VERSION "HNNBNNNYNNNNNNNNNNNNNNNNNNNNNNNNNNNNNNNNNN/4/%%%/4/'%**4NNN///"

NS_ :

BS_:

BU_: BAP_Tester BCM Gateway_Max TSGGen3_BFS TSGGen3_FS TSGGen3_HBFS TSGGen3_HFS WLC_01_CFD

BO_ 1031 PLA_04: 8 Gateway_Max
 SG_ PLA_04_CRC : 0|8@1+ (1,0) [0|255] ""  BCM
 SG_ PLA_04_BZ : 8|4@1+ (1,0) [0|15] ""  BCM
 SG_ PLAIPA_PaCo_ParkingSlots_02 : 12|4@1+ (1.0,0.0) [0.0|15] ""  Vector__XXX
 SG_ RA_PaCo_MainState : 19|3@1+ (1.0,0.0) [0.0|7] ""  Vector__XXX
 SG_ RA_PaCo_FunctionState : 22|4@1+ (1.0,0.0) [0.0|15] ""  Vector__XXX
 SG_ RA_PaCo_InterventionPossible : 26|3@1+ (1.0,0.0) [0.0|7] ""  Vector__XXX
 SG_ RA_PaCo_UnavailableReason : 29|4@1+ (1.0,0.0) [0.0|15] ""  Vector__XXX
 SG_ PLAIPA_PaCo_RemoteActivatable : 33|3@1+ (1.0,0.0) [0.0|7] ""  Vector__XXX
 SG_ PLAIPA_PaCo_GarageActivatable : 36|1@1+ (1.0,0.0) [0.0|1] ""  Vector__XXX
 SG_ RPA_Anf_Sonder_Funktion_Status : 37|3@1+ (1.0,0.0) [0.0|7] ""  BCM
 SG_ RPA_Anf_Sonder_Klemme_15 : 40|2@1+ (1.0,0.0) [0.0|3] ""  BCM
 SG_ RPA_Anf_WFS_Freigabe : 42|2@1+ (1.0,0.0) [0.0|3] ""  BCM
 SG_ PLAIPA_PaCo_SwitchPossible : 44|1@1+ (1.0,0.0) [0.0|1] ""  Vector__XXX
 SG_ PLAIPA_PaCo_ParkingSlots : 45|3@1+ (1.0,0.0) [0.0|7] ""  Vector__XXX
 SG_ PLAIPA_PaCo_UnavailableReason : 48|4@1+ (1.0,0.0) [0.0|15] ""  Vector__XXX
 SG_ PLAIPA_PaCo_InterventionPossible : 52|1@1+ (1.0,0.0) [0.0|1] ""  Vector__XXX
 SG_ PLAIPA_PaCo_MainState : 53|3@1+ (1.0,0.0) [0.0|7] ""  Vector__XXX
 SG_ PLAIPA_PaCo_FunctionState : 56|5@1+ (1.0,0.0) [0.0|31] ""  Vector__XXX
 SG_ PLAIPA_PaCo_PLEPossible : 61|1@1+ (1.0,0.0) [0.0|1] ""  Vector__XXX
 SG_ PLAIPA_PaCo_Button : 62|2@1+ (1.0,0.0) [0.0|3] ""  Vector__XXX

BO_ 319 PreCrash_02: 8 Gateway_Max
 SG_ PreCrash_Charisma_FahrPr : 12|4@1+ (1.0,0.0) [0.0|15] ""  Vector__XXX
 SG_ PreCrash_Charisma_Status : 16|2@1+ (1.0,0.0) [0.0|3] ""  Vector__XXX
 SG_ PreCrash_Schiebedach_schliessen : 18|1@1+ (1.0,0.0) [0.0|1] ""  Vector__XXX
 SG_ PreCrash_Fenster_schliessen : 19|1@1+ (1.0,0.0) [0.0|1] ""  TSGGen3_BFS,TSGGen3_FS,TSGGen3_HBFS,TSGGen3_HFS
 SG_ PreCrash_Blinken : 20|3@1+ (1.0,0.0) [0.0|7] ""  BCM
 SG_ SC_PreSense_FCWP : 23|1@1+ (1.0,0.0) [0.0|1] ""  Vector__XXX
 SG_ PreCrash_Tueren_Verriegeln : 24|1@1+ (1.0,0.0) [0.0|1] ""  BCM,TSGGen3_BFS,TSGGen3_FS,TSGGen3_HBFS,TSGGen3_HFS
 SG_ PreCrash_FS_Laengsverstellung : 25|1@1+ (1.0,0.0) [0.0|1] ""  Vector__XXX
 SG_ PreCrash_Anforderung_AFR : 26|3@1+ (1.0,0.0) [0.0|7] ""  Vector__XXX
 SG_ SC_PreCrash_LED : 29|2@1+ (1.0,0.0) [0.0|3] ""  Vector__XXX
 SG_ PreCrash_FS_Pneumatik_ansteuern : 31|1@1+ (1.0,0.0) [0.0|1] ""  BCM
 SG_ PreCrash_BFS_Pneumatik_ansteuern : 32|1@1+ (1.0,0.0) [0.0|1] ""  BCM
 SG_ PreCrash_Fo_Pneumatik_ansteuern : 33|1@1+ (1.0,0.0) [0.0|1] ""  Vector__XXX
 SG_ PreCrash_FS_Sitzlehne_verfahren : 34|3@1+ (1.0,0.0) [0.0|7] ""  Vector__XXX
 SG_ PreCrash_BFS_Sitzlehne_verfahren : 37|3@1+ (1.0,0.0) [0.0|7] ""  Vector__XXX
 SG_ PreCrash_Fo_Sitzlehne_verfahren : 40|3@1+ (1.0,0.0) [0.0|7] ""  Vector__XXX
 SG_ PreCrash_FS_KSV_verfahren : 43|4@1+ (1.0,0.0) [0.0|15] ""  Vector__XXX
 SG_ PreCrash_BFS_KSV_verfahren : 47|4@1+ (1.0,0.0) [0.0|15] ""  Vector__XXX
 SG_ PreCrash_Fo_KSV_verfahren : 51|4@1+ (1.0,0.0) [0.0|15] ""  Vector__XXX
 SG_ PreCrash_BFS_Laengsverstellung : 55|1@1+ (1.0,0.0) [0.0|1] ""  Vector__XXX
 SG_ SC_PreCrash_Warnung : 56|4@1+ (1.0,0.0) [0.0|15] ""  Vector__XXX
 SG_ SC_PreCrash_Texte : 60|4@1+ (1.0,0.0) [0.0|15] ""  Vector__XXX

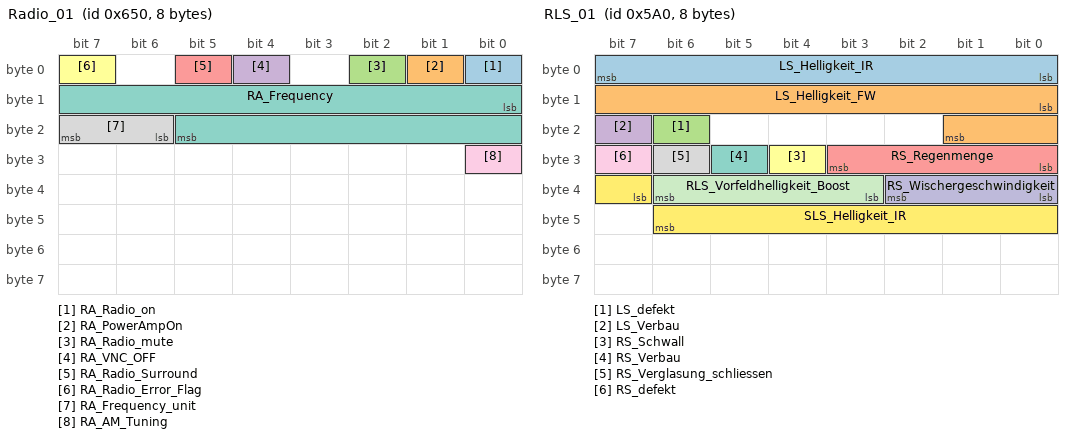
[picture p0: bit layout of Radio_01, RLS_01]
BO_ 1616 Radio_01: 8 Gateway_Max
 SG_ RA_Radio_on : 0|1@1+ (1,0) [0|1] ""  BCM
 SG_ RA_PowerAmpOn : 1|1@1+ (1,0) [0|1] ""  BCM
 SG_ RA_Radio_mute : 2|1@1+ (1,0) [0|1] ""  BCM
 SG_ RA_VNC_OFF : 4|1@1+ (1,0) [0|1] ""  BCM
 SG_ RA_Radio_Surround : 5|1@1+ (1,0) [0|1] ""  BCM
 SG_ RA_Radio_Error_Flag : 7|1@1+ (1.0,0.0) [0.0|1] ""  BCM
 SG_ RA_Frequency : 8|14@1+ (1,0) [0|16383] "Unit_None"  BCM,TSGGen3_BFS,TSGGen3_FS,TSGGen3_HBFS,TSGGen3_HFS,WLC_01_CFD
 SG_ RA_Frequency_unit : 22|2@1+ (1.0,0.0) [0.0|3] ""  BCM,TSGGen3_BFS,TSGGen3_FS,TSGGen3_HBFS,TSGGen3_HFS,WLC_01_CFD
 SG_ RA_AM_Tuning : 24|1@1+ (1.0,0.0) [0.0|1] ""  BCM,TSGGen3_BFS,TSGGen3_FS,TSGGen3_HBFS,TSGGen3_HFS,WLC_01_CFD

BO_ 695 RCTA_01: 8 Gateway_Max
 SG_ RCTA_01_CRC : 0|8@1+ (1,0) [0|255] ""  Vector__XXX
 SG_ RCTA_01_BZ : 8|4@1+ (1,0) [0|15] ""  Vector__XXX
 SG_ RCTA_PaCo_MainState : 12|3@1+ (1.0,0.0) [0.0|7] ""  Vector__XXX
 SG_ RCTA_Status_FoD : 22|2@1+ (1.0,0.0) [0.0|3] ""  Vector__XXX
 SG_ RCTA_PaCo_BrakeIntervention : 24|2@1+ (1.0,0.0) [0.0|3] ""  Vector__XXX
 SG_ RCTA_PaCo_UnavailableReason : 26|3@1+ (1.0,0.0) [0.0|7] ""  Vector__XXX
 SG_ RCTA_Anf_Warnruck : 29|2@1+ (1.0,0.0) [0.0|3] ""  Vector__XXX
 SG_ RCTA_Modus : 31|3@1+ (1.0,0.0) [0.0|7] ""  Vector__XXX
 SG_ RCTA_Kritikalitaetslevel_rechts : 34|3@1+ (1.0,0.0) [0.0|7] ""  BCM
 SG_ RCTA_Kritikalitaetslevel_links : 37|3@1+ (1.0,0.0) [0.0|7] ""  BCM
 SG_ RCTA_Info_rechts : 40|3@1+ (1.0,0.0) [0.0|7] ""  Vector__XXX
 SG_ RCTA_Anforderung_HMS : 43|3@1+ (1.0,0.0) [0.0|7] ""  Vector__XXX
 SG_ RCTA_Bremsruck_Anforderung : 46|1@1+ (1.0,0.0) [0.0|1] ""  Vector__XXX
 SG_ RCTA_Bremsruck_Freigabe : 47|1@1+ (1.0,0.0) [0.0|1] ""  Vector__XXX
 SG_ RCTA_Info_links : 48|3@1+ (1.0,0.0) [0.0|7] ""  Vector__XXX
 SG_ RCTA_PaCo_BrakingPossible : 51|1@1+ (1.0,0.0) [0.0|1] ""  Vector__XXX
 SG_ RCTA_Status : 52|2@1+ (1.0,0.0) [0.0|3] ""  Vector__XXX
 SG_ RCTA_Warnton : 54|1@1+ (1.0,0.0) [0.0|1] ""  Vector__XXX
 SG_ RCTA_Notbremsung_Freigabe : 55|1@1+ (1.0,0.0) [0.0|1] ""  Vector__XXX
 SG_ RCTA_Notbremsung_Anforderung : 56|8@1+ (0.078,-19.812) [-19.734|0.000] "Unit_MeterPerSeconSquar"  Vector__XXX

BO_ 1711 Rear_View_01: 8 Gateway_Max
 SG_ RV_Video_on : 0|1@1+ (1.0,0.0) [0.0|1] ""  Vector__XXX
 SG_ RV_Dark_Screen : 1|1@1+ (1.0,0.0) [0.0|1] ""  Vector__XXX
 SG_ RV_HMI_Mode : 2|2@1+ (1.0,0.0) [0.0|3] ""  Vector__XXX
 SG_ RV_GL_side : 4|2@1+ (1.0,0.0) [0.0|3] ""  Vector__XXX
 SG_ RV_System_aktiv : 6|1@1+ (1.0,0.0) [0.0|1] ""  Vector__XXX
 SG_ RV_Reinigung_Anf : 7|1@1+ (1.0,0.0) [0.0|1] ""  BCM
 SG_ RV_Settings_enabled : 8|1@1+ (1.0,0.0) [0.0|1] ""  Vector__XXX
 SG_ RV_Menu_Item : 9|2@1+ (1.0,0.0) [0.0|3] ""  Vector__XXX
 SG_ SV_Video_on : 11|1@1+ (1.0,0.0) [0.0|1] ""  Vector__XXX
 SG_ RV_Calib_Fehler : 12|1@1+ (1.0,0.0) [0.0|1] ""  Vector__XXX
 SG_ RV_GL_Trailer_connect : 13|1@1+ (1.0,0.0) [0.0|1] ""  Vector__XXX
 SG_ RV_GL_Trunk_open : 14|1@1+ (1.0,0.0) [0.0|1] ""  Vector__XXX
 SG_ RV_GL_LWS_Fehler : 15|1@1+ (1.0,0.0) [0.0|1] ""  Vector__XXX
 SG_ RV_Helligkeit : 16|7@1+ (1,0) [0|100] "Unit_PerCent"  Vector__XXX
 SG_ ZFAS_Umfeldbeleuchtung_Anf : 23|1@1+ (1.0,0.0) [0.0|1] ""  Vector__XXX
 SG_ RV_Kontrast : 24|7@1+ (1,0) [0|100] "Unit_PerCent"  Vector__XXX
 SG_ RV_Farbe : 32|7@1+ (1,0) [0|100] "Unit_PerCent"  Vector__XXX

BO_ 2264486920 RHP_01: 32 Gateway_Max
 SG_ RHP_01_CRC : 0|8@1+ (1,0) [0|255] ""  BCM
 SG_ RHP_01_BZ : 8|4@1+ (1,0) [0|15] ""  BCM
 SG_ RHP_QFK_AnfStat : 12|4@1+ (1.0,0.0) [0.0|15] ""  Vector__XXX
 SG_ RHP_QFK_Spuerb : 16|8@1+ (0.4,0) [0.0|100.0] "Unit_PerCent"  Vector__XXX
 SG_ RHP_QFK_KruemmSoll : 24|15@1+ (0.0000067,0) [0E-7|0.2195389] "Unit_MeterInver"  Vector__XXX
 SG_ RHP_TV_Trigger : 39|1@1+ (1.0,0.0) [0.0|1] ""  Vector__XXX
 SG_ RHP_QFK_Signal1 : 40|10@1+ (1,0) [0|1023] ""  Vector__XXX
 SG_ RHP_QFK_Art1 : 50|3@1+ (1,0) [0|7] ""  Vector__XXX
 SG_ RHP_QFK_Art2 : 53|3@1+ (1,0) [0|7] ""  Vector__XXX
 SG_ RHP_QFK_Signal2 : 56|10@1+ (1,0) [0|1023] ""  Vector__XXX
 SG_ RHP_QFK_KruemmSoll_VZ : 66|1@1+ (1.0,0.0) [0.0|1] ""  Vector__XXX
 SG_ RHP_Status_Long : 67|3@1+ (1.0,0.0) [0.0|7] ""  Vector__XXX
 SG_ RHP_Ruckfreigabe : 70|1@1+ (1.0,0.0) [0.0|1] ""  Vector__XXX
 SG_ RHP_Warnruckeln_Anf : 71|3@1+ (1.0,0.0) [0.0|7] ""  Vector__XXX
 SG_ RHP_Anf_ASIL : 74|3@1+ (1.0,0.0) [0.0|7] ""  Vector__XXX
 SG_ RHP_Anforderung_HMS : 77|3@1+ (1.0,0.0) [0.0|7] ""  Vector__XXX
 SG_ RHP_pos_Sollbeschl_Grad : 80|8@1+ (0.05,0) [0.00|12.75] "Unit_MeterPerCubicSecon"  Vector__XXX
 SG_ RHP_neg_Sollbeschl_Grad : 88|8@1+ (0.05,0) [0.00|12.75] "Unit_MeterPerCubicSecon"  Vector__XXX
 SG_ RHP_Sollbeschleunigung : 96|11@1+ (0.005,-7.22) [-7.220|3.005] "Unit_MeterPerSeconSquar"  Vector__XXX
 SG_ RHP_zul_Regelabw_oben : 107|5@1+ (0.0625,0) [0.0000|1.9375] "Unit_MeterPerSeconSquar"  Vector__XXX
 SG_ RHP_zul_Regelabw_unten : 112|6@1+ (0.024,0) [0.000|1.512] "Unit_MeterPerSeconSquar"  Vector__XXX
 SG_ RHP_TSK_Status : 118|3@1+ (1.0,0.0) [0.0|7] ""  Vector__XXX
 SG_ RHP_Minimale_Bremsung : 121|1@1+ (1.0,0.0) [0.0|1] ""  Vector__XXX
 SG_ RHP_Uss_Anforderung : 122|2@1+ (1.0,0.0) [0.0|3] ""  Vector__XXX
 SG_ RHP_Verz_Anf : 124|10@1+ (0.024,-20.016) [-20.016|4.512] "Unit_MeterPerSeconSquar"  Vector__XXX
 SG_ RHP_Verz_Freigabe : 134|1@1+ (1.0,0.0) [0.0|1] ""  Vector__XXX
 SG_ RHP_Status_Lat : 135|3@1+ (1.0,0.0) [0.0|7] ""  Vector__XXX
 SG_ RHP_StartStopp_Info : 138|2@1+ (1.0,0.0) [0.0|3] ""  Vector__XXX
 SG_ RHP_nachtr_Stopp_Anf : 140|1@1+ (1.0,0.0) [0.0|1] ""  Vector__XXX
 SG_ RHP_Freilaufstrategie_TSK : 141|1@1+ (1.0,0.0) [0.0|1] ""  Vector__XXX
 SG_ RHP_SCAM_HeatingRequest : 142|2@1+ (1.0,0.0) [0.0|3] ""  Vector__XXX
 SG_ RHP_Fahrzeughupe_Anf : 144|1@1+ (1.0,0.0) [0.0|1] ""  BCM
 SG_ RHP_HOS : 145|2@1+ (1.0,0.0) [0.0|3] ""  Vector__XXX
 SG_ RHP_Status_Function : 147|3@1+ (1.0,0.0) [0.0|7] ""  Vector__XXX
 SG_ RHP_EA_AnfStat : 150|2@1+ (1.0,0.0) [0.0|3] ""  Vector__XXX
 SG_ RHP_QFK_KrSoll : 152|16@1+ (0.0000067,0) [0E-7|0.4390845] "Unit_MeterInver"  Vector__XXX
 SG_ RHP_QFK_KrSoll_VZ : 168|1@1+ (1.0,0.0) [0.0|1] ""  Vector__XXX
 SG_ RHP_Warnblinken : 169|1@1+ (1.0,0.0) [0.0|1] ""  BCM
 SG_ RHP_Innenraumlicht_Anf : 170|1@1+ (1.0,0.0) [0.0|1] ""  BCM
 SG_ RHP_Spurwechsel_Ready : 171|3@1+ (1.0,0.0) [0.0|7] ""  BCM
 SG_ RHP_RBF_Available : 174|2@1+ (1.0,0.0) [0.0|3] ""  Vector__XXX
 SG_ RHP_PreCrash_Anf : 176|3@1+ (1.0,0.0) [0.0|7] ""  Vector__XXX
 SG_ RHP_EA_PreCrash : 179|3@1+ (1.0,0.0) [0.0|7] ""  Vector__XXX
 SG_ RHP_Parking_St : 182|2@1+ (1.0,0.0) [0.0|3] ""  Vector__XXX
 SG_ RHP_EA_Innenraumlicht : 184|1@1+ (1.0,0.0) [0.0|1] ""  Vector__XXX
 SG_ RHP_EA_eCall : 185|1@1+ (1.0,0.0) [0.0|1] ""  Vector__XXX
 SG_ RHP_OPSEnable : 186|2@1+ (1.0,0.0) [0.0|3] ""  Vector__XXX
 SG_ RHP_eCall_Anf : 188|1@1+ (1.0,0.0) [0.0|1] ""  Vector__XXX
 SG_ RHP_EA_Tueren : 189|1@1+ (1.0,0.0) [0.0|1] ""  Vector__XXX

BO_ 1440 RLS_01: 8 BCM
 SG_ LS_Helligkeit_IR : 0|8@1+ (400,0) [0|101200] "Unit_Lux"  Gateway_Max
 SG_ LS_Helligkeit_FW : 8|10@1+ (6,0) [0|6126] "Unit_Lux"  Gateway_Max
 SG_ LS_defekt : 22|1@1+ (1.0,0.0) [0.0|1] ""  Gateway_Max
 SG_ LS_Verbau : 23|1@1+ (1.0,0.0) [0.0|1] ""  Gateway_Max
 SG_ RS_Regenmenge : 24|4@1+ (1.0,0.0) [0.0|15] ""  Gateway_Max
 SG_ RS_Schwall : 28|1@1+ (1.0,0.0) [0.0|1] ""  Gateway_Max
 SG_ RS_Verbau : 29|1@1+ (1.0,0.0) [0.0|1] ""  Gateway_Max
 SG_ RS_Verglasung_schliessen : 30|1@1+ (1.0,0.0) [0.0|1] ""  Gateway_Max,TSGGen3_BFS,TSGGen3_FS,TSGGen3_HBFS,TSGGen3_HFS
 SG_ RS_defekt : 31|1@1+ (1.0,0.0) [0.0|1] ""  Gateway_Max,TSGGen3_BFS,TSGGen3_FS,TSGGen3_HBFS,TSGGen3_HFS
 SG_ RS_Wischergeschwindigkeit : 32|3@1+ (1.0,0.0) [0.0|7] ""  Gateway_Max
 SG_ RLS_Vorfeldhelligkeit_Boost : 35|4@1+ (1.0,0.0) [0.0|15] ""  Gateway_Max
 SG_ SLS_Helligkeit_IR : 39|8@1+ (250,0) [0|7000] "Unit_Lux"  Gateway_Max

BO_ 1504 SAD_01: 8 Gateway_Max
 SG_ MD1_Position : 8|7@1+ (1,0) [0|100] "Unit_PerCent"  BCM
 SG_ MD1_Lage : 15|1@1+ (1.0,0.0) [0.0|1] ""  BCM
 SG_ MD3_Position : 16|7@1+ (1,0) [0|100] "Unit_PerCent"  BCM
 SG_ MD3_Lage : 23|1@1+ (1.0,0.0) [0.0|1] ""  BCM
 SG_ MRollo_Position : 24|7@1+ (1,0) [0|100] "Unit_PerCent"  BCM
 SG_ MRollo_Lage : 31|1@1+ (1.0,0.0) [0.0|1] ""  BCM
 SG_ SAD_normiert : 32|1@1+ (1.0,0.0) [0.0|1] ""  BCM
 SG_ SAD_Thermoschutz : 33|1@1+ (1.0,0.0) [0.0|1] ""  BCM
 SG_ SAD_UEKB_aktiv : 34|1@1+ (1.0,0.0) [0.0|1] ""  BCM
 SG_ Rollo_normiert : 35|1@1+ (1.0,0.0) [0.0|1] ""  BCM
 SG_ Rollo_Thermoschutz : 36|1@1+ (1.0,0.0) [0.0|1] ""  BCM
 SG_ Rollo_UEKB_aktiv : 37|1@1+ (1.0,0.0) [0.0|1] ""  BCM
 SG_ SAD_Taster_Deckel_hi : 38|4@1+ (1.0,0.0) [0.0|15] ""  BCM
 SG_ SAD_Taster_Deckel_vo : 42|4@1+ (1.0,0.0) [0.0|15] ""  BCM
 SG_ SAD_Taster_Rollo_hi : 46|3@1+ (1.0,0.0) [0.0|7] ""  BCM
 SG_ SAD_Taster_Rollo_vo : 49|3@1+ (1.0,0.0) [0.0|7] ""  BCM
 SG_ SAD_Anf_ESC_Zuschaltung : 52|1@1+ (1.0,0.0) [0.0|1] ""  BCM

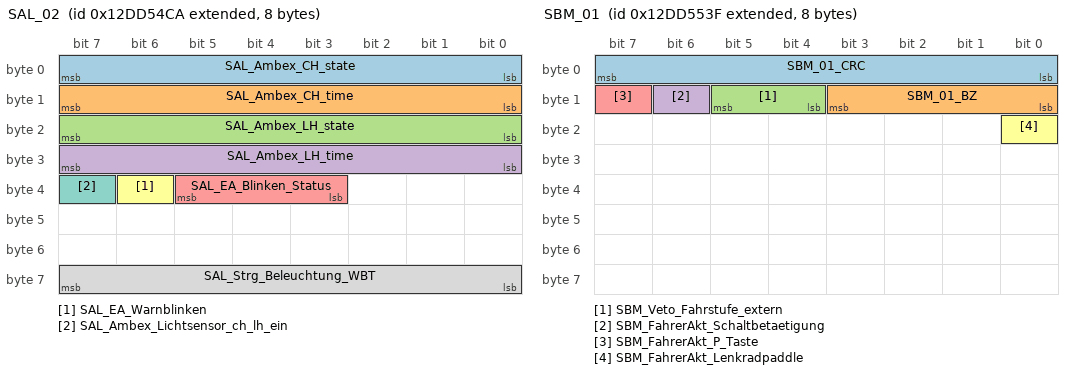
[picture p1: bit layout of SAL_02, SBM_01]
BO_ 2463978698 SAL_02: 8 BCM
 SG_ SAL_Ambex_CH_state : 0|8@1+ (1.0,0.0) [0.0|255] ""  Gateway_Max
 SG_ SAL_Ambex_CH_time : 8|8@1+ (1,0) [0|90] "Unit_Secon"  Gateway_Max
 SG_ SAL_Ambex_LH_state : 16|8@1+ (1.0,0.0) [0.0|255] ""  Gateway_Max
 SG_ SAL_Ambex_LH_time : 24|8@1+ (1,0) [0|90] "Unit_Secon"  Gateway_Max
 SG_ SAL_EA_Blinken_Status : 35|3@1+ (1.0,0.0) [0.0|7] ""  Gateway_Max
 SG_ SAL_EA_Warnblinken : 38|1@1+ (1.0,0.0) [0.0|1] ""  Gateway_Max
 SG_ SAL_Ambex_Lichtsensor_ch_lh_ein : 39|1@1+ (1.0,0.0) [0.0|1] ""  Gateway_Max
 SG_ SAL_Strg_Beleuchtung_WBT : 56|8@1+ (0.5,0) [0.0|100.0] "Unit_PerCent"  Gateway_Max

BO_ 2463978815 SBM_01: 8 Gateway_Max
 SG_ SBM_01_CRC : 0|8@1+ (1,0) [0|255] ""  BCM
 SG_ SBM_01_BZ : 8|4@1+ (1,0) [0|15] ""  BCM
 SG_ SBM_Veto_Fahrstufe_extern : 12|2@1+ (1.0,0.0) [0.0|3] ""  Vector__XXX
 SG_ SBM_FahrerAkt_Schaltbetaetigung : 14|1@1+ (1.0,0.0) [0.0|1] ""  BCM
 SG_ SBM_FahrerAkt_P_Taste : 15|1@1+ (1.0,0.0) [0.0|1] ""  BCM
 SG_ SBM_FahrerAkt_Lenkradpaddle : 16|1@1+ (1.0,0.0) [0.0|1] ""  Vector__XXX

BO_ 1522 Sensorik_Dimmung_01: 2 Gateway_Max
 SG_ KBI_Phototransistor : 0|8@1+ (1,0) [0|253] ""  BCM
 SG_ KBI_Dimmpoti : 8|7@1+ (1,0) [0|100] "Unit_PerCent"  Vector__XXX

BO_ 1167 Service_Key_01: 8 Gateway_Max
 SG_ SK1_MUX M  : 0|8@1+ (1.0,0.0) [0.0|255] ""  BCM
 SG_ SK1_Key_Data_1 m0  : 8|56@1+ (1.0,0.0) [0.0|72057594037927935] ""  BCM
 SG_ SK1_Key_Data_2 m1  : 8|56@1+ (1.0,0.0) [0.0|72057594037927935] ""  BCM
 SG_ SK1_Key_Data_3 m2  : 8|56@1+ (1.0,0.0) [0.0|72057594037927935] ""  BCM
 SG_ SK1_Key_Data_4 m3  : 8|56@1+ (1.0,0.0) [0.0|72057594037927935] ""  BCM
 SG_ SK1_Key_Data_5 m4  : 8|56@1+ (1.0,0.0) [0.0|72057594037927935] ""  BCM
 SG_ SK1_Key_Data_6 m5  : 8|56@1+ (1.0,0.0) [0.0|72057594037927935] ""  BCM
 SG_ SK1_Key_Data_7 m6  : 8|56@1+ (1.0,0.0) [0.0|72057594037927935] ""  BCM
 SG_ SK1_Key_Data_8 m7  : 8|56@1+ (1.0,0.0) [0.0|72057594037927935] ""  BCM
 SG_ SK1_Key_Data_9 m8  : 8|56@1+ (1.0,0.0) [0.0|72057594037927935] ""  BCM
 SG_ SK1_Key_Data_10 m9  : 8|56@1+ (1.0,0.0) [0.0|72057594037927935] ""  Vector__XXX

BO_ 201 SM_Parken_01: 8 BCM
 SG_ SM_Parken_Touch_PosX : 0|3@1+ (1.0,0.0) [0.0|7] ""  Gateway_Max
 SG_ SM_Parken_Touch_PosY : 3|5@1+ (1.0,0.0) [0.0|31] ""  Gateway_Max
 SG_ SM_ARA_Gangwahl : 8|3@1+ (1.0,0.0) [0.0|7] ""  Gateway_Max
 SG_ SM_Fehlerstatus : 11|1@1+ (1.0,0.0) [0.0|1] ""  Gateway_Max
 SG_ SM_ARA_Start : 12|1@1+ (1.0,0.0) [0.0|1] ""  Gateway_Max
 SG_ SM_ARA_Trajektorienmodus : 13|1@1+ (1.0,0.0) [0.0|1] ""  Gateway_Max
 SG_ SM_AFR_Verbindungsstatus : 14|1@1+ (1.0,0.0) [0.0|1] ""  Gateway_Max
 SG_ SM_Anlernstatus : 15|1@1+ (1.0,0.0) [0.0|1] ""  Gateway_Max
 SG_ SM_Parken_01_Sendestatus : 20|1@1+ (1.0,0.0) [0.0|1] ""  Gateway_Max
 SG_ SM_Parken_AngefordertesRemoteSys : 21|2@1+ (1.0,0.0) [0.0|3] ""  Gateway_Max
 SG_ SM_Parken_Motorstart_Anf : 23|1@1+ (1.0,0.0) [0.0|1] ""  Gateway_Max
 SG_ SM_AFR_Standfkt_Anf : 24|3@1+ (1.0,0.0) [0.0|7] ""  Gateway_Max
 SG_ SM_ARA_Nothalt : 27|1@1+ (1.0,0.0) [0.0|1] ""  Gateway_Max
 SG_ SM_App_Sperrzustand : 28|2@1+ (1.0,0.0) [0.0|3] ""  Gateway_Max
 SG_ SM_Parken_Manoever : 30|2@1+ (1.0,0.0) [0.0|3] ""  Gateway_Max
 SG_ SM_Parken_Szenario : 32|3@1+ (1.0,0.0) [0.0|7] ""  Gateway_Max
 SG_ SM_Parken_Seite : 35|2@1+ (1.0,0.0) [0.0|3] ""  Gateway_Max
 SG_ SM_Parken_Richtung : 37|2@1+ (1.0,0.0) [0.0|3] ""  Gateway_Max
 SG_ SM_ARA_Status_Steuersignal : 39|1@1+ (1.0,0.0) [0.0|1] ""  Gateway_Max
 SG_ SM_ARA_Knickwinkel_Soll : 40|8@1+ (1,-127) [-127|124] "Unit_DegreOfArc"  Gateway_Max
 SG_ SM_ARA_Gaspedal : 48|4@1+ (1,0) [0|15] "Unit_None"  Gateway_Max
 SG_ SM_Parken_Verbindungsstatus : 52|4@1+ (1.0,0.0) [0.0|15] ""  Gateway_Max
 SG_ SM_Parken_Kommando : 56|2@1+ (1.0,0.0) [0.0|3] ""  Gateway_Max
 SG_ SM_Parken_Alive : 58|4@1+ (1,0) [0|15] "Unit_None"  Gateway_Max
 SG_ SM_Parken_Kommando_invers : 62|2@1+ (1.0,0.0) [0.0|3] ""  Gateway_Max

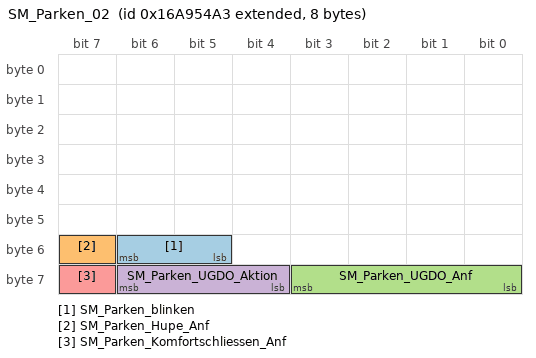
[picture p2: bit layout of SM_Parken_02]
BO_ 2527679651 SM_Parken_02: 8 BCM
 SG_ SM_Parken_blinken : 53|2@1+ (1.0,0.0) [0.0|3] ""  Gateway_Max
 SG_ SM_Parken_Hupe_Anf : 55|1@1+ (1.0,0.0) [0.0|1] ""  Gateway_Max
 SG_ SM_Parken_UGDO_Anf : 56|4@1+ (1.0,0.0) [0.0|15] ""  Gateway_Max
 SG_ SM_Parken_UGDO_Aktion : 60|3@1+ (1.0,0.0) [0.0|7] ""  Gateway_Max
 SG_ SM_Parken_Komfortschliessen_Anf : 63|1@1+ (1.0,0.0) [0.0|1] ""  Gateway_Max

BO_ 980 SMLS_01: 8 BCM
 SG_ SMLS_01_CRC : 0|8@1+ (1,0) [0|255] ""  BCM,Gateway_Max
 SG_ SMLS_01_BZ : 8|4@1+ (1,0) [0|15] ""  BCM,Gateway_Max
 SG_ BH_Blinker_li : 12|1@1+ (1.0,0.0) [0.0|1] ""  BCM,Gateway_Max
 SG_ BH_Blinker_re : 13|1@1+ (1.0,0.0) [0.0|1] ""  BCM,Gateway_Max
 SG_ BH_Lichthupe : 14|1@1+ (1.0,0.0) [0.0|1] ""  BCM,Gateway_Max
 SG_ BH_Fernlicht : 15|1@1+ (1.0,0.0) [0.0|1] ""  BCM,Gateway_Max
 SG_ WH_Tipwischen : 16|1@1+ (1.0,0.0) [0.0|1] ""  BCM,Gateway_Max
 SG_ WH_Intervall : 17|1@1+ (1.0,0.0) [0.0|1] ""  BCM,Gateway_Max
 SG_ WH_WischerStufe1 : 18|1@1+ (1.0,0.0) [0.0|1] ""  BCM,Gateway_Max
 SG_ WH_WischerStufe2 : 19|1@1+ (1.0,0.0) [0.0|1] ""  BCM,Gateway_Max
 SG_ WH_Frontwaschen : 20|1@1+ (1.0,0.0) [0.0|1] ""  BCM,Gateway_Max
 SG_ WH_Heckintervall : 21|1@1+ (1.0,0.0) [0.0|1] ""  BCM,Gateway_Max
 SG_ WH_Heckwaschen : 22|1@1+ (1.0,0.0) [0.0|1] ""  BCM,Gateway_Max
 SG_ WH_Intervallstufen : 23|4@1+ (1.0,0.0) [0.0|15] ""  BCM,Gateway_Max
 SG_ FAS_Taster : 27|1@1+ (1.0,0.0) [0.0|1] ""  BCM,Gateway_Max
 SG_ FAS_Taster_Fehler : 28|1@1+ (1.0,0.0) [0.0|1] ""  BCM,Gateway_Max
 SG_ SMLS_Hupe : 29|1@1+ (1.0,0.0) [0.0|1] ""  BCM,Gateway_Max
 SG_ LRH_On_Off : 30|2@1+ (1.0,0.0) [0.0|3] ""  BCM,Gateway_Max
 SG_ LSS_Tastencode : 32|8@1+ (1.0,0.0) [0.0|255] ""  BCM,Gateway_Max
 SG_ LRH_aktiv : 40|1@1+ (1.0,0.0) [0.0|1] ""  BCM,Gateway_Max
 SG_ SMLS_P_verriegelt : 41|2@1+ (1.0,0.0) [0.0|3] ""  BCM,Gateway_Max
 SG_ SMLS_P_verriegelt_plausibel : 43|1@1+ (1.0,0.0) [0.0|1] ""  BCM,Gateway_Max
 SG_ WH_SRA : 44|1@1+ (1.0,0.0) [0.0|1] ""  BCM,Gateway_Max
 SG_ WH_Wischer_Fehler : 45|1@1+ (1.0,0.0) [0.0|1] ""  BCM,Gateway_Max
 SG_ BH_Blinker_Fehler : 46|1@1+ (1.0,0.0) [0.0|1] ""  BCM,Gateway_Max
 SG_ SMLS_PTT : 47|1@1+ (1.0,0.0) [0.0|1] ""  BCM,Gateway_Max
 SG_ WH_Tipwischen_lang : 48|1@1+ (1.0,0.0) [0.0|1] ""  BCM,Gateway_Max

BO_ 2464161806 SOK_FoD_BCM_Req_Chal_06: 8 BCM
 SG_ SOK_FoD_BCM1_Req_Challenge : 0|64@1+ (1,0) [0|18446744073709551615] "Unit_None"  Gateway_Max

BO_ 2464296974 SOK_FoD_BCM_Resp_Chal_06: 8 Gateway_Max
 SG_ SOK_FoD_BCM1_Resp_Challenge : 0|64@1+ (1,0) [0|18446744073709551615] "Unit_None"  BCM

BO_ 2589283756 SOK_NoAuthenticTime_01: 8 Gateway_Max
 SG_ SOK_ungeschuetzte_Zeit : 8|56@1+ (1,0) [1|72057594037927935] "Unit_None"  BCM,TSGGen3_BFS,TSGGen3_FS,TSGGen3_HBFS,TSGGen3_HFS

BO_ 2464153614 SOK_Zeit_BCM_Chal_01: 8 BCM
 SG_ SOK_Zeit_BCM_Challenge : 0|64@1+ (1,0) [0|18446744073709551615] "Unit_None"  Gateway_Max

BO_ 2464284686 SOK_Zeit_BCM_Signatur_Resp_01: 8 Gateway_Max
 SG_ SOK_Zeit_BCM_Signatur : 0|64@1+ (1,0) [0|18446744073709551615] ""  BCM

BO_ 2464288782 SOK_Zeit_BCM_Zeit_Resp_01: 8 Gateway_Max
 SG_ SOK_Zeit_BCM_Zeit : 0|56@1+ (1,0) [0|72057594037927935] "Unit_None"  BCM

BO_ 2464153786 SOK_Zeit_DDA_Chal_01: 8 BCM
 SG_ SOK_Zeit_DDA_Challenge : 0|64@1+ (1,0) [0|18446744073709551615] "Unit_None"  Gateway_Max

BO_ 2464284858 SOK_Zeit_DDA_Signatur_Resp_01: 8 Gateway_Max
 SG_ SOK_Zeit_DDA_Signatur : 0|64@1+ (1,0) [0|18446744073709551615] ""  BCM

BO_ 2464288954 SOK_Zeit_DDA_Zeit_Resp_01: 8 Gateway_Max
 SG_ SOK_Zeit_DDA_Zeit : 0|56@1+ (1,0) [0|72057594037927935] "Unit_None"  BCM

BO_ 2464153675 SOK_Zeit_TSG_BT_Chal_01: 8 TSGGen3_BFS
 SG_ SOK_Zeit_TSG_BT_Challenge : 0|64@1+ (1,0) [0|18446744073709551615] "Unit_None"  Gateway_Max

BO_ 2464284747 SOK_Zeit_TSG_BT_Resp_01: 16 Gateway_Max
 SG_ SOK_Zeit_TSG_BT_Zeit : 0|56@1+ (1,0) [0|72057594037927935] "Unit_None"  TSGGen3_BFS
 SG_ SOK_Zeit_TSG_BT_Signatur : 64|64@1+ (1,0) [0|18446744073709551615] "Unit_None"  TSGGen3_BFS

BO_ 2464153674 SOK_Zeit_TSG_FT_Chal_01: 8 TSGGen3_FS
 SG_ SOK_Zeit_TSG_FT_Challenge : 0|64@1+ (1,0) [0|18446744073709551615] "Unit_None"  Gateway_Max

BO_ 2464284746 SOK_Zeit_TSG_FT_Resp_01: 16 Gateway_Max
 SG_ SOK_Zeit_TSG_FT_Zeit : 0|56@1+ (1,0) [0|72057594037927935] "Unit_None"  TSGGen3_FS
 SG_ SOK_Zeit_TSG_FT_Signatur : 64|64@1+ (1,0) [0|18446744073709551615] "Unit_None"  TSGGen3_FS

BO_ 2464153663 SOK_Zeit_TSG_HBFS_Chal_01: 8 TSGGen3_HBFS
 SG_ SOK_Zeit_TSG_HBFS_Challenge : 0|64@1+ (1,0) [0|18446744073709551615] "Unit_None"  Gateway_Max

BO_ 2464284735 SOK_Zeit_TSG_HBFS_Resp_01: 16 Gateway_Max
 SG_ SOK_Zeit_TSG_HBFS_Zeit : 0|56@1+ (1,0) [0|72057594037927935] "Unit_None"  TSGGen3_HBFS
 SG_ SOK_Zeit_TSG_HBFS_Signatur : 64|64@1+ (1,0) [0|18446744073709551615] "Unit_None"  TSGGen3_HBFS

BO_ 2464153662 SOK_Zeit_TSG_HFS_Chal_01: 8 TSGGen3_HFS
 SG_ SOK_Zeit_TSG_HFS_Challenge : 0|64@1+ (1,0) [0|18446744073709551615] "Unit_None"  Gateway_Max

BO_ 2464284734 SOK_Zeit_TSG_HFS_Resp_01: 16 Gateway_Max
 SG_ SOK_Zeit_TSG_HFS_Zeit : 0|56@1+ (1,0) [0|72057594037927935] "Unit_None"  TSGGen3_HFS
 SG_ SOK_Zeit_TSG_HFS_Signatur : 64|64@1+ (1,0) [0|18446744073709551615] "Unit_None"  TSGGen3_HFS

BO_ 1467 SoSe_01: 8 BCM
 SG_ SoSe_SunInt_2D_Li : 0|8@1+ (5,0) [0|1200] "Unit_WattPerMeterSquar"  Gateway_Max
 SG_ SoSe_SunInt_2D_Re : 8|8@1+ (5,0) [0|1200] "Unit_WattPerMeterSquar"  Gateway_Max

BO_ 1710 Spiegel_01: 8 TSGGen3_FS
 SG_ SP_FT_oben : 0|1@1+ (1.0,0.0) [0.0|1] ""  Gateway_Max
 SG_ SP_FT_unten : 1|1@1+ (1.0,0.0) [0.0|1] ""  Gateway_Max
 SG_ SP_FT_links : 2|1@1+ (1.0,0.0) [0.0|1] ""  Gateway_Max
 SG_ SP_FT_rechts : 3|1@1+ (1.0,0.0) [0.0|1] ""  Gateway_Max
 SG_ SP_BT_oben : 4|1@1+ (1.0,0.0) [0.0|1] ""  Gateway_Max
 SG_ SP_BT_unten : 5|1@1+ (1.0,0.0) [0.0|1] ""  Gateway_Max
 SG_ SP_BT_links : 6|1@1+ (1.0,0.0) [0.0|1] ""  Gateway_Max
 SG_ SP_BT_rechts : 7|1@1+ (1.0,0.0) [0.0|1] ""  Gateway_Max
 SG_ SP_abklappen : 8|1@1+ (1.0,0.0) [0.0|1] ""  Gateway_Max
 SG_ SP_anklappen : 9|1@1+ (1.0,0.0) [0.0|1] ""  Gateway_Max
 SG_ SP_normieren : 10|1@1+ (1.0,0.0) [0.0|1] ""  Gateway_Max
 SG_ SP_Spg_Verstellschalter_Fehler : 11|1@1+ (1.0,0.0) [0.0|1] ""  Gateway_Max
 SG_ SP_Hzg_Taster : 12|1@1+ (1.0,0.0) [0.0|1] ""  Gateway_Max
 SG_ SP_S_oben : 16|1@1+ (1.0,0.0) [0.0|1] ""  Gateway_Max
 SG_ SP_S_unten : 17|1@1+ (1.0,0.0) [0.0|1] ""  Gateway_Max
 SG_ SP_S_links : 18|1@1+ (1.0,0.0) [0.0|1] ""  Gateway_Max
 SG_ SP_S_rechts : 19|1@1+ (1.0,0.0) [0.0|1] ""  Gateway_Max
 SG_ SP_Auswahl_li : 20|1@1+ (1.0,0.0) [0.0|1] ""  Gateway_Max
 SG_ SP_Auswahl_re : 21|1@1+ (1.0,0.0) [0.0|1] ""  Gateway_Max
 SG_ SP_ARA_Status : 22|1@1+ (1.0,0.0) [0.0|1] ""  Gateway_Max
 SG_ SP_S_Klappen : 23|1@1+ (1.0,0.0) [0.0|1] ""  Gateway_Max
 SG_ SP_Verstellschalter_Fehler : 24|1@1+ (1.0,0.0) [0.0|1] ""  Gateway_Max

BO_ 2463978603 SSAM_01: 48 Gateway_Max
 SG_ SSAM_01_CRC : 0|8@1+ (1,0) [0|255] ""  Vector__XXX
 SG_ SSAM_01_BZ : 8|4@1+ (1,0) [0|15] ""  Vector__XXX
 SG_ SSA_HD_Beeper_ansteuern : 12|4@1+ (1.0,0.0) [0.0|15] ""  Vector__XXX
 SG_ SSA_HD_ansteuern : 16|2@1+ (1.0,0.0) [0.0|3] ""  Vector__XXX
 SG_ SSA_Heckrollo_ansteuern : 18|2@1+ (1.0,0.0) [0.0|3] ""  Vector__XXX
 SG_ SSA_LRA_ansteuern : 20|2@1+ (1.0,0.0) [0.0|3] ""  Vector__XXX
 SG_ SSA_SD_Versorgung_ansteuern : 22|2@1+ (1.0,0.0) [0.0|3] ""  Vector__XXX
 SG_ SSA_BFT_ASW_ansteuern : 24|3@1+ (1.0,0.0) [0.0|7] ""  Vector__XXX
 SG_ SSA_HBFT_SSR_ansteuern : 27|2@1+ (1.0,0.0) [0.0|3] ""  Vector__XXX
 SG_ SSA_FT_ZZH_ansteuern : 62|2@1+ (1.0,0.0) [0.0|3] ""  Vector__XXX
 SG_ KFT_FH_BT_hoch : 72|1@1+ (1.0,0.0) [0.0|1] ""  TSGGen3_BFS
 SG_ KFT_FH_BT_tief : 73|1@1+ (1.0,0.0) [0.0|1] ""  TSGGen3_BFS
 SG_ KFT_FH_FT_hoch : 74|1@1+ (1.0,0.0) [0.0|1] ""  TSGGen3_FS
 SG_ KFT_FH_FT_tief : 75|1@1+ (1.0,0.0) [0.0|1] ""  TSGGen3_FS
 SG_ KFT_FH_HBFS_hoch : 76|1@1+ (1.0,0.0) [0.0|1] ""  TSGGen3_HBFS
 SG_ KFT_FH_HBFS_tief : 77|1@1+ (1.0,0.0) [0.0|1] ""  TSGGen3_HBFS
 SG_ KFT_FH_HFS_hoch : 78|1@1+ (1.0,0.0) [0.0|1] ""  TSGGen3_HFS
 SG_ KFT_FH_HFS_tief : 79|1@1+ (1.0,0.0) [0.0|1] ""  TSGGen3_HFS
 SG_ KFT_Rollo_zu : 80|1@1+ (1.0,0.0) [0.0|1] ""  Vector__XXX
 SG_ KFT_Rollo_auf : 81|1@1+ (1.0,0.0) [0.0|1] ""  Vector__XXX
 SG_ KFT_SAD_zu : 82|1@1+ (1.0,0.0) [0.0|1] ""  Vector__XXX
 SG_ KFT_SAD_auf : 83|1@1+ (1.0,0.0) [0.0|1] ""  Vector__XXX
 SG_ KFT_FH_Freigabe : 84|1@1+ (1.0,0.0) [0.0|1] ""  TSGGen3_BFS,TSGGen3_FS,TSGGen3_HBFS,TSGGen3_HFS
 SG_ KFT_Komfortfkt_Freigabe : 85|1@1+ (1.0,0.0) [0.0|1] ""  TSGGen3_BFS,TSGGen3_FS,TSGGen3_HBFS,TSGGen3_HFS
 SG_ KFT_Verdeck_auf : 86|1@1+ (1.0,0.0) [0.0|1] ""  Vector__XXX
 SG_ KFT_Verdeck_zu : 87|1@1+ (1.0,0.0) [0.0|1] ""  Vector__XXX
 SG_ KFT_Verdeck_Freigabe : 88|1@1+ (1.0,0.0) [0.0|1] ""  Vector__XXX
 SG_ SSA_BFT_ASP_Klappung_ansteuern : 89|2@1+ (1.0,0.0) [0.0|3] ""  Vector__XXX
 SG_ SSA_FT_ASW_ansteuern : 91|3@1+ (1.0,0.0) [0.0|7] ""  Vector__XXX
 SG_ SSA_FT_FH_ansteuern : 96|8@1+ (1,0) [0|100] "Unit_PerCent"  TSGGen3_FS
 SG_ SSA_BFT_FH_ansteuern : 104|8@1+ (1,0) [0|100] "Unit_PerCent"  TSGGen3_BFS
 SG_ SSA_BFT_FH_Pos_anfahren : 112|8@1+ (1,0) [0|100] "Unit_PerCent"  Vector__XXX
 SG_ SSA_SAD_Deckel1_ansteuern : 129|7@1+ (1,0) [0|100] "Unit_PerCent"  Vector__XXX
 SG_ SSA_SAD_Rollo1_ansteuern : 136|7@1+ (1,0) [0|100] "Unit_PerCent"  Vector__XXX
 SG_ SSA_Heckrollo_PrivacySAD_Rollo1 : 143|7@1+ (1,0) [0|100] "Unit_PerCent"  Vector__XXX
 SG_ SSA_Heckrollo_PrivacySAD_Rollo2 : 150|7@1+ (1,0) [0|100] "Unit_PerCent"  Vector__XXX
 SG_ Privacy_SAD_Rollo1_ansteuern : 157|7@1+ (1,0) [0|100] "Unit_PerCent"  Vector__XXX
 SG_ Privacy_SAD_Rollo2_ansteuern : 164|7@1+ (1,0) [0|100] "Unit_PerCent"  Vector__XXX
 SG_ SSA_BFT_ASP_SpglGlas_ansteuern : 171|3@1+ (1.0,0.0) [0.0|7] ""  Vector__XXX
 SG_ SSA_FT_ASP_SpglGlas_ansteuern : 174|3@1+ (1.0,0.0) [0.0|7] ""  Vector__XXX
 SG_ SSA_FT_ZV_Ansteuern : 184|8@1+ (1.0,0.0) [0.0|255] ""  Vector__XXX
 SG_ SSA_HBFT_FH_ansteuern : 192|8@1+ (1,0) [0|100] "Unit_PerCent"  TSGGen3_HBFS
 SG_ SSA_HFT_FH_ansteuern : 203|8@1+ (1,0) [0|100] "Unit_PerCent"  TSGGen3_HFS
 SG_ SSA_FT_el_Tuerantrieb_ansteuern : 220|4@1+ (1.0,0.0) [0.0|15] ""  Vector__XXX
 SG_ SSA_BFT_el_Tuerantrieb_Zielwert : 232|8@1+ (0.5,0) [0.0|100.0] "Unit_PerCent"  Vector__XXX
 SG_ SSA_FT_el_Tuerantrieb_Zielwert : 240|8@1+ (0.5,0) [0.0|100.0] "Unit_PerCent"  Vector__XXX
 SG_ SSA_HBFT_el_Tuerantrieb_Zielwert : 248|8@1+ (0.5,0) [0.0|100.0] "Unit_PerCent"  Vector__XXX
 SG_ SSA_HFT_el_Tuerantrieb_Zielwert : 256|8@1+ (0.5,0) [0.0|100.0] "Unit_PerCent"  Vector__XXX
 SG_ SOK_SSAM_01_Signatur : 352|32@1+ (1,0) [0|4294967295] ""  Vector__XXX

BO_ 1313 STH_01: 8 Gateway_Max
 SG_ STH_Funk_ein : 0|1@1+ (1.0,0.0) [0.0|1] ""  Vector__XXX
 SG_ STH_Funk_aus : 1|1@1+ (1.0,0.0) [0.0|1] ""  Vector__XXX
 SG_ STH_Zusatzheizung : 2|1@1+ (1.0,0.0) [0.0|1] ""  Vector__XXX
 SG_ STH_LED : 3|1@1+ (1.0,0.0) [0.0|1] ""  BCM
 SG_ STH_Pumpe_ein : 4|1@1+ (1,0) [0|1] ""  Vector__XXX
 SG_ STH_Geblaese : 5|1@1+ (1.0,0.0) [0.0|1] ""  Vector__XXX
 SG_ STH_EKP_Anst : 6|1@1+ (1.0,0.0) [0.0|1] ""  Vector__XXX
 SG_ STH_Start_folgt : 7|1@1+ (1.0,0.0) [0.0|1] ""  Vector__XXX
 SG_ STH_Ventiloeffnungszeit : 8|6@1+ (1,0) [0|63] "Unit_Minut"  Vector__XXX
 SG_ STH_Ventil_Status : 14|1@1+ (1.0,0.0) [0.0|1] ""  Vector__XXX
 SG_ STH_Fehler_ElWaPu : 15|1@1+ (1.0,0.0) [0.0|1] ""  Vector__XXX
 SG_ STH_Waermeeintrag : 16|6@1+ (1,0) [0|63] "Unit_None"  Vector__XXX
 SG_ STH_Pumpen_Anf_extern : 22|1@1+ (1.0,0.0) [0.0|1] ""  Vector__XXX
 SG_ STH_KL_HUP : 23|1@1+ (1.0,0.0) [0.0|1] ""  Vector__XXX
 SG_ STH_KVS : 24|13@1+ (1,0) [0|8191] "Unit_MilliLiter"  Vector__XXX
 SG_ STH_Fehlerstatus : 37|3@1+ (1.0,0.0) [0.0|7] ""  Vector__XXX
 SG_ STH_Heizleistung : 40|8@1+ (1,0) [0|255] ""  Vector__XXX
 SG_ STH_Wassertemp : 48|8@1+ (0.75,-40) [-40.00|142.25] "Unit_DegreCelsi"  Vector__XXX
 SG_ STH_Texte : 56|3@1+ (1.0,0.0) [0.0|7] ""  Vector__XXX
 SG_ STH_Motorvorwaermung : 59|1@1+ (1.0,0.0) [0.0|1] ""  Vector__XXX
 SG_ STH_Servicemode : 60|1@1+ (1.0,0.0) [0.0|1] ""  Vector__XXX
 SG_ STH_war_aktiv : 61|1@1+ (1.0,0.0) [0.0|1] ""  Vector__XXX
 SG_ STH_KVS_Ueberlauf : 62|1@1+ (1.0,0.0) [0.0|1] ""  Vector__XXX
 SG_ STH_SH_ZH : 63|1@1+ (1.0,0.0) [0.0|1] ""  Vector__XXX

BO_ 832 STSG_HBFS_01: 8 Gateway_Max
 SG_ STSG_HBFS_Historie_Reject_adr : 11|2@1+ (1,0) [0|3] ""  Vector__XXX
 SG_ STSG_HBFS_Historie_Reject_data : 13|6@1+ (1,0) [0|63] ""  Vector__XXX
 SG_ STSG_HBFS_I_Motor : 19|8@1+ (0.5,0) [0.0|100.0] "Unit_Amper"  Vector__XXX
 SG_ STSG_HBFS_UB : 27|8@1+ (0.05,5) [5.00|17.65] "Unit_Volt"  Vector__XXX
 SG_ STSG_HBFS_Status_Feststeller : 35|1@1+ (1.0,0.0) [0.0|1] ""  Vector__XXX
 SG_ STSG_HBFS_Tuer_Position : 36|7@1+ (1,0) [0|127] "Unit_PerCent"  BCM
 SG_ STSG_HBFS_TIG_bet_schliessen : 43|1@1+ (1.0,0.0) [0.0|1] ""  BCM
 SG_ STSG_HBFS_TIG_bet_oeffnen : 44|1@1+ (1.0,0.0) [0.0|1] ""  BCM
 SG_ STSG_HBFS_FFB_Taste_Schiebtuer : 45|1@1+ (1.0,0.0) [0.0|1] ""  BCM
 SG_ STSG_HBFS_TAG_betaetigt : 46|1@1+ (1.0,0.0) [0.0|1] ""  BCM
 SG_ STSG_HBFS_Tuer_Sperrklinke : 47|1@1+ (1.0,0.0) [0.0|1] ""  Vector__XXX
 SG_ STSG_HBFS_entriegeln_anfordern : 48|1@1+ (1.0,0.0) [0.0|1] ""  BCM
 SG_ STSG_HBFS_Tuer_Vorraste : 49|1@1+ (1.0,0.0) [0.0|1] ""  BCM,TSGGen3_HBFS
 SG_ STSG_HBFS_Thermo_aktiv : 50|1@1+ (1.0,0.0) [0.0|1] ""  TSGGen3_HBFS
 SG_ STSG_HBFS_Bew_zu : 51|1@1+ (1.0,0.0) [0.0|1] ""  BCM,TSGGen3_HBFS
 SG_ STSG_HBFS_Bew_auf : 52|1@1+ (1.0,0.0) [0.0|1] ""  BCM,TSGGen3_HBFS
 SG_ STSG_HBFS_EOE_aktiv : 53|1@1+ (1.0,0.0) [0.0|1] ""  BCM,TSGGen3_HBFS
 SG_ STSG_HBFS_ZZH_Status_zu : 54|1@1+ (1.0,0.0) [0.0|1] ""  BCM,TSGGen3_HBFS
 SG_ STSG_HBFS_ZZH_Status_auf : 55|1@1+ (1.0,0.0) [0.0|1] ""  BCM,TSGGen3_HBFS
 SG_ STSG_HBFS_ZZH_Initialisierung : 56|1@1+ (1.0,0.0) [0.0|1] ""  TSGGen3_HBFS
 SG_ STSG_HBFS_ZZH_Freigabe : 57|1@1+ (1.0,0.0) [0.0|1] ""  TSGGen3_HBFS
 SG_ STSG_HBFS_UEKB_aktiv : 58|1@1+ (1.0,0.0) [0.0|1] ""  TSGGen3_HBFS
 SG_ STSG_HBFS_Einklemm_defekt : 59|1@1+ (1.0,0.0) [0.0|1] ""  TSGGen3_HBFS
 SG_ STSG_HBFS_Einklemm_aktiv : 60|1@1+ (1.0,0.0) [0.0|1] ""  TSGGen3_HBFS
 SG_ STSG_HBFS_TAT : 61|1@1+ (1.0,0.0) [0.0|1] ""  BCM
 SG_ STSG_HBFS_ST_deaktivieren : 62|1@1+ (1.0,0.0) [0.0|1] ""  BCM
 SG_ STSG_HBFS_BTF : 63|1@1+ (1.0,0.0) [0.0|1] ""  BCM

BO_TX_BU_ 980 :BCM,Gateway_Max;
CM_ BO_ 695 "Rear Cross Traffic Assist";
CM_ BO_ 1440 "8Byte ab MLBevo
LIN-CAN (1:1) Botschaften werden geroutet
-  wenn entsprechender Slave codiert ist
-  wenn fehlerfreie Kommunikation zum Slave besteht
-  bei fehlerhafter Kommunikation zum Slave wird die Botschaft für 4s mit den letzten gültigen Werte";
CM_ BO_ 1504 "MLBevo 8Byte
LIN-CAN (1:1) Botschaft wird geroutet:
- wenn entsprechender Slave codiert ist
- wenn fehlerfreie Kommunikation zum Slave besteht
- bei fehlerhafter Kommunikation zum Slave wird die Botschaft für 4s mit den letzten gültigen Werten versend";
CM_ BO_ 1522 "MQB";
CM_ BO_ 980 "Ab MQB 7.2";
CM_ BO_ 1710 "MLBevo 8Byte";
CM_ BO_ 2463978603 "Smart Sensor Actor Manager";

CM_ SG_ 1031 PLA_04_BZ "4bit Botschaftszähler, wird mit jeder Sendebotschaft inkrementiert";
CM_ SG_ 1031 PLA_04_CRC "Für MLB:
Berechnung siehe Lastenheft 'Kommunikationsabsicherung für FlexRay und CAN'
Ab MQB und MLBevo:
Berechnung siehe Lastenheft 'End-to-End Kommunikationsabsicherung'

Endwerte siehe Begleitdokument 'S-PDU Kennungsfolgen'";
CM_ SG_ 1031 PLAIPA_PaCo_Button "Signalisierung eines gedrückten PLA/IPA-Hardkeys.

0 Init_Or_Not_Equipped: Init oder kein PLA/IPA-Hardkey vorhanden
1 Button_Not_Pressed: PLA/IPA-Hardkey ist nicht gedrückt
2 Button_Pressed_Debounced: PLA/IPA-Hardkey ist gedrückt (entprellt)
3 Error:";
CM_ SG_ 1031 PLAIPA_PaCo_FunctionState "Signalisierung des Funktionszustandes von PLA/IPA

0 ResumePossible: Wiederaufnahme des aktiven Parkvorgangs ist seitens PLA/IPA möglich
1 Park_In_SearchMode: PLA/IPA befindet sich in der Lückensuchfahrt
2 Park_In_SlotFound: PLA/IPA hat mindestens ein";
CM_ SG_ 1031 PLAIPA_PaCo_GarageActivatable "Signalisierung, ob Garagenparken vom Fahrer aktiviert werden kann.";
CM_ SG_ 1031 PLAIPA_PaCo_InterventionPossible "Signalisierung, ob seitens PLA/IPA eine Übernahme der Fahrzeugführung für den (teil-)automatisierten Parkvorgang möglich ist

0 Not_Possible: Die Übernahme der Fahrzeugführung ist seitens PLA/IPA nicht möglich
1 Possible_Or_Active: Die Übernahme der Fa";
CM_ SG_ 1031 PLAIPA_PaCo_MainState "Hauptzustand der Kundenfunktion PLA/IPA.

0 Init: PLAIPA befindet sich in der Initialisierung
1 InOperation_NoError: PLAIPA befindet sich im Betrieb ohne Fehler
7 Fehler: PLAIPA befindet sich im Fehlerzustand";
CM_ SG_ 1031 PLAIPA_PaCo_ParkingSlots "Signalisierung der von PLA/IPA gefundenen Parklücken

0 Nothing: PLA/IPA hat keine Parklücken gefunden
1 One_ParkingSlot: PLA/IPA hat eine Parklücke gefunden
2 Two_ParkingSlots: PLA/IPA hat zwei Parklücken gefunden
3 Three_ParkingSlots: PLA/IPA hat d";
CM_ SG_ 1031 PLAIPA_PaCo_ParkingSlots_02 "Signalisierung der von PLA/IPA gefundenen Parklücken

0 Nothing: PLA/IPA hat keine Parklücken gefunden
1 One_ParkingSlot: PLA/IPA hat eine Parklücke gefunden
2 Two_ParkingSlots: PLA/IPA hat zwei Parklücken gefunden
3 Three_ParkingSlots: PLA/IPA hat d";
CM_ SG_ 1031 PLAIPA_PaCo_PLEPossible "Signalisierung, ob seitens PLA/IPA die Parklückeneinblendung (PLE) zur Verfügung steht

0 Not_Possible: die PLE-Funktionalität von PLA/IPA steht nicht zur Verfügung
1 Possible: die PLE-Funktionalität von PLA/IPA steht zur Verfügung";
CM_ SG_ 1031 PLAIPA_PaCo_RemoteActivatable "Signalisierung, ob RPAe vom Fahrer aktiviert werden kann.";
CM_ SG_ 1031 PLAIPA_PaCo_SwitchPossible "Signalisierung, ob seitens PLA/IPA ein Toggeln zur Auswahl der nächsten Parklücke möglich ist

0 Not_Possible: PLA/IPA kann keine weitere Parklücke als die aktuell ausgewählte dem Fahrer anbieten
1 Possible: PLA/IPA kann eine weitere Parklücke als die ";
CM_ SG_ 1031 PLAIPA_PaCo_UnavailableReason "Signalisierung der Ursache für die Nicht-Verfügbarkeit des PLA/IPA

0 No_Reason: PLA/IPA signalisiert keine Ursache für eine Nicht-Verfügbarkeit
1 EmergencyAssist_active: PLA/IPA steht aufgrund des aktiven Notfallassistenten nicht zur Verfügung.
2 Off";
CM_ SG_ 1031 RA_PaCo_FunctionState "Signalisierung des Funktionszustandes von RA

-----

Signalwerte:
0: Available (verfügbar): RA kann innerhalb der aktuellen Grenzen dem Fahrer die Funktion anbieten.
1: Trajectory_Recording (aufzeichnend): RA speichert eine Trajektorie zum späteren ";
CM_ SG_ 1031 RA_PaCo_InterventionPossible "Signalisierung, ob seitens RA eine Übernahme der Querführung für das Rückwärtsfahren möglich ist

-----

Signalwerte:
0 Not_Possible: Die Übernahme der Querführung ist seitens RA nicht möglich
1 Possible_Or_Active: Die Übernahme der Querführung ist ";
CM_ SG_ 1031 RA_PaCo_MainState "Hauptzustand der Kundenfunktion RA.

-----

Signalwerte:
0 Init: RA befindet sich in der Initialisierung
1 InOperation_NoError: RA befindet sich im Betrieb ohne Fehler
2 Fehler: RA befindet sich im Fehlerzustand";
CM_ SG_ 1031 RA_PaCo_UnavailableReason "Signalisierung für die Verfügbarkeit und die Ursache für die Nicht-Verfügbarkeit des Reversing Assist (RA)

-----

Signalwerte:
0 No_Reason: RA ist verfügbar. Es liegt kein Grund für eine Nicht-Verfügbarkeit vor
1 EmergencyAssist_active: RA steht au";
CM_ SG_ 1031 RPA_Anf_Sonder_Funktion_Status "Hiermit signalisiert die Funktion RemoteParkAssist ihren Zustand únd die Übernahme von bzw. Übergabe an KlemmenKoordinator";
CM_ SG_ 1031 RPA_Anf_Sonder_Klemme_15 "Hiermit fordert die Funktion RemoteParkAssist das Einschalten der Klemme 15 beim KlemmenKoordinator an";
CM_ SG_ 1031 RPA_Anf_WFS_Freigabe "Hiermit übermittelt die Funktion RPA welche Art der Fahrfreigabe beim Herstellen der Zündung notwendig ist";

CM_ SG_ 319 PreCrash_Anforderung_AFR "Anforderungen der Funktion PrecrashSeite an Fahrwerksregelung";
CM_ SG_ 319 PreCrash_BFS_KSV_verfahren "Ansteuerung der Kopfstuetze Beifahrerseite durch die Funktion PreCrash

Signalwert 0x09 für vereinfachte Ansteuerung mit Logik im Sitz-SG (MQB37W)";
CM_ SG_ 319 PreCrash_BFS_Laengsverstellung "Ansteuerung der Laengsverstellung des Beifahrersitzes durch die PreCrash-Funktionen";
CM_ SG_ 319 PreCrash_BFS_Pneumatik_ansteuern "Ansteuerung des Beifahrersitzes durch die PreCrash-Funktionen";
CM_ SG_ 319 PreCrash_BFS_Sitzlehne_verfahren "Ansteuerung des Beifahrersitzes durch die PreCrash-Funktionen

Wert 0x06 und 0x07 für vereinfachte Ansteuerung Sitzlehne";
CM_ SG_ 319 PreCrash_Blinken "Safety Computer übermittelt Blinkverhalten bei einer PreCrash-Auslösung an den BCM2";
CM_ SG_ 319 PreCrash_Charisma_FahrPr "Aktuell eingestelltes Fahrprogramm der Funktion PreCrash";
CM_ SG_ 319 PreCrash_Charisma_Status "Verfügbarkeit der Funktion PreCrash für die Ansteuerung durch den Charisma_Koordinator";
CM_ SG_ 319 PreCrash_Fenster_schliessen "Anforderung Seitenscheiben schließen durch die Funktion PreCrash";
CM_ SG_ 319 PreCrash_Fo_KSV_verfahren "Ansteuerung der Kopfstuetzen im Fond durch die PreCrash-Funktionen";
CM_ SG_ 319 PreCrash_Fo_Pneumatik_ansteuern "Ansteuerung der Fondsitze durch die PreCrash-Funktionen";
CM_ SG_ 319 PreCrash_Fo_Sitzlehne_verfahren "Ansteuerung des Fondsitzes durch die PreCrash-Funktionen";
CM_ SG_ 319 PreCrash_FS_KSV_verfahren "Ansteuerung der Kopfstuetze Fahrerseite durch die PreCrash-Funktionen

Signalwert 0x09 für vereinfachte Ansteuerung mit Logik im Sitz-SG (MQB37W)";
CM_ SG_ 319 PreCrash_FS_Laengsverstellung "Ansteuerung der Laengsverstellung des Fahrersitzes durch die PreCrash-Funktionen";
CM_ SG_ 319 PreCrash_FS_Pneumatik_ansteuern "Ansteuerung des Fahrersitzes durch die PreCrash-Funktionen";
CM_ SG_ 319 PreCrash_FS_Sitzlehne_verfahren "Ansteuerung des Fahrersitzes durch die PreCrash-Funktionen

Wert 0x06 und 0x07 für vereinfachte Ansteuerung Sitzlehne";
CM_ SG_ 319 PreCrash_Schiebedach_schliessen "Anforderung Schiebedach schließen durch die Funktion PreCrash";
CM_ SG_ 319 PreCrash_Tueren_Verriegeln "Anforderung Türen Verriegeln durch die Funktion PreCrash";
CM_ SG_ 319 SC_PreCrash_LED "Ansteuerung LED-Leiste im Kombi durch SC";
CM_ SG_ 319 SC_PreCrash_Texte "Safety Computer übermittelt Systemstatus der PreCrash Funktionen an Kombi";
CM_ SG_ 319 SC_PreCrash_Warnung "Safety Computer übermittelt Warnung der PreCrash Funktionen an Kombi";
CM_ SG_ 319 SC_PreSense_FCWP "Mitteilung an das NightVision, auf welche Art von Objekt eine Warnung angefordert wird";

CM_ SG_ 1616 RA_AM_Tuning "Das Signal kennzeichnet einen aktiven AM Suchlauf. Während des Suchlaufes wird die Frequenz = 0 übertragen.
0 = frequency locked => Störquelle vermeidet die aktuelle Frequenz
1 = AM tuning in progress => Störquelle abschalten bzw.PWM Signal auf DC umsch";
CM_ SG_ 1616 RA_Frequency "Übermittlung der eingestellten Sendefrequenz AM oder FM, diese wird mit RA_Frequency_unit multipliziert.
Im DAB oder Hybrid/Online Mode wird die aktuelle FM-Alternativfrequenz oder, falls nicht vorhanden, die zuletzt gehörte Senderfrequenz übertragen (AM";
CM_ SG_ 1616 RA_Frequency_unit "Faktor für RA_Frequency
bei AM: Faktor 0 = 1kHz
sonst   Faktor 1 = 100kHz";
CM_ SG_ 1616 RA_PowerAmpOn "1 = Request for Amplifier; 0 = Amplifier mute/off";
CM_ SG_ 1616 RA_Radio_Error_Flag "1 = mindestens ein Kundendienstfehlerspeicher Eintrag vorhanden";
CM_ SG_ 1616 RA_Radio_mute "1=Radio is muted for telephone";
CM_ SG_ 1616 RA_Radio_on "1 = user perceived On";
CM_ SG_ 1616 RA_Radio_Surround "1 = Surround ON; 0 = Surround OFF
requests the Amp to switch Surroundmode";
CM_ SG_ 1616 RA_VNC_OFF "VNC = Vehicle Noice Cancellation;
1 = VNC OFF; 0 = VNC ON
requests the Amp to switch VNC off";

CM_ SG_ 695 RCTA_01_BZ "4bit-Botschaftszaehler, wird in jeder Sendebotschaft inkrementiert";
CM_ SG_ 695 RCTA_01_CRC "Für MLB:
'Berechnung siehe Lastenheft 'Kommunikationsabsicherung für FlexRay und CAN''

Ab MQB und MLBevo:
'Berechnung siehe Lastenheft 'End-to-End Kommunikationsabsicherung''

Endwerte siehe Begleitdokument 'S-PDU Kennungsfolgen'";
CM_ SG_ 695 RCTA_Anf_Warnruck "Mit diesem Signal wird beim ESC ein Warnruck angefordert. Über die Belegung wird die Stärke des Rucks ausgewählt.";
CM_ SG_ 695 RCTA_Anforderung_HMS "Nach einer Notbremsung durch RCTA muss das Fahrzeug halten. Deshalb ist eine HMS-Anforderung mit der Notbremsung erforderlich.";
CM_ SG_ 695 RCTA_Bremsruck_Anforderung "Hinweis: In Zukunft das Signal RCTA_Anf_Warnruck anstatt RCTA_Bremsruck_Anforderung verwenden!

RCTA_Bremsruck_Anforderung  ist die Anforderung an das Bremssystem einen kurzen Bremsruck auszuführen. Mit dem Signal 'RCTA_Bremsruck_Freigabe' zusammen wird";
CM_ SG_ 695 RCTA_Bremsruck_Freigabe "Hinweis: In Zukunft das Signal RCTA_Anf_Warnruck anstatt RCTA_Bremsruck_Freigabe verwenden!

RCTA_Bremsruck_Freigabe ist die eigentliche Auforderung (mit dem Signal 'RCTA_Bremsruck_Anforderung') an das Bremssystem einen kurzen Bremsruck auszuführen. Dad";
CM_ SG_ 695 RCTA_Info_links "Hinweis: In Zukunft das Signal RCTA_Kritikalitätslevel_links anstatt RCTA_Info_links verwenden!

Das alte RCTA_Info wird aufgeteilt in RCTA_Info_links und RCTA_Info_rechts. Damit sollen Richtungsblinken oder ähnliches aufgrund der RCTA-Funtkion möglich ";
CM_ SG_ 695 RCTA_Info_rechts "Hinweis: In Zukunft das Signal RCTA_Kritikalitätslevel_rechts anstatt RCTA_Info_rechts verwenden!

Das alte RCTA_Info wird aufgeteilt in RCTA_Info_links und RCTA_Info_rechts. Damit sollen Richtungsblinken oder ähnliches aufgrund der RCTA-Funtkion möglic";
CM_ SG_ 695 RCTA_Kritikalitaetslevel_links "Mit dem Signal wird das Kritikalitätslevel der Funktion RCTA dargestellt.
Je höher das Kritikalitätslevel ist, je höher die Crashwahrscheinlichkeit.
Die Kritikalität ist nicht bewertbar, wenn
-	die Funktion im Anhängerbetrieb ist
-	die Sensorsicht blo";
CM_ SG_ 695 RCTA_Kritikalitaetslevel_rechts "Mit dem Signal wird das Kritikalitätslevel der Funktion RCTA dargestellt.
Je höher das Kritikalitätslevel ist, je höher die Crashwahrscheinlichkeit.
Die Kritikalität ist nicht bewertbar, wenn
-	die Funktion im Anhängerbetrieb ist
-	die Sensorsicht blo";
CM_ SG_ 695 RCTA_Modus "gibt die Verfügbarkeit der RCTA Modus an";
CM_ SG_ 695 RCTA_Notbremsung_Anforderung "RCTA_Notbremsung_Anforderung  ist die Anforderung der Funktion RCTA an das Bremssystem. Mit dem Signal 'Notbremsung_Freigabe' zusammen wird die Bremsung eingeleitet. Dadurch sollen größere Schäden am Fahrzeug verhindert werden.";
CM_ SG_ 695 RCTA_Notbremsung_Freigabe "RCTA_Notbremsung_Freigabe ist die eigentliche Auforderung (mit dem Signal 'Notbremsung_Anforderung_Wert') an das Bremssystem eine Notfallbremsung einzuleiten. Dadurch sollen größere Schäden am Fahrzeug vermieden werden.";
CM_ SG_ 695 RCTA_PaCo_BrakeIntervention "Signalisierung, ob die Kundenfunktion RCTA einen Bremseingriff ansteuert.

0 Inactive: RCTA steuert derzeit keinen Bremseingriff an
1 Active: RCTA steuert derzeit einen Bremseingriff an";
CM_ SG_ 695 RCTA_PaCo_BrakingPossible "Signalisierung, ob ein Bremseingriff seitens der Kundenfunktion RCTA möglich ist

0 Not_Possible: Aus Sicht von RCTA ist derzeit keine Unterstützung des Fahrers durch Bremseingriff möglich
1 Possible: Aus Sicht von RCTA ist derzeit eine Unterstützung d";
CM_ SG_ 695 RCTA_PaCo_MainState "Hauptzustand der Kundenfunktion RCTA

0 Init: RCTA befindet sich in der Initialisierung
1 InOperation_NoError: RCTA befindet sich im Betrieb ohne Fehler
7 Fehler: RCTA befindet sich im Fehlerzustand";
CM_ SG_ 695 RCTA_PaCo_UnavailableReason "Signalisierung der Ursachen für die Nicht-Verfügbarkeit von RCTA

0 No_Reason: Die RCTA-Funktion steht zur Verfügung oder es gibt keinen spezifischen Grund für die Nicht-Verfügbarkeit
1 Trailer_Hitched: Die RCTA-Funktion steht derzeit nicht zur Verfügu";
CM_ SG_ 695 RCTA_Status "RCTA_Status ist die Rückmeldung, ob das System überhaupt aktiv ist. Mögliche Zustände sind: Das System ist aus; Das System ist nur passiv (läuft, ist aber ohne Funktionalität); Das System ist aktiv; Das System ist fehlerhaft";
CM_ SG_ 695 RCTA_Status_FoD "RCTA Funktionsstatus für FoD";
CM_ SG_ 695 RCTA_Warnton "Ansteuerung APS Tongeber für  Warnton von RCTA. (Dauerton)";

CM_ SG_ 1711 RV_Dark_Screen "Verdunkelungsanforderung Kamerabild";
CM_ SG_ 1711 RV_Farbe "Istwert fuer Farbe (in Prozent)";
CM_ SG_ 1711 RV_Helligkeit "Istwert fuer Helligkeit (in Prozent)";
CM_ SG_ 1711 RV_HMI_Mode "Aktueller Wert für den HMI-Modus

";
CM_ SG_ 1711 RV_Kontrast "Istwert fuer Kontrast (in Prozent)";
CM_ SG_ 1711 RV_Menu_Item "Ausgewähltes Menü-Item
";
CM_ SG_ 1711 RV_Reinigung_Anf "Anforderung Reinigung der Rückfahrkamera";
CM_ SG_ 1711 RV_Settings_enabled "Menü 'Einstellungen'
";
CM_ SG_ 1711 RV_System_aktiv "Systemstatus (Initialisierungsphase)
";
CM_ SG_ 1711 RV_Video_on "Anzeige Kamerabild
";
CM_ SG_ 1711 SV_Video_on "Aufschaltaufforderung SideView";
CM_ SG_ 1711 ZFAS_Umfeldbeleuchtung_Anf "Anforderung für die Aktivierung einer Umfeldbeleuchtung zur Unterstützung des Umfeldkamerasystems bei Dunkelheit";

CM_ SG_ 2264486920 RHP_01_BZ "4bit Botschaftszähler, wird mit jeder Sendebotschaft inkrementiert
Botschaft asynchron geroutet. Zählerwert kann springen.";
CM_ SG_ 2264486920 RHP_01_CRC "Für MLB:
Berechnung siehe Lastenheft 'Kommunikationsabsicherung für FlexRay und CAN'
Ab MQB und MLBevo:
Berechnung siehe Lastenheft 'End-to-End Kommunikationsabsicherung'

Endwerte siehe Begleitdokument 'S-PDU Kennungsfolgen'";
CM_ SG_ 2264486920 RHP_Anf_ASIL "Definiert das Anforderungssignal von RHP an VZM mit dem dynamischen ASIL";
CM_ SG_ 2264486920 RHP_Anforderung_HMS "Bremsanforderung an den Haltemanager";
CM_ SG_ 2264486920 RHP_EA_AnfStat "This signal indicates the activation status information from RHP to EA";
CM_ SG_ 2264486920 RHP_EA_eCall "RHP triggers eCall via sending the requirements on EA";
CM_ SG_ 2264486920 RHP_EA_Innenraumlicht "RHP turning on interior lights via sending the requirements on EA";
CM_ SG_ 2264486920 RHP_EA_PreCrash "RHP triggers PreCrash via sending the requirements on EA";
CM_ SG_ 2264486920 RHP_EA_Tueren "RHP triggers door unlocking via sending the requirements on EA";
CM_ SG_ 2264486920 RHP_eCall_Anf "RHP triggers eCall";
CM_ SG_ 2264486920 RHP_Fahrzeughupe_Anf "Rush Hour Pilot Anforderung Fahrzeughupe";
CM_ SG_ 2264486920 RHP_Freilaufstrategie_TSK "Das Signal definiert im aktiven RHP - Betrieb, ob ein Freilauf direkt über das RHP angefordert wird oder ein Freilauf über den Triebstrangkoordinator (TSK) angefordert wird, falls das RHP den Freilauf freigibt.";
CM_ SG_ 2264486920 RHP_HOS "Rush Hour Pilot hands-off status";
CM_ SG_ 2264486920 RHP_Innenraumlicht_Anf "RHP turns on interior lights.";
CM_ SG_ 2264486920 RHP_Minimale_Bremsung "Im Falle eines gesetzten Bits wird vom RHP dem TSK angezeigt, dass es sich im Resume_Suspend_Mode befindet. In diesem Mode darf der TSK keine ECD-Bremsung anfordern, unabhängig von der 'RHP_Sollbeschleunigungsanforderung'. Eine Fahrzeugverzögerung darf nu";
CM_ SG_ 2264486920 RHP_nachtr_Stopp_Anf "Dieses Signal dient dem Motor als Trigger, dass ein nachträglicher Motorstopp eingeleitet werden kann, wenn es die Bedingungen des StSt Koordinators dies zulassen.";
CM_ SG_ 2264486920 RHP_neg_Sollbeschl_Grad "Empfehlung an den Triebstrangkoordinator , mit welchem betragsmäßig maximalen negativen Gradienten eine RHP-Anforderung 'RHP_Sollbeschleunigung' einzuregeln ist.";
CM_ SG_ 2264486920 RHP_OPSEnable "The OPS function receives the following signal to enable the function";
CM_ SG_ 2264486920 RHP_Parking_St "The signal shows the parking function status, if the parking function is Slot Detect or Guidance, the parking space should output.";
CM_ SG_ 2264486920 RHP_pos_Sollbeschl_Grad "Empfehlung an den Triebstrangkoordinator , mit welchem betragsmäßig maximalen positiven Gradienten eine RHP-Anforderung 'RHP_Sollbeschleunigung' einzuregeln ist.";
CM_ SG_ 2264486920 RHP_PreCrash_Anf "RHP triggers PreCrash";
CM_ SG_ 2264486920 RHP_QFK_AnfStat "Statusinformationen des Anforderers";
CM_ SG_ 2264486920 RHP_QFK_Art1 "Auswahlsignal für RHP_QFK_Signal1";
CM_ SG_ 2264486920 RHP_QFK_Art2 "Auswahlsignal für RHP_QFK_Signal2";
CM_ SG_ 2264486920 RHP_QFK_KrSoll "Krümmungsanforderung";
CM_ SG_ 2264486920 RHP_QFK_KrSoll_VZ "Vorzeichen für die Krümmungsanforderung";
CM_ SG_ 2264486920 RHP_QFK_KruemmSoll "Krümmungsanforderung";
CM_ SG_ 2264486920 RHP_QFK_KruemmSoll_VZ "Vorzeichen für die Krümmungsanforderung";
CM_ SG_ 2264486920 RHP_QFK_Signal1 "Inhalt RHP_QFK_Signal1 wird durch das Signal RHP_QFK_Art1 gesteuert.
Nähere Informationen im LAH Querführungskoordinator.";
CM_ SG_ 2264486920 RHP_QFK_Signal2 "Inhalt RHP_QFK_Signal2 wird durch das Signal RHP_QFK_Art2 gesteuert.
Nähere Informationen im LAH Querführungskoordinator.";
CM_ SG_ 2264486920 RHP_QFK_Spuerb "Spürbarkeitsanforderung. Legt fest, mit welchem Handmoment die angeforderte Krümmung überlenkt werden muss.";
CM_ SG_ 2264486920 RHP_RBF_Available "This signal is used for info RBF for RHP can support RBF forward or not";
CM_ SG_ 2264486920 RHP_Ruckfreigabe "Anforderung Bremsruck für Funktion Rush Hour Pilot";
CM_ SG_ 2264486920 RHP_SCAM_HeatingRequest "Gibt an, ob eine Beeinträchtigung der Kamerasicht durch Eis oder Beschlag vorliegt und diese durch Anschalten der Scheibenheizung behoben werden kann.";
CM_ SG_ 2264486920 RHP_Sollbeschleunigung "Anforderung an den Triebstrangkoordinator , eine 'RHP_Sollbeschleunigung' umzusetzen.";
CM_ SG_ 2264486920 RHP_Spurwechsel_Ready "Angabe der assistierten Spurwechselmöglichkeiten durch die Funktion 'Rush Hour Pilot'";
CM_ SG_ 2264486920 RHP_StartStopp_Info "Freigabe bzw. Startanforderung für Start/Stopp";
CM_ SG_ 2264486920 RHP_Status_Function "RHP status signal";
CM_ SG_ 2264486920 RHP_Status_Lat "RHP status signal for the lateral control";
CM_ SG_ 2264486920 RHP_Status_Long "RHP status signal for the longitudinal control";
CM_ SG_ 2264486920 RHP_TSK_Status "RHP status signal to TSK";
CM_ SG_ 2264486920 RHP_TV_Trigger "This signal is used for switching on/off TVeMid stream data output for RHP parking function.";
CM_ SG_ 2264486920 RHP_Uss_Anforderung "Control signal from RHP to front side PLA (VLS, VRS) and APS (VL, VR) sensors";
CM_ SG_ 2264486920 RHP_Verz_Anf "Verzögerungsanforderung der Funktionen Zielbremsung und Teilbremsung an das VZM";
CM_ SG_ 2264486920 RHP_Verz_Freigabe "Freigabe-Bit der RHP Verzögerung an das VZM";
CM_ SG_ 2264486920 RHP_Warnblinken "Ansteuerung des Warnblinkers für die Funktion Rush Hour Pilot";
CM_ SG_ 2264486920 RHP_Warnruckeln_Anf "Anforderung an VZM, welches Warnruckeln umgesetzt werden soll.";
CM_ SG_ 2264486920 RHP_zul_Regelabw_oben "Anforderung an den Triebstrangkoordinator. Zulässiger Betrag der Abweichung zwischen angeforderter 'RHP_Sollbeschleunigung' und umzusetzender Sollbeschleunigung  im TSK. Im TSK wird, abhängig vom Arbeitspunkt die Toleranz und die Sollbeschleunigung für da";
CM_ SG_ 2264486920 RHP_zul_Regelabw_unten "Anforderung an den Triebstrangkoordinator. Zulässiger Betrag der Abweichung zwischen angeforderter 'RHP_Sollbeschleunigung' und umzusetzender Sollbeschleunigung  im TSK. Im TSK wird, abhängig vom Arbeitspunkt die Toleranz und die Sollbeschleunigung für da";

CM_ SG_ 1440 LS_defekt "Fehlererkennung Lichtsensor
";
CM_ SG_ 1440 LS_Helligkeit_FW "Vorfeldhelligkeit";
CM_ SG_ 1440 LS_Helligkeit_IR "Globalfeldhelligkeit";
CM_ SG_ 1440 LS_Verbau "Verbauinfo Lichtsensor";
CM_ SG_ 1440 RLS_Vorfeldhelligkeit_Boost "erweiterte Helligkeitssensierung für HUD";
CM_ SG_ 1440 RS_defekt "Fehlererkennung Regensensor";
CM_ SG_ 1440 RS_Regenmenge "Regenmenge";
CM_ SG_ 1440 RS_Schwall "Schwallereignis";
CM_ SG_ 1440 RS_Verbau "Verbauinfo Regensensor";
CM_ SG_ 1440 RS_Verglasung_schliessen "Anforderung: Verglasung schliessen
";
CM_ SG_ 1440 RS_Wischergeschwindigkeit "Wischergeschwindigkeit (Hübe/min)";
CM_ SG_ 1440 SLS_Helligkeit_IR "Helligkeitswert des 'Smart-Light-Sensor' im Dashboard analog / alternativ zu LS_Helligkeit_IR.

Es ist entweder ein RLS_LIN oder ein Smart-LS im FZG verbaut.";

CM_ SG_ 1504 MD1_Lage "Lage Schiebedachstellung 1 (Signal wird 1:1 vom BCM2 geroutet; ursprünglicher Sender: SAD = LIN-Slave vom BCM2)";
CM_ SG_ 1504 MD1_Position "Aktuelle Öffnungsweite Schiebedach.";
CM_ SG_ 1504 MD3_Lage "Lage Schiebedachstellung 3 
(Signal wird 1:1 vom BCM2 geroutet; ursprünglicher Sender: SAD = LIN-Slave vom BCM2) 
";
CM_ SG_ 1504 MD3_Position "Schiebedachstellung 3 
(Signal wird 1:1 vom BCM2 geroutet; ursprünglicher Sender: SAD = LIN-Slave vom BCM2)
";
CM_ SG_ 1504 MRollo_Lage "Lage Rollo
(Signal wird 1:1 vom BCM2 geroutet; ursprünglicher Sender: Rollo = LIN-Slave vom BCM2)";
CM_ SG_ 1504 MRollo_Position "Aktuelle Öffnungsweite des Dachrollos.";
CM_ SG_ 1504 Rollo_normiert "Anzeigen Normierung des Dachrollos";
CM_ SG_ 1504 Rollo_Thermoschutz "Anzeigen aktivierter Thermoschutz des Dachrollo";
CM_ SG_ 1504 Rollo_UEKB_aktiv "Anzeigen aktivierter Überschusskraftbegrenzung des Dachrollos";
CM_ SG_ 1504 SAD_Anf_ESC_Zuschaltung "Zwangsaktivierung ESP durch SAD-SG (bei geöffnetem Schiebedach und V> xx km/h).";
CM_ SG_ 1504 SAD_normiert "Anzeige Normierung des Schiebeausstelldaches";
CM_ SG_ 1504 SAD_Taster_Deckel_hi "Taster für SAD Deckel hinten";
CM_ SG_ 1504 SAD_Taster_Deckel_vo "Taster für SAD Deckel vorne";
CM_ SG_ 1504 SAD_Taster_Rollo_hi "Taster für SAD Rollo hinten";
CM_ SG_ 1504 SAD_Taster_Rollo_vo "Taster für SAD Rollo vorne";
CM_ SG_ 1504 SAD_Thermoschutz "Anzeige aktivierter Thermoschutz des Schiebeausstelldaches";
CM_ SG_ 1504 SAD_UEKB_aktiv "Anzeige aktivierter Überschusskraftbegrenzung des Schiebeausstelldaches";

CM_ SG_ 2463978698 SAL_Ambex_CH_state "Weiterleitung vom Coming Home State aus dem BAP_Aussenlicht";
CM_ SG_ 2463978698 SAL_Ambex_CH_time "Weiterleitung vom Coming Home Time aus dem BAP_Aussenlicht";
CM_ SG_ 2463978698 SAL_Ambex_LH_state "Weiterleitung vom Leaving Home State aus dem BAP_Aussenlicht";
CM_ SG_ 2463978698 SAL_Ambex_LH_time "Weiterleitung vom Leaving Home Time aus dem BAP_Aussenlicht";
CM_ SG_ 2463978698 SAL_Ambex_Lichtsensor_ch_lh_ein "Signal gibt an, welchen Zustand das Standardaußenlicht erkennt, bezüglich Tag/Nacht (Umgebungshelligkeit)";
CM_ SG_ 2463978698 SAL_EA_Blinken_Status "Rückkanal des durch EA angeforderten Warnblinken";
CM_ SG_ 2463978698 SAL_EA_Warnblinken "SAL Rückmeldung EA Blinker-Status an Funktion EA";
CM_ SG_ 2463978698 SAL_Strg_Beleuchtung_WBT "Anforderungssignal zur Ansteuerung der Warnblinktaster-Beleuchtung. Das Signal gibt den Dimmwert an, mit dem die WBT-Beleuchtung angesteuert werden soll.";

CM_ SG_ 2463978815 SBM_01_BZ "4bit Botschaftszähler, wird mit jeder Sendebotschaft inkrementiert";
CM_ SG_ 2463978815 SBM_01_CRC "Für MLB:
Berechnung siehe Lastenheft 'Kommunikationsabsicherung für FlexRay und CAN'
Ab MQB und MLBevo:
Berechnung siehe Lastenheft 'End-to-End Kommunikationsabsicherung'

Endwerte siehe Begleitdokument 'S-PDU Kennungsfolgen'";
CM_ SG_ 2463978815 SBM_FahrerAkt_Lenkradpaddle "Eine Fahreraktion an den Lenkrad-Paddles wurde erkannt (unabhängig davon, ob die Fahrstufe dadurch gewechselt wurde).";
CM_ SG_ 2463978815 SBM_FahrerAkt_P_Taste "Eine Fahreraktion an der P-Taste wurde erkannt (unabhängig davon, ob die Fahrstufe dadurch gewechselt wurde).";
CM_ SG_ 2463978815 SBM_FahrerAkt_Schaltbetaetigung "Eine Fahreraktion an der Schaltbetätigung wurde erkannt (unabhängig davon, ob die Fahrstufe dadurch gewechselt wurde).";
CM_ SG_ 2463978815 SBM_Veto_Fahrstufe_extern "Veto des Schaltbetätigungsmasters hinsichtlich der Umsetzung externer Fahrstufenanforderungen.";

CM_ SG_ 1522 KBI_Dimmpoti "Signal wird benötigt für Dimmung im Audi B8. Der Signalfluss erfolgt vom Kombi an das BCM1.";
CM_ SG_ 1522 KBI_Phototransistor "Signal wird benötigt für die Dimmung von Such- Funktions- und Displaybeleuchtungen. Der Signalfluss erfolgt vom Steuergerät mit Fotosensor an die jeweiligen Dimmmaster-Steuergeräte.

Für Audi B8/Q5 und D4/C7/VW526 vor PA: 
0xFE Phototransistor nicht ve";

CM_ SG_ 1167 SK1_Key_Data_1 "1. Multiplexbotschaft der Service-Key Funktion";
CM_ SG_ 1167 SK1_Key_Data_10 "10. Multiplexbotschaft der Service-Key Funktion";
CM_ SG_ 1167 SK1_Key_Data_2 "2. Multiplexbotschaft der Service-Key Funktion";
CM_ SG_ 1167 SK1_Key_Data_3 "3. Multiplexbotschaft der Service-Key Funktion";
CM_ SG_ 1167 SK1_Key_Data_4 "4. Multiplexbotschaft der Service-Key Funktion";
CM_ SG_ 1167 SK1_Key_Data_5 "5. Multiplexbotschaft der Service-Key Funktion";
CM_ SG_ 1167 SK1_Key_Data_6 "6. Multiplexbotschaft der Service-Key Funktion";
CM_ SG_ 1167 SK1_Key_Data_7 "7. Multiplexbotschaft der Service-Key Funktion";
CM_ SG_ 1167 SK1_Key_Data_8 "8. Multiplexbotschaft der Service-Key Funktion";
CM_ SG_ 1167 SK1_Key_Data_9 "9. Multiplexbotschaft der Service-Key Funktion";
CM_ SG_ 1167 SK1_MUX "Multiplexer-Signal der Service-Key Botschaft";

CM_ SG_ 201 SM_AFR_Standfkt_Anf "Teilt der Funktion AFR mit, welche Funktion ausgeführt werden soll";
CM_ SG_ 201 SM_AFR_Verbindungsstatus "Teilt der Funktion AFR mit, ob eine Verbindung zum Smartphone besteht oder diese abgebrochen ist.";
CM_ SG_ 201 SM_Anlernstatus "Dient Funktionen bereits beim Aufschalten einer Funktion zu prüfen, ob mindestens ein Gerät in der Liste der gespeicherten Geräte hinterlegt ist.";
CM_ SG_ 201 SM_App_Sperrzustand "Signal zeigt an, ob sich der Kunde bereits innerhalb der App authentifiziert hat oder nicht.";
CM_ SG_ 201 SM_ARA_Gangwahl "Auswahl des Ganges";
CM_ SG_ 201 SM_ARA_Gaspedal "Gibt die Stellung des virtuellen Gaspedals wieder";
CM_ SG_ 201 SM_ARA_Knickwinkel_Soll "Angeforderter Knickwinkel";
CM_ SG_ 201 SM_ARA_Nothalt "Fordert einen Nothalt an";
CM_ SG_ 201 SM_ARA_Start "ARA-Funktion per Smartphone aufrufen";
CM_ SG_ 201 SM_ARA_Status_Steuersignal "Gibt den Status des Steuersignals wieder";
CM_ SG_ 201 SM_ARA_Trajektorienmodus "Trajektorienmodus für ARA auf Samrtphone (de-/aktivieren)";
CM_ SG_ 201 SM_Fehlerstatus "Kennzeichnet die Erkennung eines beliebigen Fehlers auf der Kommunikationsstrecke zwischen mobilen Endgerät und Fahrzeug.";
CM_ SG_ 201 SM_Parken_01_Sendestatus "Umschalten zwischen langsamen und schnellem Zyklus der SM_Parken_01-Botschaft";
CM_ SG_ 201 SM_Parken_Alive "Botchaftszähler zur Absicherung der Fahrtasterinteraktionen auf dem Smartphone.";
CM_ SG_ 201 SM_Parken_AngefordertesRemoteSys "Kommunikation vom Smartphone an die EPH. Gibt an welche Remote Funktion Aktiv ist.";
CM_ SG_ 201 SM_Parken_Kommando "Teilt der Parkfunktion mit, welche Eingaben der Nutzer auf dem Smartphone tätigt um die Funktion zu bedienen. Hauptsächlich Fahrtasterinteraktionen";
CM_ SG_ 201 SM_Parken_Kommando_invers "Invertiert das Signal SM_Parken_Kommando zur Absicherung der Übertragung aller Fahrtasterinteraktionen.";
CM_ SG_ 201 SM_Parken_Manoever "Beschreibt ob ein- oder ausgeparkt werden soll";
CM_ SG_ 201 SM_Parken_Motorstart_Anf "Dieses Signal teilt der Parkfunktion die Motorstartanforderung durch den Kunden mit.";
CM_ SG_ 201 SM_Parken_Richtung "Beschreibt ob die Parklücke vorwärts oder rückwärts beparkt werden soll";
CM_ SG_ 201 SM_Parken_Seite "Beschreibt ob eine Lücke links oder rechts vom Fahrzeug beparkt werden soll. Beim Ausparken kann zusätzlich zu einer Seite, geradeaus ausgeparkt werden. ";
CM_ SG_ 201 SM_Parken_Szenario "Beschreibt den Grundszenarientyp (Parallel = Längsparken; Perpendicular = Querparken; Garage = Garagenparken; Basic = Basisfunktion vorwärts oder rückwärts ohne Lenkeingriff)";
CM_ SG_ 201 SM_Parken_Touch_PosX "Position der Touchscreeneingabe in X-Richtung";
CM_ SG_ 201 SM_Parken_Touch_PosY "Position der Touchscreeneingabe in Y-Richtung";
CM_ SG_ 201 SM_Parken_Verbindungsstatus "Teilt der Parkfunktion mit, ob eine Verbindung zum Smartphone besteht. Die ID dient der Erkennung eines Gerätewechsels innerhalb eines Parkzyklus.";

CM_ SG_ 2527679651 SM_Parken_blinken "Blinkerstatus ARA auf Smartphone";
CM_ SG_ 2527679651 SM_Parken_Hupe_Anf "Ansteuerung der Hupe beim PiloPa";
CM_ SG_ 2527679651 SM_Parken_Komfortschliessen_Anf "Anforderung für Komfortschließen der Fenster und des SAD (Schiebeaufstelldach) beim PiloPa";
CM_ SG_ 2527679651 SM_Parken_UGDO_Aktion "Ansteuerung des UGDO (Universal Garage Door Opener) beim PiloPa für:
- Garagentor öffnen oder toggeln (garagentorabhängig),
- Garagentor schließen,
- Garagentor stoppen (z. B. bei Gefahr),
- Status des Garagentors abfragen (Antwort ist UGDO_DoorState)";
CM_ SG_ 2527679651 SM_Parken_UGDO_Anf "Ansteuerung von bis zu 15 verschiedenen UGDOs (Universal Garage Door Opener) beim PiloPa";

CM_ SG_ 980 BH_Blinker_Fehler "Anzeige, ob am Lenkstockschalter ein Fehler anliegt.
Notwendig aufgrund ASIL-Einstufung";
CM_ SG_ 980 BH_Blinker_li "Blinkerhebel Richtung links";
CM_ SG_ 980 BH_Blinker_re "Blinkerhebel Richtung rechts";
CM_ SG_ 980 BH_Fernlicht "Betaetigung Fernlicht
";
CM_ SG_ 980 BH_Lichthupe "Betaetigung Lichthupe
";
CM_ SG_ 980 FAS_Taster "Betaetigung FAS Taster
";
CM_ SG_ 980 FAS_Taster_Fehler "Fehlerstatus FAS Taster
";
CM_ SG_ 980 LRH_aktiv "Signal gibt an, ob ein Heizstrom durch die Lenkradheizung fließt. Es dient der Auswertung durch das Energiemanagement.";
CM_ SG_ 980 LRH_On_Off "Status Lenkradheizung";
CM_ SG_ 980 LSS_Tastencode "0x00 = No key pressed / key released
0x01 = Menu
0x02 = Menu Up / Next Screen
0x03 = Menu Down / Previous Screen
0x04 = Up
0x05 = Down
0x06 = Up / Down ThumbWheel
0x07 = OK (ThumbWheel-Button)
0x08 = Cancel / Escape
0x09..0x0F = reserved for furt";
CM_ SG_ 980 SMLS_01_BZ "4bit Botschaftszaehler, wird mit jeder Sendebotschaft inkrementiert";
CM_ SG_ 980 SMLS_01_CRC "Für MLB:
'Berechnung siehe Lastenheft 'Kommunikationsabsicherung für FlexRay und CAN''

Ab MQB und MLBevo:
'Berechnung siehe Lastenheft 'End-to-End Kommunikationsabsicherung''

Endwerte siehe Begleitdokument 'S-PDU Kennungsfolgen'";
CM_ SG_ 980 SMLS_Hupe "Betaetigung Hupe
";
CM_ SG_ 980 SMLS_P_verriegelt "Signal stellt den Status des Signals P-verriegelt auf den Fahrzeugbus zur Verfügung. Nutzer sind z.B. die ELV, die das Signal für die Verriegelung benötigt und die Funktion Verlassenswarnung, die den Fahrer beim Verrollen des Fahrzeugs warnt.";
CM_ SG_ 980 SMLS_P_verriegelt_plausibel "Signal stellt den Plausibilisierungstatus des Signals p_verriegelt auf den Fahrzeugbus zur Verfügung. Eine Plausibilität muss explizit erkannt werden. Initial wird 'unplausibel' gesendet. Ein plausibles Signal wird erkannt, wenn p_verriegelt plausibel geg";
CM_ SG_ 980 SMLS_PTT "Betaetigung PTT";
CM_ SG_ 980 WH_Frontwaschen "Wischerhebel: Stellung Wisch Wasch vorne
";
CM_ SG_ 980 WH_Heckintervall "Wischerhebel: Stellung Heckintervall
";
CM_ SG_ 980 WH_Heckwaschen "Wischerhebel: Stellung Wisch Wasch hinten
";
CM_ SG_ 980 WH_Intervall "Wischerhebel: Stellung Intervall
";
CM_ SG_ 980 WH_Intervallstufen "Wischerhebel: Stellung Intervallstufen";
CM_ SG_ 980 WH_SRA "Scheinwerferreinigungsanlage

derzeit nur bei PAG umgesetzt";
CM_ SG_ 980 WH_Tipwischen "Wischerhebel: Tippwischen

MQB A0/ PQ26: Bei Verbau LSS (kein SMLS): gespiegelter Wert zu Signal WH_WischerStufe1";
CM_ SG_ 980 WH_Tipwischen_lang "Wischerhebel: Tippwischen lang
(dient zur Auswertung für die Unterscheidung Tippwischen oder Serviceposition Wischer)";
CM_ SG_ 980 WH_Wischer_Fehler "Anzeige, ob am Lenkstockschalter ein Fehler anliegt.
Notwendig aufgrund ASIL-Einstufung";
CM_ SG_ 980 WH_WischerStufe1 "Wischerhebel: Stufe Wischen 1
";
CM_ SG_ 980 WH_WischerStufe2 "Wischerhebel: Stufe Wischen 2
";

CM_ SG_ 2464161806 SOK_FoD_BCM1_Req_Challenge "Challenge im Rahmen des SOK Challenge-Response Protokolls.

Geschützte Funktion: Function on Demand";

CM_ SG_ 2464296974 SOK_FoD_BCM1_Resp_Challenge "Challenge im Rahmen des SOK Challenge-Response Protokolls.

Geschützte Funktion: Function on Demand";

CM_ SG_ 2589283756 SOK_ungeschuetzte_Zeit "Periodisch verschickter SOK Zeitwert des SOK Zeitmasters als Referenzzeit zur Erkennung von Clockjitter durch andere SOK Teilnehmer.

Der Empfang dieses Signals ist verpflichtend für jedes Steuergerät, das durch die authentische Broadcast Funktionalität";

CM_ SG_ 2464153614 SOK_Zeit_BCM_Challenge "Challenge im Rahmen des SOK Challenge-Response Protokolls.

Geschützte Funktion: Empfang der SOK-Zeit vom SOK-Zeitmaster; verbindlich für Steuergeräte, welche mit der durch SOK geschützten Broadcast Nachrichten empfangen oder versenden";

CM_ SG_ 2464284686 SOK_Zeit_BCM_Signatur "Signatur im Rahmen des SOK Challenge-Response Protokolls.

Geschützte Funktion: Empfang der SOK-Zeit vom SOK-Zeitmaster; verbindlich für Steuergeräte, welche mit der durch SOK geschützten Broadcast Nachrichten empfangen oder versenden";

CM_ SG_ 2464288782 SOK_Zeit_BCM_Zeit "Aktueller Wert der SOK-Zeit des SOK-Zeitmasters; geschützt durch das SOK Challenge-Response Protokoll";

CM_ SG_ 2464153786 SOK_Zeit_DDA_Challenge "Challenge im Rahmen des SOK Challenge-Response Protokolls.

Geschützte Funktion: Empfang der SOK-Zeit vom SOK-Zeitmaster; verbindlich für Steuergeräte, welche mit der durch SOK geschützten Broadcast Nachrichten empfangen oder versenden";

CM_ SG_ 2464284858 SOK_Zeit_DDA_Signatur "Signatur im Rahmen des SOK Challenge-Response Protokolls.

Geschützte Funktion: Empfang der SOK-Zeit vom SOK-Zeitmaster; verbindlich für Steuergeräte, welche mit der durch SOK geschützten Broadcast Nachrichten empfangen oder versenden";

CM_ SG_ 2464288954 SOK_Zeit_DDA_Zeit "Aktueller Wert der SOK-Zeit des SOK-Zeitmasters; geschützt durch das SOK Challenge-Response Protokoll";

CM_ SG_ 2464153675 SOK_Zeit_TSG_BT_Challenge "Challenge of SOK participant HTSG_BFS to SOK time server for requesting authentic SOK time";

CM_ SG_ 2464284747 SOK_Zeit_TSG_BT_Signatur "SOK_Time__Signature";
CM_ SG_ 2464284747 SOK_Zeit_TSG_BT_Zeit "Response signal of SOK time server to challenge of an SOK participant, containing SOK time";

CM_ SG_ 2464153674 SOK_Zeit_TSG_FT_Challenge "Challenge of SOK participant TSG_FS to SOK time server for requesting authentic SOK time";

CM_ SG_ 2464284746 SOK_Zeit_TSG_FT_Signatur "Signature to protect authentic SOK time";
CM_ SG_ 2464284746 SOK_Zeit_TSG_FT_Zeit "Response signal of SOK time server to challenge of an SOK participant, containing SOK time";

CM_ SG_ 2464153663 SOK_Zeit_TSG_HBFS_Challenge "Challenge of SOK participant TSG_HBFS to SOK time server for requesting authentic SOK time";

CM_ SG_ 2464284735 SOK_Zeit_TSG_HBFS_Signatur "Signature to protect authentic SOK time";
CM_ SG_ 2464284735 SOK_Zeit_TSG_HBFS_Zeit "Response signal of SOK time server to challenge of an SOK participant, containing SOK time";

CM_ SG_ 2464153662 SOK_Zeit_TSG_HFS_Challenge "Challenge of SOK participant TSG_HFS to SOK time server for requesting authentic SOK time";

CM_ SG_ 2464284734 SOK_Zeit_TSG_HFS_Signatur "Signature to protect authentic SOK time";
CM_ SG_ 2464284734 SOK_Zeit_TSG_HFS_Zeit "Response signal of SOK time server to challenge of an SOK participant, containing SOK time";

CM_ SG_ 1467 SoSe_SunInt_2D_Li "Sonnenintensität links (2D Sensor)";
CM_ SG_ 1467 SoSe_SunInt_2D_Re "Sonnenintensität rechts (2D Sensor)";

CM_ SG_ 1710 SP_abklappen "Spiegel abklappen";
CM_ SG_ 1710 SP_anklappen "Spiegel anklappen";
CM_ SG_ 1710 SP_ARA_Status "Rückkanal TSG im ARA-Modus";
CM_ SG_ 1710 SP_Auswahl_li "Spiegelschalter in Stellung Auswahl links";
CM_ SG_ 1710 SP_Auswahl_re "Spiegelschalter in Stellung Auswahl rechts";
CM_ SG_ 1710 SP_BT_links "Spiegel Beifahrertür nach links";
CM_ SG_ 1710 SP_BT_oben "Spiegel Beifahrertür nach oben";
CM_ SG_ 1710 SP_BT_rechts "Spiegel Beifahrertür nach rechts";
CM_ SG_ 1710 SP_BT_unten "Spiegel Beifahrertür nach unten";
CM_ SG_ 1710 SP_FT_links "Spiegel Fahrertür nach links";
CM_ SG_ 1710 SP_FT_oben "Spiegel Fahrertür nach oben";
CM_ SG_ 1710 SP_FT_rechts "Spiegel Fahrertür nach rechts";
CM_ SG_ 1710 SP_FT_unten "Spiegel Fahrertür nach unten";
CM_ SG_ 1710 SP_Hzg_Taster "Heizungstaster/schalter aktiv";
CM_ SG_ 1710 SP_normieren "Spiegel normieren";
CM_ SG_ 1710 SP_S_Klappen "Spiegelschalter in Stellung Klappen";
CM_ SG_ 1710 SP_S_links "Spiegelschalter in Stellung links";
CM_ SG_ 1710 SP_S_oben "Spiegelschalter in Stellung oben";
CM_ SG_ 1710 SP_S_rechts "Spiegelschalter in Stellung rechts";
CM_ SG_ 1710 SP_S_unten "Spiegelschalter in Stellung unten";
CM_ SG_ 1710 SP_Spg_Verstellschalter_Fehler "Erkennung eines hängenden Spiegelverstellschalters";
CM_ SG_ 1710 SP_Verstellschalter_Fehler "Erkennung eines hängenden Spiegelverstellschalters";

CM_ SG_ 2463978603 KFT_FH_BT_hoch "Freigabeinformation fuer die FH-Komfortfunktion";
CM_ SG_ 2463978603 KFT_FH_BT_tief "Freigabeinformation fuer die FH-Komfortfunktion";
CM_ SG_ 2463978603 KFT_FH_Freigabe "Funktionsfreigabe Fensterheber";
CM_ SG_ 2463978603 KFT_FH_FT_hoch "Freigabeinformation fuer die FH-Komfortfunktion";
CM_ SG_ 2463978603 KFT_FH_FT_tief "Freigabeinformation fuer die FH-Komfortfunktion";
CM_ SG_ 2463978603 KFT_FH_HBFS_hoch "Freigabeinformation fuer die FH-Komfortfunktion";
CM_ SG_ 2463978603 KFT_FH_HBFS_tief "Freigabeinformation fuer die FH-Komfortfunktion";
CM_ SG_ 2463978603 KFT_FH_HFS_hoch "Freigabeinformation fuer die FH-Komfortfunktion";
CM_ SG_ 2463978603 KFT_FH_HFS_tief "Freigabeinformation fuer die FH-Komfortfunktion";
CM_ SG_ 2463978603 KFT_Komfortfkt_Freigabe "globale Freigabe der Komfortfunktion";
CM_ SG_ 2463978603 KFT_Rollo_auf "Komfortöffnen des Dachrollos";
CM_ SG_ 2463978603 KFT_Rollo_zu "Komfortschließen des Dachrollos";
CM_ SG_ 2463978603 KFT_SAD_auf "Komfortöffnen des Schiebeausstelldaches";
CM_ SG_ 2463978603 KFT_SAD_zu "Komfortschließen des Schiebeausstelldaches";
CM_ SG_ 2463978603 KFT_Verdeck_auf "Anforderungssignal für ein Komfortöffnen des Verdecks. 
Signal wird angefordert wenn  SKontakt = 0 und eine Doppelbetätigung Schließzylinder_auf oder Funkfernbedienung_Taste_auf  innerhalb zwei Sekunden empfangen wird. Signal wird auch angefordert wenn S";
CM_ SG_ 2463978603 KFT_Verdeck_Freigabe "Freigabe Verdeckbetrieb";
CM_ SG_ 2463978603 KFT_Verdeck_zu "Anforderungssignal für ein Komfortschließen des Verdecks. 
Signal wird angefordert wenn  SKontakt = 0 und eine Doppelbetätigung Schließzylinder_Zu oder Funkfernbedienung_Taste_zu  innerhalb zwei Sekunden empfangen wird. Signal wird auch angefordert wenn ";
CM_ SG_ 2463978603 Privacy_SAD_Rollo1_ansteuern "Dachrollo1 ansteuern";
CM_ SG_ 2463978603 Privacy_SAD_Rollo2_ansteuern "Dachrollo2 ansteuern";
CM_ SG_ 2463978603 SOK_SSAM_01_Signatur "Signatur im Rahmen der durch SOK geschützen Broadcast-Kommunikation
";
CM_ SG_ 2463978603 SSA_BFT_ASP_Klappung_ansteuern "SmartSensorActor:
Anforderung um den Aussenspiegel an- bzw. Abzuklappen";
CM_ SG_ 2463978603 SSA_BFT_ASP_SpglGlas_ansteuern "SmartSensorActor:
Steuersignal zum Verfahren des Spiegelglases im Außenspiegel";
CM_ SG_ 2463978603 SSA_BFT_ASW_ansteuern "SmartSensorActor:
Rückmeldung der ASW Anzeige.";
CM_ SG_ 2463978603 SSA_BFT_el_Tuerantrieb_Zielwert "'Soll-Öffnungswert der Tuer in %
0% bedeutet Tuer geschlossen
100% vollständig geschlossen
Werte über 200 sind Vorhalt'";
CM_ SG_ 2463978603 SSA_BFT_FH_ansteuern "SmartSensorActor:
Anforderung zum Verfahren des elektrischen Fensterhebers

Nur manuelle Fensterheberbedienung möglich
- nur mit FH Freigabe
- deaktiver Thermoschutz";
CM_ SG_ 2463978603 SSA_BFT_FH_Pos_anfahren "SmartSensorActor:
Anforderung zum Verfahren des elektrischen Fensterhebers auf eine bestimmte Position

- nur mit FH Freigabe
- deaktiver Thermoschutz
- nur wenn Fensterheber normiert";
CM_ SG_ 2463978603 SSA_FT_ASP_SpglGlas_ansteuern "SmartSensorActor:
Steuersignal zum Verfahren des Spiegelglases im Außenspiegel";
CM_ SG_ 2463978603 SSA_FT_ASW_ansteuern "SmartSensorActor:
Rückmeldung der ASW Anzeige.";
CM_ SG_ 2463978603 SSA_FT_el_Tuerantrieb_ansteuern "SmartSensorActor:
Rückmeldung der Ansteuerung des el. Tuerantriebes";
CM_ SG_ 2463978603 SSA_FT_el_Tuerantrieb_Zielwert "'Soll-Öffnungswert der Tuer in %
0% bedeutet Tuer geschlossen
100% vollständig geschlossen
Werte über 200 sind Vorhalt'";
CM_ SG_ 2463978603 SSA_FT_FH_ansteuern "SmartSensorActor:
Anforderung zum Verfahren des elektrischen Fensterhebers

Nur manuelle Fensterheberbedienung möglich
- nur mit FH Freigabe
- deaktiver Thermoschutz";
CM_ SG_ 2463978603 SSA_FT_ZV_Ansteuern "SmartSensorActor:
Kommando zur Ansteuerung des Türschlosses der Fahrertür";
CM_ SG_ 2463978603 SSA_FT_ZZH_ansteuern "SmartSensorActor:
Anforderung zur Aktivierung eines Zuziehvorganges";
CM_ SG_ 2463978603 SSA_HBFT_el_Tuerantrieb_Zielwert "'Soll-Öffnungswert der Tuer in %
0% bedeutet Tuer geschlossen
100% vollständig geschlossen
Werte über 200 sind Vorhalt'";
CM_ SG_ 2463978603 SSA_HBFT_FH_ansteuern "SmartSensorActor:
Anforderung zum Verfahren des elektrischen Fensterhebers

Nur manuelle Fensterheberbedienung möglich
- nur mit FH Freigabe
- deaktiver Thermoschutz";
CM_ SG_ 2463978603 SSA_HBFT_SSR_ansteuern "SmartSensorActor:
Anforderung zum Verfahren des elektrischen Seitenscheibenrollos

Nur automatische Fensterheberbedienung möglich
- nur mit FH Freigabe
- deaktiver Thermoschutz
- Fenster komplett geschlossen";
CM_ SG_ 2463978603 SSA_HD_ansteuern "SmartSensorActor:
Anforderung zum Verfahren des Heckdeckels";
CM_ SG_ 2463978603 SSA_HD_Beeper_ansteuern "SmartSensorActor:
Anforderung zum Ansteuern des Beepers";
CM_ SG_ 2463978603 SSA_Heckrollo_ansteuern "SmartSensorActor:
Anforderung zum Verfahren des Heckrollos";
CM_ SG_ 2463978603 SSA_Heckrollo_PrivacySAD_Rollo1 "Dachrollo1 ansteuern";
CM_ SG_ 2463978603 SSA_Heckrollo_PrivacySAD_Rollo2 "Dachrollo2 ansteuern";
CM_ SG_ 2463978603 SSA_HFT_el_Tuerantrieb_Zielwert "'Soll-Öffnungswert der Tuer in %
0% bedeutet Tuer geschlossen
100% vollständig geschlossen
Werte über 200 sind Vorhalt'";
CM_ SG_ 2463978603 SSA_HFT_FH_ansteuern "SmartSensorActor:
Anforderung zum Verfahren des elektrischen Fensterhebers

Nur manuelle Fensterheberbedienung möglich
- nur mit FH Freigabe
- deaktiver Thermoschutz";
CM_ SG_ 2463978603 SSA_LRA_ansteuern "SmartSensorActor:
Anforderung zum Verfahren der Laderaumabdeckung";
CM_ SG_ 2463978603 SSA_SAD_Deckel1_ansteuern "Schiebedach ansteuern";
CM_ SG_ 2463978603 SSA_SAD_Rollo1_ansteuern "Dachrollo1 ansteuern";
CM_ SG_ 2463978603 SSA_SD_Versorgung_ansteuern "SmartSensorActor:
Anforderung zum Ansteuern der Steckdosenversorgung";

CM_ SG_ 1313 STH_EKP_Anst "STH sendet die Anforderung zur Ansteuerung der EKP an den Motor, um Kraftstoffbehälter der STH zu befüllen.";
CM_ SG_ 1313 STH_Fehler_ElWaPu "Fehler der el. Zusatzwasserpumpe der zur Deaktivierung der Wasserpumpe führt ";
CM_ SG_ 1313 STH_Fehlerstatus "Übermittlung der unterschiedlichen Fehlerzustände der Standheizung";
CM_ SG_ 1313 STH_Funk_aus "Funkbefehl über Funkfernbedienung zum Ausschalten Standheizung";
CM_ SG_ 1313 STH_Funk_ein "Funkbefehl über Funkfernbedienung zum Einschalten Standheizung";
CM_ SG_ 1313 STH_Geblaese "Ein-/ Ausschaltbefehl an die Klimaanlage, Gebläse";
CM_ SG_ 1313 STH_Heizleistung "Heizleistung in %";
CM_ SG_ 1313 STH_KL_HUP "Signal HUP Aktivierung an Klima

0 = HUP aus
1 = HUP ein";
CM_ SG_ 1313 STH_KVS "Kraftstoffverbrauch";
CM_ SG_ 1313 STH_KVS_Ueberlauf "Kraftstoffverbrauch, Überlauf hat stattgefunden";
CM_ SG_ 1313 STH_LED "Funktionslampe";
CM_ SG_ 1313 STH_Motorvorwaermung "Info an der Motor, dass der Aufheizvorgang mit Motorvorwärmung erfolgt ist";
CM_ SG_ 1313 STH_Pumpen_Anf_extern "Anforderung der motorseitigen elektr. (externen) Wasserpumpe zur Kreislaufunterstützung im Standheizbetrieb";
CM_ SG_ 1313 STH_Servicemode "Rückmeldung, dass die Standheizung sich gerade im Diagnosemodus befindet, gestartet über Diagnosetester";
CM_ SG_ 1313 STH_SH_ZH "0 = Heizgerät ist Standheizung
1 = Heizgerät ist Zuheizer
Gerätekennung WZH oder ZH
";
CM_ SG_ 1313 STH_Start_folgt "Thema Start/Stop: Im Stop-Modus muß das KBT einen Wiederstart anfordern, da ein STH-Start notwendig ist.";
CM_ SG_ 1313 STH_Texte "Anforderung der unterschiedlichen Anzeigetexte im Mitteldisplay des Kombi.

0: Keine Anzeige
1: Kein Standheizungs- bzw Lueftungsbetrieb wegen Batteriemanagementeinschraenkung
2: Kein Standheizungs- bzw Lueftungsbetrieb wegen Kraftstoffmangels
3: Kei";
CM_ SG_ 1313 STH_Ventil_Status "Statusrückmeldung Ansteuerung 3/2 Wege-Ventil";
CM_ SG_ 1313 STH_Ventiloeffnungszeit "Die Standheizung sendet an den Motor die Information darüber wie lange das Magnetventil die Wasserkreisläufe von 'klein' aus 'gross' geschaltet hat. ";
CM_ SG_ 1313 STH_Waermeeintrag "Signal enthält die Brenndauer in 1min-Schritten, über welche die Standheizung gelaufen ist";
CM_ SG_ 1313 STH_war_aktiv "Bit beeinhaltet die Info, dass die Standheizung während der letzten halbe Stunde aktiv war.";
CM_ SG_ 1313 STH_Wassertemp "Kühlmitteltemperatur der Standheizung";
CM_ SG_ 1313 STH_Zusatzheizung "Kraftstoffzuheizer aktiv";

CM_ SG_ 832 STSG_HBFS_Bew_auf "STSG Tür-Bewegung öffnen";
CM_ SG_ 832 STSG_HBFS_Bew_zu "STSG Tür-Bewegung schliessen";
CM_ SG_ 832 STSG_HBFS_BTF "STSG BTF Betätigung";
CM_ SG_ 832 STSG_HBFS_Einklemm_aktiv "STSG Einklemmschutzvorrichtung aktiv";
CM_ SG_ 832 STSG_HBFS_Einklemm_defekt "STSG Einklemmschutzvorrichtung defekt";
CM_ SG_ 832 STSG_HBFS_entriegeln_anfordern "Das STSG fordert an, die Schiebetür zu entriegeln.";
CM_ SG_ 832 STSG_HBFS_EOE_aktiv "STSG eÖ-Motor";
CM_ SG_ 832 STSG_HBFS_FFB_Taste_Schiebtuer "Taste für Schiebetür auf der Funkfernbedienung.";
CM_ SG_ 832 STSG_HBFS_Historie_Reject_adr "Bereitstellung der Adresse für Histoiendaten 1-3 und der RejectReason";
CM_ SG_ 832 STSG_HBFS_Historie_Reject_data "Bereitstellung der Daten für Histoiendaten 1-3 und der RejectReason";
CM_ SG_ 832 STSG_HBFS_I_Motor "Stromaufnahme Motor STSG_HBFS";
CM_ SG_ 832 STSG_HBFS_ST_deaktivieren "STSG deaktivieren";
CM_ SG_ 832 STSG_HBFS_Status_Feststeller "Status des Schiebetür Feststeller Beifahrerseite.
gelöst/Festgestellt";
CM_ SG_ 832 STSG_HBFS_TAG_betaetigt "Türaussenbetaetigung";
CM_ SG_ 832 STSG_HBFS_TAT "STSG TAT Betätigung";
CM_ SG_ 832 STSG_HBFS_Thermo_aktiv "STSG Thermoschutz";
CM_ SG_ 832 STSG_HBFS_TIG_bet_oeffnen "Türinnenbetätigung, Taster Tür öffnen.";
CM_ SG_ 832 STSG_HBFS_TIG_bet_schliessen "Türinnenbetätigung, Taster Tür schliessen.";
CM_ SG_ 832 STSG_HBFS_Tuer_Position "Position der Schiebetür.
0%:         Tuer geschlossen
100%:     Tuer geoeffnet bis Softendanschlag
>100%:   Tuer geoeffnet ueber Softendanschlag hinaus";
CM_ SG_ 832 STSG_HBFS_Tuer_Sperrklinke "STSG Sperrklinke";
CM_ SG_ 832 STSG_HBFS_Tuer_Vorraste "STSG Vorraste";
CM_ SG_ 832 STSG_HBFS_UB "Bordnetzspannung gemessen vom STSG_HBFS";
CM_ SG_ 832 STSG_HBFS_UEKB_aktiv "STSG Überschusskraftbegrenzung";
CM_ SG_ 832 STSG_HBFS_ZZH_Freigabe "STSG Zuziehhilfe Freigabe";
CM_ SG_ 832 STSG_HBFS_ZZH_Initialisierung "STSG Zuziehhilfe Initialisierung";
CM_ SG_ 832 STSG_HBFS_ZZH_Status_auf "STSG Status ausfahren";
CM_ SG_ 832 STSG_HBFS_ZZH_Status_zu "STSG Status zuziehen";
BA_DEF_REL_ BU_SG_REL_  "GenSigTimeoutTime" INT 0 65535;
BA_DEF_ BO_  "DiagRequest" ENUM "No", "Yes";
BA_DEF_ BO_  "DiagResponse" ENUM "No", "Yes";
BA_DEF_ BO_  "DiagState" ENUM "No", "Yes";
BA_DEF_ BO_  "GenMsgChkConstant" HEX 0 4095;
BA_DEF_ BO_  "GenMsgCycleTime" INT 0 65535;
BA_DEF_ BO_  "GenMsgCycleTimeFast" INT 0 65535;
BA_DEF_ BO_  "GenMsgDelayTime" INT 0 100000;
BA_DEF_ BO_  "GenMsgILSupport" ENUM "No", "Yes";
BA_DEF_ BO_  "GenMsgNrOfRepetition" INT 0 100;
BA_DEF_ BO_  "GenMsgPDUConstants" STRING;
BA_DEF_ BO_  "GenMsgSendType" ENUM "Cyclic", "not_used", "not_used", "not_used", "not_used", "not_used", "not_used", "IfActive", "NoMsgSendType";
BA_DEF_ BO_  "GenMsgStartDelayTime" INT 0 100000;
BA_DEF_ BO_  "NmMessage" ENUM "No", "Yes";
BA_DEF_ BO_  "NmhMessage" ENUM "No", "Yes";
BA_DEF_ BO_  "MsgType" ENUM "Application", "NM ", "NMH", "TP2.0", "ISO-TP ", "BAP", "EID", "KS", "XCP_PRE_CONFIGURED", "XCP_RUNTIME_CONFIGURED";
BA_DEF_ BO_  "VAGTP20_API" HEX 0 255;
BA_DEF_ BO_  "VAGTP20_DynConnection" ENUM "No", "Yes";
BA_DEF_ BO_  "VAGTP20_DynSetup" ENUM "No", "Yes";
BA_DEF_ BO_  "VAGTP20_StatConnection" ENUM "No", "Yes";
BA_DEF_ BO_  "CANFD_BRS" ENUM "0", "1";
BA_DEF_ BO_  "VFrameFormat" ENUM "StandardCAN", "ExtendedCAN", "reserved", "reserved", "reserved", "reserved", "reserved", "reserved", "reserved", "reserved", "reserved", "reserved", "reserved", "reserved", "StandardCAN_FD", "ExtendedCAN_FD";
BA_DEF_ SG_  "GenSigActiveRepetitions" INT -2147483648 2147483647;
BA_DEF_ SG_  "GenSigInactiveValue" INT -2147483648 2147483647;
BA_DEF_ SG_  "GenSigSendType" ENUM "Cyclic", "OnWrite", "OnWriteWithRepetition", "OnChange", "OnChangeWithRepetition", "IfActive", "IfActiveWithRepetition", "NoSigSendType", "OnChangeAndIfActive", "OnChangeAndIfActiveWithRepetition";
BA_DEF_ SG_  "GenSigStartValue" INT -2147483648 2147483647;
BA_DEF_ SG_  "NWM-WakeupAllowed" ENUM "No", "Yes";
BA_DEF_ SG_  "GenSigFuncType" ENUM "NoFunction", "MsgCounter", "CRC-8", "XOR", "XOR-2", "DatedBit", "SW-Kl15", "CHK", "Constant", "Protocol", "CRC-8-SAE_J1850", "CRC-32", "DataLength", "DataID", "MsgCounter16", "SOK-Signatur", "Cluster";
BA_DEF_ SG_  "GenSigSwitchedByIgnition" ENUM "No", "Yes";
BA_DEF_ SG_  "Fehlerwert" HEX 0 2147483647;
BA_DEF_ SG_  "GenSigMissingSourceValue" HEX 0 2147483647;
BA_DEF_DEF_REL_  "GenSigTimeoutTime" 0;
BA_DEF_DEF_  "DiagRequest" "No";
BA_DEF_DEF_  "DiagResponse" "No";
BA_DEF_DEF_  "DiagState" "No";
BA_DEF_DEF_  "GenMsgChkConstant" 0;
BA_DEF_DEF_  "GenMsgCycleTime" 0;
BA_DEF_DEF_  "GenMsgCycleTimeFast" 0;
BA_DEF_DEF_  "GenMsgDelayTime" 0;
BA_DEF_DEF_  "GenMsgILSupport" "No";
BA_DEF_DEF_  "GenMsgNrOfRepetition" 0;
BA_DEF_DEF_  "GenMsgPDUConstants" "";
BA_DEF_DEF_  "GenMsgSendType" "NoMsgSendType";
BA_DEF_DEF_  "GenMsgStartDelayTime" 0;
BA_DEF_DEF_  "NmMessage" "No";
BA_DEF_DEF_  "NmhMessage" "No";
BA_DEF_DEF_  "MsgType" "Application";
BA_DEF_DEF_  "VAGTP20_API" 0;
BA_DEF_DEF_  "VAGTP20_DynConnection" "No";
BA_DEF_DEF_  "VAGTP20_DynSetup" "No";
BA_DEF_DEF_  "VAGTP20_StatConnection" "No";
BA_DEF_DEF_  "CANFD_BRS" "1";
BA_DEF_DEF_  "VFrameFormat" "StandardCAN";
BA_DEF_DEF_  "GenSigActiveRepetitions" 0;
BA_DEF_DEF_  "GenSigInactiveValue" 0;
BA_DEF_DEF_  "GenSigSendType" "NoSigSendType";
BA_DEF_DEF_  "GenSigStartValue" 0;
BA_DEF_DEF_  "NWM-WakeupAllowed" "No";
BA_DEF_DEF_  "GenSigFuncType" "NoFunction";
BA_DEF_DEF_  "GenSigSwitchedByIgnition" "Yes";
BA_DEF_DEF_  "Fehlerwert" 0;
BA_DEF_DEF_  "GenSigMissingSourceValue" 0;
BA_ "GenMsgCycleTime" BO_ 1031 100;
BA_ "GenMsgILSupport" BO_ 1031 1;
BA_ "GenMsgPDUConstants" BO_ 1031 "0xef,0x60,0x04,0xa8,0x0c,0x1c,0xda,0x07,0x36,0xd7,0x28,0x92,0xa9,0x88,0x2c,0x4a";
BA_ "GenMsgSendType" BO_ 1031 0;
BA_ "CANFD_BRS" BO_ 1031 0;
BA_ "VFrameFormat" BO_ 1031 14;
BA_ "GenMsgCycleTime" BO_ 319 200;
BA_ "GenMsgDelayTime" BO_ 319 20;
BA_ "GenMsgILSupport" BO_ 319 1;
BA_ "GenMsgPDUConstants" BO_ 319 "0x28,0x6e,0x5a,0xc6,0x52,0x65,0x85,0xa1,0xb8,0xe6,0x38,0x88,0xf8,0xb9,0x2b,0xb0";
BA_ "GenMsgSendType" BO_ 319 0;
BA_ "CANFD_BRS" BO_ 319 0;
BA_ "VFrameFormat" BO_ 319 14;
BA_ "GenMsgCycleTime" BO_ 1616 1000;
BA_ "GenMsgDelayTime" BO_ 1616 50;
BA_ "GenMsgILSupport" BO_ 1616 1;
BA_ "GenMsgSendType" BO_ 1616 0;
BA_ "CANFD_BRS" BO_ 1616 0;
BA_ "VFrameFormat" BO_ 1616 14;
BA_ "GenMsgCycleTime" BO_ 695 50;
BA_ "GenMsgILSupport" BO_ 695 1;
BA_ "GenMsgPDUConstants" BO_ 695 "0x5e,0xc7,0x04,0x11,0x4d,0x27,0x0d,0x31,0x91,0xb8,0x62,0x76,0x64,0x09,0xeb,0xec";
BA_ "GenMsgSendType" BO_ 695 0;
BA_ "CANFD_BRS" BO_ 695 0;
BA_ "VFrameFormat" BO_ 695 14;
BA_ "GenMsgCycleTime" BO_ 1711 1000;
BA_ "GenMsgDelayTime" BO_ 1711 50;
BA_ "GenMsgILSupport" BO_ 1711 1;
BA_ "GenMsgSendType" BO_ 1711 0;
BA_ "CANFD_BRS" BO_ 1711 0;
BA_ "VFrameFormat" BO_ 1711 14;
BA_ "GenMsgCycleTime" BO_ 2264486920 200;
BA_ "GenMsgDelayTime" BO_ 2264486920 20;
BA_ "GenMsgILSupport" BO_ 2264486920 1;
BA_ "GenMsgPDUConstants" BO_ 2264486920 "0x41,0x87,0x40,0x5d,0x39,0xbe,0x1b,0x88,0x76,0xf9,0xb3,0x17,0xb6,0x0a,0xd8,0x84";
BA_ "GenMsgSendType" BO_ 2264486920 0;
BA_ "CANFD_BRS" BO_ 2264486920 0;
BA_ "VFrameFormat" BO_ 2264486920 15;
BA_ "GenMsgCycleTime" BO_ 1440 200;
BA_ "GenMsgILSupport" BO_ 1440 1;
BA_ "GenMsgSendType" BO_ 1440 0;
BA_ "CANFD_BRS" BO_ 1440 0;
BA_ "VFrameFormat" BO_ 1440 14;
BA_ "GenMsgCycleTime" BO_ 1504 500;
BA_ "GenMsgCycleTimeFast" BO_ 1504 100;
BA_ "GenMsgDelayTime" BO_ 1504 50;
BA_ "GenMsgILSupport" BO_ 1504 1;
BA_ "GenMsgNrOfRepetition" BO_ 1504 5;
BA_ "GenMsgSendType" BO_ 1504 0;
BA_ "CANFD_BRS" BO_ 1504 0;
BA_ "VFrameFormat" BO_ 1504 14;
BA_ "GenMsgCycleTime" BO_ 2463978698 1000;
BA_ "GenMsgCycleTimeFast" BO_ 2463978698 50;
BA_ "GenMsgDelayTime" BO_ 2463978698 10;
BA_ "GenMsgILSupport" BO_ 2463978698 1;
BA_ "GenMsgNrOfRepetition" BO_ 2463978698 5;
BA_ "GenMsgSendType" BO_ 2463978698 0;
BA_ "CANFD_BRS" BO_ 2463978698 0;
BA_ "VFrameFormat" BO_ 2463978698 15;
BA_ "GenMsgCycleTime" BO_ 2463978815 100;
BA_ "GenMsgDelayTime" BO_ 2463978815 10;
BA_ "GenMsgILSupport" BO_ 2463978815 1;
BA_ "GenMsgPDUConstants" BO_ 2463978815 "0x76,0xf4,0x74,0x70,0xb2,0xcd,0xdb,0x06,0xae,0x14,0x25,0x86,0x20,0x24,0x82,0xd0";
BA_ "GenMsgSendType" BO_ 2463978815 0;
BA_ "CANFD_BRS" BO_ 2463978815 0;
BA_ "VFrameFormat" BO_ 2463978815 15;
BA_ "GenMsgCycleTime" BO_ 1522 200;
BA_ "GenMsgDelayTime" BO_ 1522 50;
BA_ "GenMsgILSupport" BO_ 1522 1;
BA_ "GenMsgSendType" BO_ 1522 0;
BA_ "CANFD_BRS" BO_ 1522 0;
BA_ "VFrameFormat" BO_ 1522 14;
BA_ "GenMsgCycleTimeFast" BO_ 1167 100;
BA_ "GenMsgILSupport" BO_ 1167 1;
BA_ "GenMsgSendType" BO_ 1167 7;
BA_ "CANFD_BRS" BO_ 1167 0;
BA_ "VFrameFormat" BO_ 1167 14;
BA_ "GenMsgCycleTime" BO_ 201 200;
BA_ "GenMsgCycleTimeFast" BO_ 201 20;
BA_ "GenMsgDelayTime" BO_ 201 20;
BA_ "GenMsgILSupport" BO_ 201 1;
BA_ "GenMsgNrOfRepetition" BO_ 201 5;
BA_ "GenMsgSendType" BO_ 201 0;
BA_ "CANFD_BRS" BO_ 201 0;
BA_ "VFrameFormat" BO_ 201 14;
BA_ "GenMsgCycleTime" BO_ 2527679651 200;
BA_ "GenMsgILSupport" BO_ 2527679651 1;
BA_ "GenMsgSendType" BO_ 2527679651 0;
BA_ "CANFD_BRS" BO_ 2527679651 0;
BA_ "VFrameFormat" BO_ 2527679651 15;
BA_ "GenMsgCycleTime" BO_ 980 1000;
BA_ "GenMsgCycleTimeFast" BO_ 980 100;
BA_ "GenMsgDelayTime" BO_ 980 50;
BA_ "GenMsgILSupport" BO_ 980 1;
BA_ "GenMsgNrOfRepetition" BO_ 980 5;
BA_ "GenMsgPDUConstants" BO_ 980 "0xc3,0x79,0xbf,0xdb,0xe9,0x11,0x46,0x86,0x69,0xb6,0x9b,0x29,0x15,0x9c,0x45,0x0d";
BA_ "GenMsgSendType" BO_ 980 0;
BA_ "CANFD_BRS" BO_ 980 0;
BA_ "VFrameFormat" BO_ 980 14;
BA_ "GenMsgDelayTime" BO_ 2464161806 50;
BA_ "GenMsgILSupport" BO_ 2464161806 1;
BA_ "CANFD_BRS" BO_ 2464161806 0;
BA_ "VFrameFormat" BO_ 2464161806 15;
BA_ "GenMsgDelayTime" BO_ 2464296974 50;
BA_ "GenMsgILSupport" BO_ 2464296974 1;
BA_ "CANFD_BRS" BO_ 2464296974 0;
BA_ "VFrameFormat" BO_ 2464296974 15;
BA_ "GenMsgDelayTime" BO_ 2589283756 100;
BA_ "GenMsgILSupport" BO_ 2589283756 1;
BA_ "CANFD_BRS" BO_ 2589283756 0;
BA_ "VFrameFormat" BO_ 2589283756 15;
BA_ "GenMsgDelayTime" BO_ 2464153614 100;
BA_ "GenMsgILSupport" BO_ 2464153614 1;
BA_ "CANFD_BRS" BO_ 2464153614 0;
BA_ "VFrameFormat" BO_ 2464153614 15;
BA_ "GenMsgDelayTime" BO_ 2464284686 100;
BA_ "CANFD_BRS" BO_ 2464284686 0;
BA_ "VFrameFormat" BO_ 2464284686 15;
BA_ "GenMsgDelayTime" BO_ 2464288782 100;
BA_ "GenMsgILSupport" BO_ 2464288782 1;
BA_ "CANFD_BRS" BO_ 2464288782 0;
BA_ "VFrameFormat" BO_ 2464288782 15;
BA_ "GenMsgDelayTime" BO_ 2464153786 100;
BA_ "GenMsgILSupport" BO_ 2464153786 1;
BA_ "CANFD_BRS" BO_ 2464153786 0;
BA_ "VFrameFormat" BO_ 2464153786 15;
BA_ "GenMsgDelayTime" BO_ 2464284858 100;
BA_ "CANFD_BRS" BO_ 2464284858 0;
BA_ "VFrameFormat" BO_ 2464284858 15;
BA_ "GenMsgDelayTime" BO_ 2464288954 100;
BA_ "GenMsgILSupport" BO_ 2464288954 1;
BA_ "CANFD_BRS" BO_ 2464288954 0;
BA_ "VFrameFormat" BO_ 2464288954 15;
BA_ "GenMsgDelayTime" BO_ 2464153675 100;
BA_ "GenMsgILSupport" BO_ 2464153675 1;
BA_ "CANFD_BRS" BO_ 2464153675 0;
BA_ "VFrameFormat" BO_ 2464153675 15;
BA_ "GenMsgDelayTime" BO_ 2464284747 100;
BA_ "GenMsgILSupport" BO_ 2464284747 1;
BA_ "CANFD_BRS" BO_ 2464284747 0;
BA_ "VFrameFormat" BO_ 2464284747 15;
BA_ "GenMsgDelayTime" BO_ 2464153674 100;
BA_ "GenMsgILSupport" BO_ 2464153674 1;
BA_ "CANFD_BRS" BO_ 2464153674 0;
BA_ "VFrameFormat" BO_ 2464153674 15;
BA_ "GenMsgDelayTime" BO_ 2464284746 100;
BA_ "GenMsgILSupport" BO_ 2464284746 1;
BA_ "CANFD_BRS" BO_ 2464284746 0;
BA_ "VFrameFormat" BO_ 2464284746 15;
BA_ "GenMsgDelayTime" BO_ 2464153663 100;
BA_ "GenMsgILSupport" BO_ 2464153663 1;
BA_ "CANFD_BRS" BO_ 2464153663 0;
BA_ "VFrameFormat" BO_ 2464153663 15;
BA_ "GenMsgDelayTime" BO_ 2464284735 100;
BA_ "GenMsgILSupport" BO_ 2464284735 1;
BA_ "CANFD_BRS" BO_ 2464284735 0;
BA_ "VFrameFormat" BO_ 2464284735 15;
BA_ "GenMsgDelayTime" BO_ 2464153662 100;
BA_ "GenMsgILSupport" BO_ 2464153662 1;
BA_ "CANFD_BRS" BO_ 2464153662 0;
BA_ "VFrameFormat" BO_ 2464153662 15;
BA_ "GenMsgDelayTime" BO_ 2464284734 100;
BA_ "GenMsgILSupport" BO_ 2464284734 1;
BA_ "CANFD_BRS" BO_ 2464284734 0;
BA_ "VFrameFormat" BO_ 2464284734 15;
BA_ "GenMsgCycleTime" BO_ 1467 500;
BA_ "GenMsgILSupport" BO_ 1467 1;
BA_ "GenMsgSendType" BO_ 1467 0;
BA_ "CANFD_BRS" BO_ 1467 0;
BA_ "VFrameFormat" BO_ 1467 14;
BA_ "GenMsgCycleTime" BO_ 1710 1000;
BA_ "GenMsgCycleTimeFast" BO_ 1710 100;
BA_ "GenMsgDelayTime" BO_ 1710 50;
BA_ "GenMsgILSupport" BO_ 1710 1;
BA_ "GenMsgNrOfRepetition" BO_ 1710 5;
BA_ "GenMsgSendType" BO_ 1710 0;
BA_ "CANFD_BRS" BO_ 1710 0;
BA_ "VFrameFormat" BO_ 1710 14;
BA_ "GenMsgCycleTime" BO_ 2463978603 100;
BA_ "GenMsgCycleTimeFast" BO_ 2463978603 20;
BA_ "GenMsgDelayTime" BO_ 2463978603 10;
BA_ "GenMsgILSupport" BO_ 2463978603 1;
BA_ "GenMsgNrOfRepetition" BO_ 2463978603 10;
BA_ "GenMsgPDUConstants" BO_ 2463978603 "0x60,0x53,0x4e,0xfb,0x73,0x56,0xdd,0xbf,0x99,0xc2,0x82,0x3f,0x8f,0xd2,0x75,0x11";
BA_ "GenMsgSendType" BO_ 2463978603 0;
BA_ "CANFD_BRS" BO_ 2463978603 0;
BA_ "VFrameFormat" BO_ 2463978603 15;
BA_ "GenMsgCycleTime" BO_ 1313 200;
BA_ "GenMsgILSupport" BO_ 1313 1;
BA_ "GenMsgSendType" BO_ 1313 0;
BA_ "CANFD_BRS" BO_ 1313 0;
BA_ "VFrameFormat" BO_ 1313 14;
BA_ "GenMsgCycleTime" BO_ 832 100;
BA_ "GenMsgDelayTime" BO_ 832 20;
BA_ "GenMsgILSupport" BO_ 832 1;
BA_ "GenMsgSendType" BO_ 832 0;
BA_ "CANFD_BRS" BO_ 832 0;
BA_ "VFrameFormat" BO_ 832 14;
BA_ "GenSigSendType" SG_ 1031 PLA_04_BZ 0;
BA_ "GenSigFuncType" SG_ 1031 PLA_04_BZ 1;
BA_ "GenSigSwitchedByIgnition" SG_ 1031 PLA_04_BZ 0;
BA_ "GenSigSendType" SG_ 1031 PLA_04_CRC 0;
BA_ "GenSigFuncType" SG_ 1031 PLA_04_CRC 2;
BA_ "GenSigSwitchedByIgnition" SG_ 1031 PLA_04_CRC 0;
BA_ "GenSigSendType" SG_ 1031 PLAIPA_PaCo_Button 0;
BA_ "GenSigSwitchedByIgnition" SG_ 1031 PLAIPA_PaCo_Button 0;
BA_ "GenSigSendType" SG_ 1031 PLAIPA_PaCo_FunctionState 0;
BA_ "GenSigStartValue" SG_ 1031 PLAIPA_PaCo_FunctionState 1;
BA_ "GenSigSwitchedByIgnition" SG_ 1031 PLAIPA_PaCo_FunctionState 0;
BA_ "GenSigSendType" SG_ 1031 PLAIPA_PaCo_GarageActivatable 0;
BA_ "GenSigSwitchedByIgnition" SG_ 1031 PLAIPA_PaCo_GarageActivatable 0;
BA_ "GenSigSendType" SG_ 1031 PLAIPA_PaCo_InterventionPossible 0;
BA_ "GenSigSwitchedByIgnition" SG_ 1031 PLAIPA_PaCo_InterventionPossible 0;
BA_ "GenSigSendType" SG_ 1031 PLAIPA_PaCo_MainState 0;
BA_ "GenSigSwitchedByIgnition" SG_ 1031 PLAIPA_PaCo_MainState 0;
BA_ "Fehlerwert" SG_ 1031 PLAIPA_PaCo_MainState 7;
BA_ "GenSigSendType" SG_ 1031 PLAIPA_PaCo_ParkingSlots 0;
BA_ "GenSigSwitchedByIgnition" SG_ 1031 PLAIPA_PaCo_ParkingSlots 0;
BA_ "GenSigSendType" SG_ 1031 PLAIPA_PaCo_ParkingSlots_02 0;
BA_ "GenSigSwitchedByIgnition" SG_ 1031 PLAIPA_PaCo_ParkingSlots_02 0;
BA_ "GenSigSendType" SG_ 1031 PLAIPA_PaCo_PLEPossible 0;
BA_ "GenSigSwitchedByIgnition" SG_ 1031 PLAIPA_PaCo_PLEPossible 0;
BA_ "GenSigSendType" SG_ 1031 PLAIPA_PaCo_RemoteActivatable 0;
BA_ "GenSigSwitchedByIgnition" SG_ 1031 PLAIPA_PaCo_RemoteActivatable 0;
BA_ "GenSigSendType" SG_ 1031 PLAIPA_PaCo_SwitchPossible 0;
BA_ "GenSigSwitchedByIgnition" SG_ 1031 PLAIPA_PaCo_SwitchPossible 0;
BA_ "GenSigSendType" SG_ 1031 PLAIPA_PaCo_UnavailableReason 0;
BA_ "GenSigSwitchedByIgnition" SG_ 1031 PLAIPA_PaCo_UnavailableReason 0;
BA_ "GenSigSendType" SG_ 1031 RA_PaCo_FunctionState 0;
BA_ "GenSigStartValue" SG_ 1031 RA_PaCo_FunctionState 7;
BA_ "GenSigSwitchedByIgnition" SG_ 1031 RA_PaCo_FunctionState 0;
BA_ "GenSigSendType" SG_ 1031 RA_PaCo_InterventionPossible 0;
BA_ "GenSigSwitchedByIgnition" SG_ 1031 RA_PaCo_InterventionPossible 0;
BA_ "GenSigSendType" SG_ 1031 RA_PaCo_MainState 0;
BA_ "GenSigSwitchedByIgnition" SG_ 1031 RA_PaCo_MainState 0;
BA_ "Fehlerwert" SG_ 1031 RA_PaCo_MainState 2;
BA_ "GenSigSendType" SG_ 1031 RA_PaCo_UnavailableReason 0;
BA_ "GenSigSwitchedByIgnition" SG_ 1031 RA_PaCo_UnavailableReason 0;
BA_ "GenSigSendType" SG_ 1031 RPA_Anf_Sonder_Funktion_Status 0;
BA_ "GenSigSwitchedByIgnition" SG_ 1031 RPA_Anf_Sonder_Funktion_Status 0;
BA_ "GenSigSendType" SG_ 1031 RPA_Anf_Sonder_Klemme_15 0;
BA_ "GenSigSwitchedByIgnition" SG_ 1031 RPA_Anf_Sonder_Klemme_15 0;
BA_ "GenSigSendType" SG_ 1031 RPA_Anf_WFS_Freigabe 0;
BA_ "GenSigSwitchedByIgnition" SG_ 1031 RPA_Anf_WFS_Freigabe 0;
BA_ "GenSigSendType" SG_ 319 PreCrash_Anforderung_AFR 3;
BA_ "GenSigStartValue" SG_ 319 PreCrash_Anforderung_AFR 7;
BA_ "GenSigSwitchedByIgnition" SG_ 319 PreCrash_Anforderung_AFR 0;
BA_ "GenSigSendType" SG_ 319 PreCrash_BFS_KSV_verfahren 3;
BA_ "GenSigSwitchedByIgnition" SG_ 319 PreCrash_BFS_KSV_verfahren 0;
BA_ "GenSigSendType" SG_ 319 PreCrash_BFS_Laengsverstellung 3;
BA_ "GenSigSwitchedByIgnition" SG_ 319 PreCrash_BFS_Laengsverstellung 0;
BA_ "GenSigSendType" SG_ 319 PreCrash_BFS_Pneumatik_ansteuern 3;
BA_ "GenSigSwitchedByIgnition" SG_ 319 PreCrash_BFS_Pneumatik_ansteuern 0;
BA_ "GenSigSendType" SG_ 319 PreCrash_BFS_Sitzlehne_verfahren 3;
BA_ "GenSigSwitchedByIgnition" SG_ 319 PreCrash_BFS_Sitzlehne_verfahren 0;
BA_ "GenSigSendType" SG_ 319 PreCrash_Blinken 3;
BA_ "GenSigSendType" SG_ 319 PreCrash_Charisma_FahrPr 0;
BA_ "GenSigSendType" SG_ 319 PreCrash_Charisma_Status 0;
BA_ "GenSigSendType" SG_ 319 PreCrash_Fenster_schliessen 3;
BA_ "GenSigSendType" SG_ 319 PreCrash_Fo_KSV_verfahren 3;
BA_ "GenSigSendType" SG_ 319 PreCrash_Fo_Pneumatik_ansteuern 3;
BA_ "GenSigSendType" SG_ 319 PreCrash_Fo_Sitzlehne_verfahren 3;
BA_ "GenSigSwitchedByIgnition" SG_ 319 PreCrash_Fo_Sitzlehne_verfahren 0;
BA_ "GenSigSendType" SG_ 319 PreCrash_FS_KSV_verfahren 3;
BA_ "GenSigSwitchedByIgnition" SG_ 319 PreCrash_FS_KSV_verfahren 0;
BA_ "GenSigSendType" SG_ 319 PreCrash_FS_Laengsverstellung 3;
BA_ "GenSigSwitchedByIgnition" SG_ 319 PreCrash_FS_Laengsverstellung 0;
BA_ "GenSigSendType" SG_ 319 PreCrash_FS_Pneumatik_ansteuern 3;
BA_ "GenSigSwitchedByIgnition" SG_ 319 PreCrash_FS_Pneumatik_ansteuern 0;
BA_ "GenSigSendType" SG_ 319 PreCrash_FS_Sitzlehne_verfahren 3;
BA_ "GenSigSwitchedByIgnition" SG_ 319 PreCrash_FS_Sitzlehne_verfahren 0;
BA_ "GenSigSendType" SG_ 319 PreCrash_Schiebedach_schliessen 3;
BA_ "GenSigSendType" SG_ 319 PreCrash_Tueren_Verriegeln 3;
BA_ "GenSigSwitchedByIgnition" SG_ 319 PreCrash_Tueren_Verriegeln 0;
BA_ "GenSigSendType" SG_ 319 SC_PreCrash_LED 3;
BA_ "GenSigSwitchedByIgnition" SG_ 319 SC_PreCrash_LED 0;
BA_ "GenSigSendType" SG_ 319 SC_PreCrash_Texte 3;
BA_ "GenSigSwitchedByIgnition" SG_ 319 SC_PreCrash_Texte 0;
BA_ "GenSigSendType" SG_ 319 SC_PreCrash_Warnung 3;
BA_ "GenSigSwitchedByIgnition" SG_ 319 SC_PreCrash_Warnung 0;
BA_ "GenSigSendType" SG_ 319 SC_PreSense_FCWP 3;
BA_ "GenSigSwitchedByIgnition" SG_ 319 SC_PreSense_FCWP 0;
BA_ "GenSigSendType" SG_ 1616 RA_AM_Tuning 3;
BA_ "GenSigSwitchedByIgnition" SG_ 1616 RA_AM_Tuning 0;
BA_ "GenSigSendType" SG_ 1616 RA_Frequency 3;
BA_ "GenSigSwitchedByIgnition" SG_ 1616 RA_Frequency 0;
BA_ "GenSigSendType" SG_ 1616 RA_Frequency_unit 3;
BA_ "GenSigSwitchedByIgnition" SG_ 1616 RA_Frequency_unit 0;
BA_ "GenSigSendType" SG_ 1616 RA_PowerAmpOn 3;
BA_ "GenSigSwitchedByIgnition" SG_ 1616 RA_PowerAmpOn 0;
BA_ "GenSigSendType" SG_ 1616 RA_Radio_Error_Flag 3;
BA_ "GenSigSwitchedByIgnition" SG_ 1616 RA_Radio_Error_Flag 0;
BA_ "GenSigSendType" SG_ 1616 RA_Radio_mute 3;
BA_ "GenSigSwitchedByIgnition" SG_ 1616 RA_Radio_mute 0;
BA_ "GenSigSendType" SG_ 1616 RA_Radio_on 3;
BA_ "GenSigSwitchedByIgnition" SG_ 1616 RA_Radio_on 0;
BA_ "GenSigSendType" SG_ 1616 RA_Radio_Surround 3;
BA_ "GenSigSwitchedByIgnition" SG_ 1616 RA_Radio_Surround 0;
BA_ "GenSigSendType" SG_ 1616 RA_VNC_OFF 3;
BA_ "GenSigSwitchedByIgnition" SG_ 1616 RA_VNC_OFF 0;
BA_ "GenSigSendType" SG_ 695 RCTA_01_BZ 0;
BA_ "GenSigFuncType" SG_ 695 RCTA_01_BZ 1;
BA_ "GenSigSendType" SG_ 695 RCTA_01_CRC 0;
BA_ "GenSigFuncType" SG_ 695 RCTA_01_CRC 2;
BA_ "GenSigSendType" SG_ 695 RCTA_Anf_Warnruck 0;
BA_ "GenSigSendType" SG_ 695 RCTA_Anforderung_HMS 0;
BA_ "GenSigSendType" SG_ 695 RCTA_Bremsruck_Anforderung 0;
BA_ "GenSigSendType" SG_ 695 RCTA_Bremsruck_Freigabe 0;
BA_ "GenSigSendType" SG_ 695 RCTA_Info_links 0;
BA_ "GenSigSendType" SG_ 695 RCTA_Info_rechts 0;
BA_ "GenSigSendType" SG_ 695 RCTA_Kritikalitaetslevel_links 0;
BA_ "GenSigSendType" SG_ 695 RCTA_Kritikalitaetslevel_rechts 0;
BA_ "GenSigSendType" SG_ 695 RCTA_Modus 0;
BA_ "GenSigSendType" SG_ 695 RCTA_Notbremsung_Anforderung 0;
BA_ "Fehlerwert" SG_ 695 RCTA_Notbremsung_Anforderung 255;
BA_ "GenSigSendType" SG_ 695 RCTA_Notbremsung_Freigabe 0;
BA_ "GenSigSendType" SG_ 695 RCTA_PaCo_BrakeIntervention 0;
BA_ "GenSigSwitchedByIgnition" SG_ 695 RCTA_PaCo_BrakeIntervention 0;
BA_ "GenSigSendType" SG_ 695 RCTA_PaCo_BrakingPossible 0;
BA_ "GenSigSwitchedByIgnition" SG_ 695 RCTA_PaCo_BrakingPossible 0;
BA_ "GenSigSendType" SG_ 695 RCTA_PaCo_MainState 0;
BA_ "GenSigSwitchedByIgnition" SG_ 695 RCTA_PaCo_MainState 0;
BA_ "Fehlerwert" SG_ 695 RCTA_PaCo_MainState 7;
BA_ "GenSigSendType" SG_ 695 RCTA_PaCo_UnavailableReason 0;
BA_ "GenSigSwitchedByIgnition" SG_ 695 RCTA_PaCo_UnavailableReason 0;
BA_ "GenSigSendType" SG_ 695 RCTA_Status 0;
BA_ "Fehlerwert" SG_ 695 RCTA_Status 3;
BA_ "GenSigSendType" SG_ 695 RCTA_Status_FoD 0;
BA_ "GenSigSwitchedByIgnition" SG_ 695 RCTA_Status_FoD 0;
BA_ "GenSigSendType" SG_ 695 RCTA_Warnton 0;
BA_ "GenSigSendType" SG_ 1711 RV_Calib_Fehler 3;
BA_ "GenSigSwitchedByIgnition" SG_ 1711 RV_Calib_Fehler 0;
BA_ "GenSigSendType" SG_ 1711 RV_Dark_Screen 3;
BA_ "GenSigSwitchedByIgnition" SG_ 1711 RV_Dark_Screen 0;
BA_ "GenSigSendType" SG_ 1711 RV_Farbe 3;
BA_ "GenSigSwitchedByIgnition" SG_ 1711 RV_Farbe 0;
BA_ "GenSigSendType" SG_ 1711 RV_GL_LWS_Fehler 3;
BA_ "GenSigSwitchedByIgnition" SG_ 1711 RV_GL_LWS_Fehler 0;
BA_ "GenSigSendType" SG_ 1711 RV_GL_side 3;
BA_ "GenSigSendType" SG_ 1711 RV_GL_Trailer_connect 3;
BA_ "GenSigSwitchedByIgnition" SG_ 1711 RV_GL_Trailer_connect 0;
BA_ "GenSigSendType" SG_ 1711 RV_GL_Trunk_open 3;
BA_ "GenSigSwitchedByIgnition" SG_ 1711 RV_GL_Trunk_open 0;
BA_ "GenSigSendType" SG_ 1711 RV_Helligkeit 3;
BA_ "GenSigSwitchedByIgnition" SG_ 1711 RV_Helligkeit 0;
BA_ "GenSigSendType" SG_ 1711 RV_HMI_Mode 3;
BA_ "GenSigSwitchedByIgnition" SG_ 1711 RV_HMI_Mode 0;
BA_ "GenSigSendType" SG_ 1711 RV_Kontrast 3;
BA_ "GenSigSwitchedByIgnition" SG_ 1711 RV_Kontrast 0;
BA_ "GenSigSendType" SG_ 1711 RV_Menu_Item 3;
BA_ "GenSigSwitchedByIgnition" SG_ 1711 RV_Menu_Item 0;
BA_ "GenSigSendType" SG_ 1711 RV_Reinigung_Anf 3;
BA_ "GenSigSwitchedByIgnition" SG_ 1711 RV_Reinigung_Anf 0;
BA_ "GenSigSendType" SG_ 1711 RV_Settings_enabled 3;
BA_ "GenSigSwitchedByIgnition" SG_ 1711 RV_Settings_enabled 0;
BA_ "GenSigSendType" SG_ 1711 RV_System_aktiv 3;
BA_ "GenSigSwitchedByIgnition" SG_ 1711 RV_System_aktiv 0;
BA_ "GenSigSendType" SG_ 1711 RV_Video_on 3;
BA_ "GenSigSwitchedByIgnition" SG_ 1711 RV_Video_on 0;
BA_ "GenSigSendType" SG_ 1711 SV_Video_on 3;
BA_ "GenSigSendType" SG_ 1711 ZFAS_Umfeldbeleuchtung_Anf 3;
BA_ "GenSigSwitchedByIgnition" SG_ 1711 ZFAS_Umfeldbeleuchtung_Anf 0;
BA_ "GenSigSendType" SG_ 2264486920 RHP_01_BZ 0;
BA_ "GenSigFuncType" SG_ 2264486920 RHP_01_BZ 1;
BA_ "GenSigSwitchedByIgnition" SG_ 2264486920 RHP_01_BZ 0;
BA_ "GenSigSendType" SG_ 2264486920 RHP_01_CRC 0;
BA_ "GenSigFuncType" SG_ 2264486920 RHP_01_CRC 2;
BA_ "GenSigSwitchedByIgnition" SG_ 2264486920 RHP_01_CRC 0;
BA_ "GenSigSendType" SG_ 2264486920 RHP_Anf_ASIL 0;
BA_ "GenSigSendType" SG_ 2264486920 RHP_Anforderung_HMS 0;
BA_ "GenSigSwitchedByIgnition" SG_ 2264486920 RHP_Anforderung_HMS 0;
BA_ "GenSigSendType" SG_ 2264486920 RHP_EA_AnfStat 0;
BA_ "GenSigSendType" SG_ 2264486920 RHP_EA_eCall 0;
BA_ "GenSigSendType" SG_ 2264486920 RHP_EA_Innenraumlicht 0;
BA_ "GenSigSendType" SG_ 2264486920 RHP_EA_PreCrash 0;
BA_ "GenSigSendType" SG_ 2264486920 RHP_EA_Tueren 0;
BA_ "GenSigSendType" SG_ 2264486920 RHP_eCall_Anf 0;
BA_ "GenSigSwitchedByIgnition" SG_ 2264486920 RHP_eCall_Anf 0;
BA_ "GenSigSendType" SG_ 2264486920 RHP_Fahrzeughupe_Anf 3;
BA_ "GenSigSwitchedByIgnition" SG_ 2264486920 RHP_Fahrzeughupe_Anf 0;
BA_ "GenSigSendType" SG_ 2264486920 RHP_Freilaufstrategie_TSK 0;
BA_ "GenSigSendType" SG_ 2264486920 RHP_HOS 0;
BA_ "GenSigSendType" SG_ 2264486920 RHP_Innenraumlicht_Anf 3;
BA_ "GenSigSendType" SG_ 2264486920 RHP_Minimale_Bremsung 0;
BA_ "GenSigSendType" SG_ 2264486920 RHP_nachtr_Stopp_Anf 0;
BA_ "GenSigSwitchedByIgnition" SG_ 2264486920 RHP_nachtr_Stopp_Anf 0;
BA_ "GenSigSendType" SG_ 2264486920 RHP_neg_Sollbeschl_Grad 0;
BA_ "GenSigSendType" SG_ 2264486920 RHP_OPSEnable 0;
BA_ "GenSigSwitchedByIgnition" SG_ 2264486920 RHP_OPSEnable 0;
BA_ "GenSigSendType" SG_ 2264486920 RHP_Parking_St 0;
BA_ "GenSigSwitchedByIgnition" SG_ 2264486920 RHP_Parking_St 0;
BA_ "GenSigSendType" SG_ 2264486920 RHP_pos_Sollbeschl_Grad 0;
BA_ "GenSigSwitchedByIgnition" SG_ 2264486920 RHP_pos_Sollbeschl_Grad 0;
BA_ "GenSigSendType" SG_ 2264486920 RHP_PreCrash_Anf 0;
BA_ "GenSigSendType" SG_ 2264486920 RHP_QFK_AnfStat 0;
BA_ "GenSigStartValue" SG_ 2264486920 RHP_QFK_AnfStat 1;
BA_ "GenSigSendType" SG_ 2264486920 RHP_QFK_Art1 0;
BA_ "GenSigSwitchedByIgnition" SG_ 2264486920 RHP_QFK_Art1 0;
BA_ "GenSigSendType" SG_ 2264486920 RHP_QFK_Art2 0;
BA_ "GenSigSendType" SG_ 2264486920 RHP_QFK_KrSoll 0;
BA_ "GenSigSendType" SG_ 2264486920 RHP_QFK_KrSoll_VZ 0;
BA_ "GenSigSendType" SG_ 2264486920 RHP_QFK_KruemmSoll 0;
BA_ "GenSigSendType" SG_ 2264486920 RHP_QFK_KruemmSoll_VZ 0;
BA_ "GenSigSendType" SG_ 2264486920 RHP_QFK_Signal1 0;
BA_ "GenSigSwitchedByIgnition" SG_ 2264486920 RHP_QFK_Signal1 0;
BA_ "GenSigSendType" SG_ 2264486920 RHP_QFK_Signal2 0;
BA_ "GenSigSendType" SG_ 2264486920 RHP_QFK_Spuerb 0;
BA_ "GenSigSendType" SG_ 2264486920 RHP_RBF_Available 0;
BA_ "GenSigSwitchedByIgnition" SG_ 2264486920 RHP_RBF_Available 0;
BA_ "GenSigSendType" SG_ 2264486920 RHP_Ruckfreigabe 0;
BA_ "GenSigSwitchedByIgnition" SG_ 2264486920 RHP_Ruckfreigabe 0;
BA_ "GenSigSendType" SG_ 2264486920 RHP_SCAM_HeatingRequest 0;
BA_ "GenSigSendType" SG_ 2264486920 RHP_Sollbeschleunigung 0;
BA_ "GenSigStartValue" SG_ 2264486920 RHP_Sollbeschleunigung 2046;
BA_ "Fehlerwert" SG_ 2264486920 RHP_Sollbeschleunigung 2047;
BA_ "GenSigSendType" SG_ 2264486920 RHP_Spurwechsel_Ready 3;
BA_ "GenSigSwitchedByIgnition" SG_ 2264486920 RHP_Spurwechsel_Ready 0;
BA_ "GenSigSendType" SG_ 2264486920 RHP_StartStopp_Info 0;
BA_ "GenSigSendType" SG_ 2264486920 RHP_Status_Function 0;
BA_ "GenSigSwitchedByIgnition" SG_ 2264486920 RHP_Status_Function 0;
BA_ "GenSigSendType" SG_ 2264486920 RHP_Status_Lat 0;
BA_ "GenSigSendType" SG_ 2264486920 RHP_Status_Long 0;
BA_ "GenSigSendType" SG_ 2264486920 RHP_TSK_Status 0;
BA_ "GenSigStartValue" SG_ 2264486920 RHP_TSK_Status 1;
BA_ "GenSigSendType" SG_ 2264486920 RHP_TV_Trigger 0;
BA_ "GenSigSwitchedByIgnition" SG_ 2264486920 RHP_TV_Trigger 0;
BA_ "GenSigSendType" SG_ 2264486920 RHP_Uss_Anforderung 0;
BA_ "GenSigSwitchedByIgnition" SG_ 2264486920 RHP_Uss_Anforderung 0;
BA_ "GenSigSendType" SG_ 2264486920 RHP_Verz_Anf 0;
BA_ "GenSigStartValue" SG_ 2264486920 RHP_Verz_Anf 1023;
BA_ "GenSigSendType" SG_ 2264486920 RHP_Verz_Freigabe 0;
BA_ "GenSigSendType" SG_ 2264486920 RHP_Warnblinken 3;
BA_ "GenSigSwitchedByIgnition" SG_ 2264486920 RHP_Warnblinken 0;
BA_ "GenSigSendType" SG_ 2264486920 RHP_Warnruckeln_Anf 0;
BA_ "GenSigSendType" SG_ 2264486920 RHP_zul_Regelabw_oben 0;
BA_ "GenSigSendType" SG_ 2264486920 RHP_zul_Regelabw_unten 0;
BA_ "GenSigSendType" SG_ 1440 LS_defekt 0;
BA_ "GenSigSwitchedByIgnition" SG_ 1440 LS_defekt 0;
BA_ "GenSigSendType" SG_ 1440 LS_Helligkeit_FW 0;
BA_ "GenSigStartValue" SG_ 1440 LS_Helligkeit_FW 1022;
BA_ "GenSigSwitchedByIgnition" SG_ 1440 LS_Helligkeit_FW 0;
BA_ "Fehlerwert" SG_ 1440 LS_Helligkeit_FW 1023;
BA_ "GenSigMissingSourceValue" SG_ 1440 LS_Helligkeit_FW 1023;
BA_ "GenSigSendType" SG_ 1440 LS_Helligkeit_IR 0;
BA_ "GenSigStartValue" SG_ 1440 LS_Helligkeit_IR 254;
BA_ "GenSigSwitchedByIgnition" SG_ 1440 LS_Helligkeit_IR 0;
BA_ "Fehlerwert" SG_ 1440 LS_Helligkeit_IR 255;
BA_ "GenSigMissingSourceValue" SG_ 1440 LS_Helligkeit_IR 255;
BA_ "GenSigSendType" SG_ 1440 LS_Verbau 0;
BA_ "GenSigSwitchedByIgnition" SG_ 1440 LS_Verbau 0;
BA_ "GenSigSendType" SG_ 1440 RLS_Vorfeldhelligkeit_Boost 0;
BA_ "GenSigStartValue" SG_ 1440 RLS_Vorfeldhelligkeit_Boost 15;
BA_ "GenSigSwitchedByIgnition" SG_ 1440 RLS_Vorfeldhelligkeit_Boost 0;
BA_ "GenSigSendType" SG_ 1440 RS_defekt 0;
BA_ "GenSigSwitchedByIgnition" SG_ 1440 RS_defekt 0;
BA_ "GenSigSendType" SG_ 1440 RS_Regenmenge 0;
BA_ "GenSigStartValue" SG_ 1440 RS_Regenmenge 14;
BA_ "GenSigSwitchedByIgnition" SG_ 1440 RS_Regenmenge 0;
BA_ "Fehlerwert" SG_ 1440 RS_Regenmenge 15;
BA_ "GenSigMissingSourceValue" SG_ 1440 RS_Regenmenge 15;
BA_ "GenSigSendType" SG_ 1440 RS_Schwall 0;
BA_ "GenSigSwitchedByIgnition" SG_ 1440 RS_Schwall 0;
BA_ "GenSigSendType" SG_ 1440 RS_Verbau 0;
BA_ "GenSigSwitchedByIgnition" SG_ 1440 RS_Verbau 0;
BA_ "GenSigSendType" SG_ 1440 RS_Verglasung_schliessen 0;
BA_ "GenSigSwitchedByIgnition" SG_ 1440 RS_Verglasung_schliessen 0;
BA_ "GenSigSendType" SG_ 1440 RS_Wischergeschwindigkeit 0;
BA_ "GenSigSwitchedByIgnition" SG_ 1440 RS_Wischergeschwindigkeit 0;
BA_ "GenSigSendType" SG_ 1440 SLS_Helligkeit_IR 0;
BA_ "GenSigStartValue" SG_ 1440 SLS_Helligkeit_IR 254;
BA_ "GenSigSwitchedByIgnition" SG_ 1440 SLS_Helligkeit_IR 0;
BA_ "Fehlerwert" SG_ 1440 SLS_Helligkeit_IR 255;
BA_ "GenSigSendType" SG_ 1504 MD1_Lage 0;
BA_ "GenSigSwitchedByIgnition" SG_ 1504 MD1_Lage 0;
BA_ "GenSigSendType" SG_ 1504 MD1_Position 0;
BA_ "GenSigStartValue" SG_ 1504 MD1_Position 126;
BA_ "GenSigSwitchedByIgnition" SG_ 1504 MD1_Position 0;
BA_ "GenSigSendType" SG_ 1504 MD3_Lage 0;
BA_ "GenSigSwitchedByIgnition" SG_ 1504 MD3_Lage 0;
BA_ "GenSigSendType" SG_ 1504 MD3_Position 0;
BA_ "GenSigSwitchedByIgnition" SG_ 1504 MD3_Position 0;
BA_ "GenSigSendType" SG_ 1504 MRollo_Lage 0;
BA_ "GenSigSwitchedByIgnition" SG_ 1504 MRollo_Lage 0;
BA_ "GenSigSendType" SG_ 1504 MRollo_Position 0;
BA_ "GenSigStartValue" SG_ 1504 MRollo_Position 126;
BA_ "GenSigSwitchedByIgnition" SG_ 1504 MRollo_Position 0;
BA_ "GenSigSendType" SG_ 1504 Rollo_normiert 3;
BA_ "GenSigSwitchedByIgnition" SG_ 1504 Rollo_normiert 0;
BA_ "GenSigSendType" SG_ 1504 Rollo_Thermoschutz 3;
BA_ "GenSigSwitchedByIgnition" SG_ 1504 Rollo_Thermoschutz 0;
BA_ "GenSigSendType" SG_ 1504 Rollo_UEKB_aktiv 3;
BA_ "GenSigSwitchedByIgnition" SG_ 1504 Rollo_UEKB_aktiv 0;
BA_ "GenSigSendType" SG_ 1504 SAD_Anf_ESC_Zuschaltung 3;
BA_ "GenSigSwitchedByIgnition" SG_ 1504 SAD_Anf_ESC_Zuschaltung 0;
BA_ "GenSigSendType" SG_ 1504 SAD_normiert 3;
BA_ "GenSigSwitchedByIgnition" SG_ 1504 SAD_normiert 0;
BA_ "GenSigSendType" SG_ 1504 SAD_Taster_Deckel_hi 4;
BA_ "GenSigSwitchedByIgnition" SG_ 1504 SAD_Taster_Deckel_hi 0;
BA_ "GenSigSendType" SG_ 1504 SAD_Taster_Deckel_vo 4;
BA_ "GenSigSwitchedByIgnition" SG_ 1504 SAD_Taster_Deckel_vo 0;
BA_ "GenSigSendType" SG_ 1504 SAD_Taster_Rollo_hi 4;
BA_ "GenSigSwitchedByIgnition" SG_ 1504 SAD_Taster_Rollo_hi 0;
BA_ "GenSigSendType" SG_ 1504 SAD_Taster_Rollo_vo 4;
BA_ "GenSigSwitchedByIgnition" SG_ 1504 SAD_Taster_Rollo_vo 0;
BA_ "GenSigSendType" SG_ 1504 SAD_Thermoschutz 3;
BA_ "GenSigSwitchedByIgnition" SG_ 1504 SAD_Thermoschutz 0;
BA_ "GenSigSendType" SG_ 1504 SAD_UEKB_aktiv 3;
BA_ "GenSigSwitchedByIgnition" SG_ 1504 SAD_UEKB_aktiv 0;
BA_ "GenSigSendType" SG_ 2463978698 SAL_Ambex_CH_state 3;
BA_ "GenSigSwitchedByIgnition" SG_ 2463978698 SAL_Ambex_CH_state 0;
BA_ "GenSigSendType" SG_ 2463978698 SAL_Ambex_CH_time 3;
BA_ "GenSigSwitchedByIgnition" SG_ 2463978698 SAL_Ambex_CH_time 0;
BA_ "GenSigSendType" SG_ 2463978698 SAL_Ambex_LH_state 3;
BA_ "GenSigSwitchedByIgnition" SG_ 2463978698 SAL_Ambex_LH_state 0;
BA_ "GenSigSendType" SG_ 2463978698 SAL_Ambex_LH_time 3;
BA_ "GenSigSwitchedByIgnition" SG_ 2463978698 SAL_Ambex_LH_time 0;
BA_ "GenSigSendType" SG_ 2463978698 SAL_Ambex_Lichtsensor_ch_lh_ein 3;
BA_ "GenSigSwitchedByIgnition" SG_ 2463978698 SAL_Ambex_Lichtsensor_ch_lh_ein 0;
BA_ "GenSigSendType" SG_ 2463978698 SAL_EA_Blinken_Status 3;
BA_ "GenSigSwitchedByIgnition" SG_ 2463978698 SAL_EA_Blinken_Status 0;
BA_ "GenSigSendType" SG_ 2463978698 SAL_EA_Warnblinken 3;
BA_ "GenSigSwitchedByIgnition" SG_ 2463978698 SAL_EA_Warnblinken 0;
BA_ "GenSigSendType" SG_ 2463978698 SAL_Strg_Beleuchtung_WBT 4;
BA_ "GenSigStartValue" SG_ 2463978698 SAL_Strg_Beleuchtung_WBT 254;
BA_ "GenSigSwitchedByIgnition" SG_ 2463978698 SAL_Strg_Beleuchtung_WBT 0;
BA_ "Fehlerwert" SG_ 2463978698 SAL_Strg_Beleuchtung_WBT 255;
BA_ "GenSigSendType" SG_ 2463978815 SBM_01_BZ 0;
BA_ "GenSigFuncType" SG_ 2463978815 SBM_01_BZ 1;
BA_ "GenSigSwitchedByIgnition" SG_ 2463978815 SBM_01_BZ 0;
BA_ "GenSigSendType" SG_ 2463978815 SBM_01_CRC 0;
BA_ "GenSigFuncType" SG_ 2463978815 SBM_01_CRC 2;
BA_ "GenSigSwitchedByIgnition" SG_ 2463978815 SBM_01_CRC 0;
BA_ "GenSigSendType" SG_ 2463978815 SBM_FahrerAkt_Lenkradpaddle 3;
BA_ "GenSigSwitchedByIgnition" SG_ 2463978815 SBM_FahrerAkt_Lenkradpaddle 0;
BA_ "GenSigSendType" SG_ 2463978815 SBM_FahrerAkt_P_Taste 3;
BA_ "GenSigSwitchedByIgnition" SG_ 2463978815 SBM_FahrerAkt_P_Taste 0;
BA_ "GenSigSendType" SG_ 2463978815 SBM_FahrerAkt_Schaltbetaetigung 3;
BA_ "GenSigSwitchedByIgnition" SG_ 2463978815 SBM_FahrerAkt_Schaltbetaetigung 0;
BA_ "GenSigSendType" SG_ 2463978815 SBM_Veto_Fahrstufe_extern 3;
BA_ "GenSigSwitchedByIgnition" SG_ 2463978815 SBM_Veto_Fahrstufe_extern 0;
BA_ "Fehlerwert" SG_ 2463978815 SBM_Veto_Fahrstufe_extern 3;
BA_ "GenSigSendType" SG_ 1522 KBI_Dimmpoti 0;
BA_ "GenSigSwitchedByIgnition" SG_ 1522 KBI_Dimmpoti 0;
BA_ "Fehlerwert" SG_ 1522 KBI_Dimmpoti 127;
BA_ "GenSigSendType" SG_ 1522 KBI_Phototransistor 3;
BA_ "GenSigStartValue" SG_ 1522 KBI_Phototransistor 254;
BA_ "GenSigSwitchedByIgnition" SG_ 1522 KBI_Phototransistor 0;
BA_ "Fehlerwert" SG_ 1522 KBI_Phototransistor 255;
BA_ "GenSigSwitchedByIgnition" SG_ 1167 SK1_Key_Data_1 0;
BA_ "GenSigSwitchedByIgnition" SG_ 1167 SK1_Key_Data_10 0;
BA_ "GenSigSwitchedByIgnition" SG_ 1167 SK1_Key_Data_2 0;
BA_ "GenSigSwitchedByIgnition" SG_ 1167 SK1_Key_Data_3 0;
BA_ "GenSigSwitchedByIgnition" SG_ 1167 SK1_Key_Data_4 0;
BA_ "GenSigSwitchedByIgnition" SG_ 1167 SK1_Key_Data_5 0;
BA_ "GenSigSwitchedByIgnition" SG_ 1167 SK1_Key_Data_6 0;
BA_ "GenSigSwitchedByIgnition" SG_ 1167 SK1_Key_Data_7 0;
BA_ "GenSigSwitchedByIgnition" SG_ 1167 SK1_Key_Data_8 0;
BA_ "GenSigSwitchedByIgnition" SG_ 1167 SK1_Key_Data_9 0;
BA_ "GenSigSendType" SG_ 1167 SK1_MUX 3;
BA_ "GenSigSwitchedByIgnition" SG_ 1167 SK1_MUX 0;
BA_ "GenSigSendType" SG_ 201 SM_AFR_Standfkt_Anf 0;
BA_ "GenSigSwitchedByIgnition" SG_ 201 SM_AFR_Standfkt_Anf 0;
BA_ "GenSigSendType" SG_ 201 SM_AFR_Verbindungsstatus 0;
BA_ "GenSigSwitchedByIgnition" SG_ 201 SM_AFR_Verbindungsstatus 0;
BA_ "GenSigSendType" SG_ 201 SM_Anlernstatus 0;
BA_ "GenSigSwitchedByIgnition" SG_ 201 SM_Anlernstatus 0;
BA_ "GenSigSendType" SG_ 201 SM_App_Sperrzustand 0;
BA_ "GenSigSwitchedByIgnition" SG_ 201 SM_App_Sperrzustand 0;
BA_ "GenSigSendType" SG_ 201 SM_ARA_Gangwahl 0;
BA_ "GenSigSwitchedByIgnition" SG_ 201 SM_ARA_Gangwahl 0;
BA_ "GenSigSendType" SG_ 201 SM_ARA_Gaspedal 0;
BA_ "GenSigSwitchedByIgnition" SG_ 201 SM_ARA_Gaspedal 0;
BA_ "GenSigSendType" SG_ 201 SM_ARA_Knickwinkel_Soll 0;
BA_ "GenSigStartValue" SG_ 201 SM_ARA_Knickwinkel_Soll 254;
BA_ "GenSigSwitchedByIgnition" SG_ 201 SM_ARA_Knickwinkel_Soll 0;
BA_ "Fehlerwert" SG_ 201 SM_ARA_Knickwinkel_Soll 255;
BA_ "GenSigSendType" SG_ 201 SM_ARA_Nothalt 0;
BA_ "GenSigSwitchedByIgnition" SG_ 201 SM_ARA_Nothalt 0;
BA_ "GenSigSendType" SG_ 201 SM_ARA_Start 0;
BA_ "GenSigSwitchedByIgnition" SG_ 201 SM_ARA_Start 0;
BA_ "GenSigSendType" SG_ 201 SM_ARA_Status_Steuersignal 0;
BA_ "GenSigSwitchedByIgnition" SG_ 201 SM_ARA_Status_Steuersignal 0;
BA_ "GenSigSendType" SG_ 201 SM_ARA_Trajektorienmodus 0;
BA_ "GenSigSwitchedByIgnition" SG_ 201 SM_ARA_Trajektorienmodus 0;
BA_ "GenSigSendType" SG_ 201 SM_Fehlerstatus 0;
BA_ "GenSigSwitchedByIgnition" SG_ 201 SM_Fehlerstatus 0;
BA_ "GenSigSendType" SG_ 201 SM_Parken_01_Sendestatus 6;
BA_ "GenSigSwitchedByIgnition" SG_ 201 SM_Parken_01_Sendestatus 0;
BA_ "GenSigSendType" SG_ 201 SM_Parken_Alive 0;
BA_ "GenSigSwitchedByIgnition" SG_ 201 SM_Parken_Alive 0;
BA_ "GenSigSendType" SG_ 201 SM_Parken_AngefordertesRemoteSys 0;
BA_ "GenSigSwitchedByIgnition" SG_ 201 SM_Parken_AngefordertesRemoteSys 0;
BA_ "GenSigSendType" SG_ 201 SM_Parken_Kommando 0;
BA_ "GenSigSwitchedByIgnition" SG_ 201 SM_Parken_Kommando 0;
BA_ "GenSigSendType" SG_ 201 SM_Parken_Kommando_invers 0;
BA_ "GenSigStartValue" SG_ 201 SM_Parken_Kommando_invers 3;
BA_ "GenSigSwitchedByIgnition" SG_ 201 SM_Parken_Kommando_invers 0;
BA_ "GenSigSendType" SG_ 201 SM_Parken_Manoever 0;
BA_ "GenSigSwitchedByIgnition" SG_ 201 SM_Parken_Manoever 0;
BA_ "GenSigSendType" SG_ 201 SM_Parken_Motorstart_Anf 0;
BA_ "GenSigSwitchedByIgnition" SG_ 201 SM_Parken_Motorstart_Anf 0;
BA_ "GenSigSendType" SG_ 201 SM_Parken_Richtung 0;
BA_ "GenSigSwitchedByIgnition" SG_ 201 SM_Parken_Richtung 0;
BA_ "GenSigSendType" SG_ 201 SM_Parken_Seite 0;
BA_ "GenSigSwitchedByIgnition" SG_ 201 SM_Parken_Seite 0;
BA_ "GenSigSendType" SG_ 201 SM_Parken_Szenario 0;
BA_ "GenSigSwitchedByIgnition" SG_ 201 SM_Parken_Szenario 0;
BA_ "GenSigSendType" SG_ 201 SM_Parken_Touch_PosX 0;
BA_ "GenSigSwitchedByIgnition" SG_ 201 SM_Parken_Touch_PosX 0;
BA_ "GenSigSendType" SG_ 201 SM_Parken_Touch_PosY 0;
BA_ "GenSigStartValue" SG_ 201 SM_Parken_Touch_PosY 31;
BA_ "GenSigSwitchedByIgnition" SG_ 201 SM_Parken_Touch_PosY 0;
BA_ "GenSigSendType" SG_ 201 SM_Parken_Verbindungsstatus 0;
BA_ "GenSigSwitchedByIgnition" SG_ 201 SM_Parken_Verbindungsstatus 0;
BA_ "GenSigSendType" SG_ 2527679651 SM_Parken_blinken 0;
BA_ "GenSigSwitchedByIgnition" SG_ 2527679651 SM_Parken_blinken 0;
BA_ "GenSigSendType" SG_ 2527679651 SM_Parken_Hupe_Anf 0;
BA_ "GenSigSwitchedByIgnition" SG_ 2527679651 SM_Parken_Hupe_Anf 0;
BA_ "GenSigSendType" SG_ 2527679651 SM_Parken_Komfortschliessen_Anf 0;
BA_ "GenSigSwitchedByIgnition" SG_ 2527679651 SM_Parken_Komfortschliessen_Anf 0;
BA_ "GenSigSendType" SG_ 2527679651 SM_Parken_UGDO_Aktion 0;
BA_ "GenSigSwitchedByIgnition" SG_ 2527679651 SM_Parken_UGDO_Aktion 0;
BA_ "GenSigSendType" SG_ 2527679651 SM_Parken_UGDO_Anf 0;
BA_ "GenSigSwitchedByIgnition" SG_ 2527679651 SM_Parken_UGDO_Anf 0;
BA_ "GenSigSendType" SG_ 980 BH_Blinker_Fehler 4;
BA_ "GenSigSwitchedByIgnition" SG_ 980 BH_Blinker_Fehler 0;
BA_ "Fehlerwert" SG_ 980 BH_Blinker_Fehler 1;
BA_ "GenSigSendType" SG_ 980 BH_Blinker_li 4;
BA_ "GenSigSwitchedByIgnition" SG_ 980 BH_Blinker_li 0;
BA_ "GenSigSendType" SG_ 980 BH_Blinker_re 4;
BA_ "GenSigSwitchedByIgnition" SG_ 980 BH_Blinker_re 0;
BA_ "GenSigSendType" SG_ 980 BH_Fernlicht 3;
BA_ "GenSigSwitchedByIgnition" SG_ 980 BH_Fernlicht 0;
BA_ "GenSigSendType" SG_ 980 BH_Lichthupe 4;
BA_ "GenSigSwitchedByIgnition" SG_ 980 BH_Lichthupe 0;
BA_ "GenSigSendType" SG_ 980 FAS_Taster 3;
BA_ "GenSigSwitchedByIgnition" SG_ 980 FAS_Taster 0;
BA_ "GenSigSendType" SG_ 980 FAS_Taster_Fehler 3;
BA_ "GenSigSwitchedByIgnition" SG_ 980 FAS_Taster_Fehler 0;
BA_ "Fehlerwert" SG_ 980 FAS_Taster_Fehler 1;
BA_ "GenSigSendType" SG_ 980 LRH_aktiv 3;
BA_ "GenSigSwitchedByIgnition" SG_ 980 LRH_aktiv 0;
BA_ "GenSigSendType" SG_ 980 LRH_On_Off 3;
BA_ "GenSigSwitchedByIgnition" SG_ 980 LRH_On_Off 0;
BA_ "Fehlerwert" SG_ 980 LRH_On_Off 3;
BA_ "GenSigSendType" SG_ 980 LSS_Tastencode 3;
BA_ "GenSigSwitchedByIgnition" SG_ 980 LSS_Tastencode 0;
BA_ "GenSigSendType" SG_ 980 SMLS_01_BZ 0;
BA_ "GenSigFuncType" SG_ 980 SMLS_01_BZ 1;
BA_ "GenSigSwitchedByIgnition" SG_ 980 SMLS_01_BZ 0;
BA_ "GenSigSendType" SG_ 980 SMLS_01_CRC 0;
BA_ "GenSigFuncType" SG_ 980 SMLS_01_CRC 2;
BA_ "GenSigSwitchedByIgnition" SG_ 980 SMLS_01_CRC 0;
BA_ "GenSigSendType" SG_ 980 SMLS_Hupe 4;
BA_ "GenSigSwitchedByIgnition" SG_ 980 SMLS_Hupe 0;
BA_ "GenSigSendType" SG_ 980 SMLS_P_verriegelt 4;
BA_ "GenSigSwitchedByIgnition" SG_ 980 SMLS_P_verriegelt 0;
BA_ "Fehlerwert" SG_ 980 SMLS_P_verriegelt 3;
BA_ "GenSigSendType" SG_ 980 SMLS_P_verriegelt_plausibel 3;
BA_ "GenSigSwitchedByIgnition" SG_ 980 SMLS_P_verriegelt_plausibel 0;
BA_ "GenSigSendType" SG_ 980 SMLS_PTT 4;
BA_ "GenSigSendType" SG_ 980 WH_Frontwaschen 3;
BA_ "GenSigSwitchedByIgnition" SG_ 980 WH_Frontwaschen 0;
BA_ "GenSigSendType" SG_ 980 WH_Heckintervall 3;
BA_ "GenSigSwitchedByIgnition" SG_ 980 WH_Heckintervall 0;
BA_ "GenSigSendType" SG_ 980 WH_Heckwaschen 3;
BA_ "GenSigSwitchedByIgnition" SG_ 980 WH_Heckwaschen 0;
BA_ "GenSigSendType" SG_ 980 WH_Intervall 3;
BA_ "GenSigSwitchedByIgnition" SG_ 980 WH_Intervall 0;
BA_ "GenSigSendType" SG_ 980 WH_Intervallstufen 3;
BA_ "GenSigSwitchedByIgnition" SG_ 980 WH_Intervallstufen 0;
BA_ "Fehlerwert" SG_ 980 WH_Intervallstufen 15;
BA_ "GenSigMissingSourceValue" SG_ 980 WH_Intervallstufen 15;
BA_ "GenSigSendType" SG_ 980 WH_SRA 3;
BA_ "GenSigSwitchedByIgnition" SG_ 980 WH_SRA 0;
BA_ "GenSigSendType" SG_ 980 WH_Tipwischen 4;
BA_ "GenSigSwitchedByIgnition" SG_ 980 WH_Tipwischen 0;
BA_ "GenSigSendType" SG_ 980 WH_Tipwischen_lang 4;
BA_ "GenSigSwitchedByIgnition" SG_ 980 WH_Tipwischen_lang 0;
BA_ "GenSigSendType" SG_ 980 WH_Wischer_Fehler 3;
BA_ "GenSigSwitchedByIgnition" SG_ 980 WH_Wischer_Fehler 0;
BA_ "Fehlerwert" SG_ 980 WH_Wischer_Fehler 1;
BA_ "GenSigSendType" SG_ 980 WH_WischerStufe1 3;
BA_ "GenSigSwitchedByIgnition" SG_ 980 WH_WischerStufe1 0;
BA_ "GenSigSendType" SG_ 980 WH_WischerStufe2 3;
BA_ "GenSigSwitchedByIgnition" SG_ 980 WH_WischerStufe2 0;
BA_ "GenSigSendType" SG_ 2464161806 SOK_FoD_BCM1_Req_Challenge 3;
BA_ "GenSigSwitchedByIgnition" SG_ 2464161806 SOK_FoD_BCM1_Req_Challenge 0;
BA_ "GenSigSendType" SG_ 2464296974 SOK_FoD_BCM1_Resp_Challenge 3;
BA_ "GenSigSwitchedByIgnition" SG_ 2464296974 SOK_FoD_BCM1_Resp_Challenge 0;
BA_ "GenSigSendType" SG_ 2589283756 SOK_ungeschuetzte_Zeit 3;
BA_ "GenSigSwitchedByIgnition" SG_ 2589283756 SOK_ungeschuetzte_Zeit 0;
BA_ "GenSigSendType" SG_ 2464153614 SOK_Zeit_BCM_Challenge 3;
BA_ "GenSigSwitchedByIgnition" SG_ 2464153614 SOK_Zeit_BCM_Challenge 0;
BA_ "GenSigSendType" SG_ 2464284686 SOK_Zeit_BCM_Signatur 3;
BA_ "GenSigFuncType" SG_ 2464284686 SOK_Zeit_BCM_Signatur 15;
BA_ "GenSigSwitchedByIgnition" SG_ 2464284686 SOK_Zeit_BCM_Signatur 0;
BA_ "GenSigSendType" SG_ 2464288782 SOK_Zeit_BCM_Zeit 3;
BA_ "GenSigSwitchedByIgnition" SG_ 2464288782 SOK_Zeit_BCM_Zeit 0;
BA_ "GenSigSendType" SG_ 2464153786 SOK_Zeit_DDA_Challenge 3;
BA_ "GenSigSwitchedByIgnition" SG_ 2464153786 SOK_Zeit_DDA_Challenge 0;
BA_ "GenSigSendType" SG_ 2464284858 SOK_Zeit_DDA_Signatur 3;
BA_ "GenSigFuncType" SG_ 2464284858 SOK_Zeit_DDA_Signatur 15;
BA_ "GenSigSwitchedByIgnition" SG_ 2464284858 SOK_Zeit_DDA_Signatur 0;
BA_ "GenSigSendType" SG_ 2464288954 SOK_Zeit_DDA_Zeit 3;
BA_ "GenSigSwitchedByIgnition" SG_ 2464288954 SOK_Zeit_DDA_Zeit 0;
BA_ "GenSigSendType" SG_ 2464153675 SOK_Zeit_TSG_BT_Challenge 3;
BA_ "GenSigSwitchedByIgnition" SG_ 2464153675 SOK_Zeit_TSG_BT_Challenge 0;
BA_ "GenSigSendType" SG_ 2464284747 SOK_Zeit_TSG_BT_Signatur 3;
BA_ "GenSigFuncType" SG_ 2464284747 SOK_Zeit_TSG_BT_Signatur 15;
BA_ "GenSigSwitchedByIgnition" SG_ 2464284747 SOK_Zeit_TSG_BT_Signatur 0;
BA_ "GenSigSendType" SG_ 2464284747 SOK_Zeit_TSG_BT_Zeit 3;
BA_ "GenSigSwitchedByIgnition" SG_ 2464284747 SOK_Zeit_TSG_BT_Zeit 0;
BA_ "GenSigSendType" SG_ 2464153674 SOK_Zeit_TSG_FT_Challenge 3;
BA_ "GenSigSwitchedByIgnition" SG_ 2464153674 SOK_Zeit_TSG_FT_Challenge 0;
BA_ "GenSigSendType" SG_ 2464284746 SOK_Zeit_TSG_FT_Signatur 3;
BA_ "GenSigFuncType" SG_ 2464284746 SOK_Zeit_TSG_FT_Signatur 15;
BA_ "GenSigSwitchedByIgnition" SG_ 2464284746 SOK_Zeit_TSG_FT_Signatur 0;
BA_ "GenSigSendType" SG_ 2464284746 SOK_Zeit_TSG_FT_Zeit 3;
BA_ "GenSigSwitchedByIgnition" SG_ 2464284746 SOK_Zeit_TSG_FT_Zeit 0;
BA_ "GenSigSendType" SG_ 2464153663 SOK_Zeit_TSG_HBFS_Challenge 3;
BA_ "GenSigSwitchedByIgnition" SG_ 2464153663 SOK_Zeit_TSG_HBFS_Challenge 0;
BA_ "GenSigSendType" SG_ 2464284735 SOK_Zeit_TSG_HBFS_Signatur 3;
BA_ "GenSigFuncType" SG_ 2464284735 SOK_Zeit_TSG_HBFS_Signatur 15;
BA_ "GenSigSwitchedByIgnition" SG_ 2464284735 SOK_Zeit_TSG_HBFS_Signatur 0;
BA_ "GenSigSendType" SG_ 2464284735 SOK_Zeit_TSG_HBFS_Zeit 3;
BA_ "GenSigSwitchedByIgnition" SG_ 2464284735 SOK_Zeit_TSG_HBFS_Zeit 0;
BA_ "GenSigSendType" SG_ 2464153662 SOK_Zeit_TSG_HFS_Challenge 3;
BA_ "GenSigSwitchedByIgnition" SG_ 2464153662 SOK_Zeit_TSG_HFS_Challenge 0;
BA_ "GenSigSendType" SG_ 2464284734 SOK_Zeit_TSG_HFS_Signatur 3;
BA_ "GenSigFuncType" SG_ 2464284734 SOK_Zeit_TSG_HFS_Signatur 15;
BA_ "GenSigSwitchedByIgnition" SG_ 2464284734 SOK_Zeit_TSG_HFS_Signatur 0;
BA_ "GenSigSendType" SG_ 2464284734 SOK_Zeit_TSG_HFS_Zeit 3;
BA_ "GenSigSwitchedByIgnition" SG_ 2464284734 SOK_Zeit_TSG_HFS_Zeit 0;
BA_ "GenSigSendType" SG_ 1467 SoSe_SunInt_2D_Li 0;
BA_ "GenSigStartValue" SG_ 1467 SoSe_SunInt_2D_Li 254;
BA_ "GenSigSwitchedByIgnition" SG_ 1467 SoSe_SunInt_2D_Li 0;
BA_ "Fehlerwert" SG_ 1467 SoSe_SunInt_2D_Li 255;
BA_ "GenSigSendType" SG_ 1467 SoSe_SunInt_2D_Re 0;
BA_ "GenSigStartValue" SG_ 1467 SoSe_SunInt_2D_Re 254;
BA_ "GenSigSwitchedByIgnition" SG_ 1467 SoSe_SunInt_2D_Re 0;
BA_ "Fehlerwert" SG_ 1467 SoSe_SunInt_2D_Re 255;
BA_ "GenSigActiveRepetitions" SG_ 1710 SP_abklappen 5;
BA_ "GenSigSendType" SG_ 1710 SP_abklappen 4;
BA_ "GenSigSwitchedByIgnition" SG_ 1710 SP_abklappen 0;
BA_ "GenSigActiveRepetitions" SG_ 1710 SP_anklappen 5;
BA_ "GenSigSendType" SG_ 1710 SP_anklappen 4;
BA_ "GenSigSwitchedByIgnition" SG_ 1710 SP_anklappen 0;
BA_ "GenSigSendType" SG_ 1710 SP_ARA_Status 0;
BA_ "GenSigActiveRepetitions" SG_ 1710 SP_Auswahl_li 5;
BA_ "GenSigSendType" SG_ 1710 SP_Auswahl_li 4;
BA_ "GenSigSwitchedByIgnition" SG_ 1710 SP_Auswahl_li 0;
BA_ "GenSigActiveRepetitions" SG_ 1710 SP_Auswahl_re 5;
BA_ "GenSigSendType" SG_ 1710 SP_Auswahl_re 4;
BA_ "GenSigSwitchedByIgnition" SG_ 1710 SP_Auswahl_re 0;
BA_ "GenSigActiveRepetitions" SG_ 1710 SP_BT_links 5;
BA_ "GenSigSendType" SG_ 1710 SP_BT_links 4;
BA_ "GenSigSwitchedByIgnition" SG_ 1710 SP_BT_links 0;
BA_ "GenSigActiveRepetitions" SG_ 1710 SP_BT_oben 5;
BA_ "GenSigSendType" SG_ 1710 SP_BT_oben 4;
BA_ "GenSigSwitchedByIgnition" SG_ 1710 SP_BT_oben 0;
BA_ "GenSigActiveRepetitions" SG_ 1710 SP_BT_rechts 5;
BA_ "GenSigSendType" SG_ 1710 SP_BT_rechts 4;
BA_ "GenSigSwitchedByIgnition" SG_ 1710 SP_BT_rechts 0;
BA_ "GenSigActiveRepetitions" SG_ 1710 SP_BT_unten 5;
BA_ "GenSigSendType" SG_ 1710 SP_BT_unten 4;
BA_ "GenSigSwitchedByIgnition" SG_ 1710 SP_BT_unten 0;
BA_ "GenSigActiveRepetitions" SG_ 1710 SP_FT_links 5;
BA_ "GenSigSendType" SG_ 1710 SP_FT_links 4;
BA_ "GenSigSwitchedByIgnition" SG_ 1710 SP_FT_links 0;
BA_ "GenSigActiveRepetitions" SG_ 1710 SP_FT_oben 5;
BA_ "GenSigSendType" SG_ 1710 SP_FT_oben 4;
BA_ "GenSigSwitchedByIgnition" SG_ 1710 SP_FT_oben 0;
BA_ "GenSigActiveRepetitions" SG_ 1710 SP_FT_rechts 5;
BA_ "GenSigSendType" SG_ 1710 SP_FT_rechts 4;
BA_ "GenSigSwitchedByIgnition" SG_ 1710 SP_FT_rechts 0;
BA_ "GenSigActiveRepetitions" SG_ 1710 SP_FT_unten 5;
BA_ "GenSigSendType" SG_ 1710 SP_FT_unten 4;
BA_ "GenSigSwitchedByIgnition" SG_ 1710 SP_FT_unten 0;
BA_ "GenSigSendType" SG_ 1710 SP_Hzg_Taster 3;
BA_ "GenSigSwitchedByIgnition" SG_ 1710 SP_Hzg_Taster 0;
BA_ "GenSigActiveRepetitions" SG_ 1710 SP_normieren 5;
BA_ "GenSigSendType" SG_ 1710 SP_normieren 4;
BA_ "GenSigSwitchedByIgnition" SG_ 1710 SP_normieren 0;
BA_ "GenSigActiveRepetitions" SG_ 1710 SP_S_Klappen 5;
BA_ "GenSigSendType" SG_ 1710 SP_S_Klappen 4;
BA_ "GenSigSwitchedByIgnition" SG_ 1710 SP_S_Klappen 0;
BA_ "GenSigActiveRepetitions" SG_ 1710 SP_S_links 5;
BA_ "GenSigSendType" SG_ 1710 SP_S_links 4;
BA_ "GenSigSwitchedByIgnition" SG_ 1710 SP_S_links 0;
BA_ "GenSigActiveRepetitions" SG_ 1710 SP_S_oben 5;
BA_ "GenSigSendType" SG_ 1710 SP_S_oben 4;
BA_ "GenSigSwitchedByIgnition" SG_ 1710 SP_S_oben 0;
BA_ "GenSigActiveRepetitions" SG_ 1710 SP_S_rechts 5;
BA_ "GenSigSendType" SG_ 1710 SP_S_rechts 4;
BA_ "GenSigSwitchedByIgnition" SG_ 1710 SP_S_rechts 0;
BA_ "GenSigActiveRepetitions" SG_ 1710 SP_S_unten 5;
BA_ "GenSigSendType" SG_ 1710 SP_S_unten 4;
BA_ "GenSigSwitchedByIgnition" SG_ 1710 SP_S_unten 0;
BA_ "GenSigSendType" SG_ 1710 SP_Spg_Verstellschalter_Fehler 0;
BA_ "Fehlerwert" SG_ 1710 SP_Spg_Verstellschalter_Fehler 1;
BA_ "GenSigSendType" SG_ 1710 SP_Verstellschalter_Fehler 0;
BA_ "Fehlerwert" SG_ 1710 SP_Verstellschalter_Fehler 1;
BA_ "GenSigSendType" SG_ 2463978603 KFT_FH_BT_hoch 9;
BA_ "GenSigSwitchedByIgnition" SG_ 2463978603 KFT_FH_BT_hoch 0;
BA_ "GenSigSendType" SG_ 2463978603 KFT_FH_BT_tief 9;
BA_ "GenSigSwitchedByIgnition" SG_ 2463978603 KFT_FH_BT_tief 0;
BA_ "GenSigSendType" SG_ 2463978603 KFT_FH_Freigabe 3;
BA_ "GenSigSwitchedByIgnition" SG_ 2463978603 KFT_FH_Freigabe 0;
BA_ "GenSigSendType" SG_ 2463978603 KFT_FH_FT_hoch 9;
BA_ "GenSigSwitchedByIgnition" SG_ 2463978603 KFT_FH_FT_hoch 0;
BA_ "GenSigSendType" SG_ 2463978603 KFT_FH_FT_tief 9;
BA_ "GenSigSwitchedByIgnition" SG_ 2463978603 KFT_FH_FT_tief 0;
BA_ "GenSigSendType" SG_ 2463978603 KFT_FH_HBFS_hoch 9;
BA_ "GenSigSwitchedByIgnition" SG_ 2463978603 KFT_FH_HBFS_hoch 0;
BA_ "GenSigSendType" SG_ 2463978603 KFT_FH_HBFS_tief 9;
BA_ "GenSigSwitchedByIgnition" SG_ 2463978603 KFT_FH_HBFS_tief 0;
BA_ "GenSigSendType" SG_ 2463978603 KFT_FH_HFS_hoch 9;
BA_ "GenSigSwitchedByIgnition" SG_ 2463978603 KFT_FH_HFS_hoch 0;
BA_ "GenSigSendType" SG_ 2463978603 KFT_FH_HFS_tief 9;
BA_ "GenSigSwitchedByIgnition" SG_ 2463978603 KFT_FH_HFS_tief 0;
BA_ "GenSigSendType" SG_ 2463978603 KFT_Komfortfkt_Freigabe 3;
BA_ "GenSigSwitchedByIgnition" SG_ 2463978603 KFT_Komfortfkt_Freigabe 0;
BA_ "GenSigSendType" SG_ 2463978603 KFT_Rollo_auf 3;
BA_ "GenSigSwitchedByIgnition" SG_ 2463978603 KFT_Rollo_auf 0;
BA_ "GenSigSendType" SG_ 2463978603 KFT_Rollo_zu 3;
BA_ "GenSigSwitchedByIgnition" SG_ 2463978603 KFT_Rollo_zu 0;
BA_ "GenSigSendType" SG_ 2463978603 KFT_SAD_auf 3;
BA_ "GenSigSwitchedByIgnition" SG_ 2463978603 KFT_SAD_auf 0;
BA_ "GenSigSendType" SG_ 2463978603 KFT_SAD_zu 3;
BA_ "GenSigSwitchedByIgnition" SG_ 2463978603 KFT_SAD_zu 0;
BA_ "GenSigSendType" SG_ 2463978603 KFT_Verdeck_auf 9;
BA_ "GenSigSwitchedByIgnition" SG_ 2463978603 KFT_Verdeck_auf 0;
BA_ "GenSigSendType" SG_ 2463978603 KFT_Verdeck_Freigabe 4;
BA_ "GenSigSwitchedByIgnition" SG_ 2463978603 KFT_Verdeck_Freigabe 0;
BA_ "GenSigSendType" SG_ 2463978603 KFT_Verdeck_zu 9;
BA_ "GenSigSwitchedByIgnition" SG_ 2463978603 KFT_Verdeck_zu 0;
BA_ "GenSigSendType" SG_ 2463978603 Privacy_SAD_Rollo1_ansteuern 4;
BA_ "GenSigSendType" SG_ 2463978603 Privacy_SAD_Rollo2_ansteuern 4;
BA_ "GenSigSendType" SG_ 2463978603 SOK_SSAM_01_Signatur 0;
BA_ "GenSigFuncType" SG_ 2463978603 SOK_SSAM_01_Signatur 15;
BA_ "GenSigSendType" SG_ 2463978603 SSA_BFT_ASP_Klappung_ansteuern 4;
BA_ "GenSigSwitchedByIgnition" SG_ 2463978603 SSA_BFT_ASP_Klappung_ansteuern 0;
BA_ "GenSigSendType" SG_ 2463978603 SSA_BFT_ASP_SpglGlas_ansteuern 4;
BA_ "GenSigSwitchedByIgnition" SG_ 2463978603 SSA_BFT_ASP_SpglGlas_ansteuern 0;
BA_ "GenSigSendType" SG_ 2463978603 SSA_BFT_ASW_ansteuern 4;
BA_ "GenSigSwitchedByIgnition" SG_ 2463978603 SSA_BFT_ASW_ansteuern 0;
BA_ "GenSigSendType" SG_ 2463978603 SSA_BFT_el_Tuerantrieb_Zielwert 0;
BA_ "GenSigSwitchedByIgnition" SG_ 2463978603 SSA_BFT_el_Tuerantrieb_Zielwert 0;
BA_ "GenSigSendType" SG_ 2463978603 SSA_BFT_FH_ansteuern 4;
BA_ "GenSigStartValue" SG_ 2463978603 SSA_BFT_FH_ansteuern 125;
BA_ "GenSigSwitchedByIgnition" SG_ 2463978603 SSA_BFT_FH_ansteuern 0;
BA_ "GenSigSendType" SG_ 2463978603 SSA_BFT_FH_Pos_anfahren 4;
BA_ "GenSigSwitchedByIgnition" SG_ 2463978603 SSA_BFT_FH_Pos_anfahren 0;
BA_ "Fehlerwert" SG_ 2463978603 SSA_BFT_FH_Pos_anfahren 255;
BA_ "GenSigSendType" SG_ 2463978603 SSA_FT_ASP_SpglGlas_ansteuern 4;
BA_ "GenSigSwitchedByIgnition" SG_ 2463978603 SSA_FT_ASP_SpglGlas_ansteuern 0;
BA_ "GenSigSendType" SG_ 2463978603 SSA_FT_ASW_ansteuern 4;
BA_ "GenSigSwitchedByIgnition" SG_ 2463978603 SSA_FT_ASW_ansteuern 0;
BA_ "GenSigSendType" SG_ 2463978603 SSA_FT_el_Tuerantrieb_ansteuern 4;
BA_ "GenSigSwitchedByIgnition" SG_ 2463978603 SSA_FT_el_Tuerantrieb_ansteuern 0;
BA_ "GenSigSendType" SG_ 2463978603 SSA_FT_el_Tuerantrieb_Zielwert 0;
BA_ "GenSigSwitchedByIgnition" SG_ 2463978603 SSA_FT_el_Tuerantrieb_Zielwert 0;
BA_ "GenSigSendType" SG_ 2463978603 SSA_FT_FH_ansteuern 4;
BA_ "GenSigStartValue" SG_ 2463978603 SSA_FT_FH_ansteuern 125;
BA_ "GenSigSwitchedByIgnition" SG_ 2463978603 SSA_FT_FH_ansteuern 0;
BA_ "GenSigSendType" SG_ 2463978603 SSA_FT_ZV_Ansteuern 4;
BA_ "GenSigSwitchedByIgnition" SG_ 2463978603 SSA_FT_ZV_Ansteuern 0;
BA_ "Fehlerwert" SG_ 2463978603 SSA_FT_ZV_Ansteuern 255;
BA_ "GenSigSendType" SG_ 2463978603 SSA_FT_ZZH_ansteuern 4;
BA_ "GenSigSwitchedByIgnition" SG_ 2463978603 SSA_FT_ZZH_ansteuern 0;
BA_ "GenSigSendType" SG_ 2463978603 SSA_HBFT_el_Tuerantrieb_Zielwert 0;
BA_ "GenSigSwitchedByIgnition" SG_ 2463978603 SSA_HBFT_el_Tuerantrieb_Zielwert 0;
BA_ "GenSigSendType" SG_ 2463978603 SSA_HBFT_FH_ansteuern 4;
BA_ "GenSigStartValue" SG_ 2463978603 SSA_HBFT_FH_ansteuern 125;
BA_ "GenSigSwitchedByIgnition" SG_ 2463978603 SSA_HBFT_FH_ansteuern 0;
BA_ "GenSigSendType" SG_ 2463978603 SSA_HBFT_SSR_ansteuern 4;
BA_ "GenSigSendType" SG_ 2463978603 SSA_HD_ansteuern 4;
BA_ "GenSigSwitchedByIgnition" SG_ 2463978603 SSA_HD_ansteuern 0;
BA_ "GenSigSendType" SG_ 2463978603 SSA_HD_Beeper_ansteuern 4;
BA_ "GenSigSwitchedByIgnition" SG_ 2463978603 SSA_HD_Beeper_ansteuern 0;
BA_ "GenSigSendType" SG_ 2463978603 SSA_Heckrollo_ansteuern 4;
BA_ "GenSigSwitchedByIgnition" SG_ 2463978603 SSA_Heckrollo_ansteuern 0;
BA_ "GenSigSendType" SG_ 2463978603 SSA_Heckrollo_PrivacySAD_Rollo1 4;
BA_ "GenSigSendType" SG_ 2463978603 SSA_Heckrollo_PrivacySAD_Rollo2 4;
BA_ "GenSigSendType" SG_ 2463978603 SSA_HFT_el_Tuerantrieb_Zielwert 0;
BA_ "GenSigSwitchedByIgnition" SG_ 2463978603 SSA_HFT_el_Tuerantrieb_Zielwert 0;
BA_ "GenSigSendType" SG_ 2463978603 SSA_HFT_FH_ansteuern 4;
BA_ "GenSigStartValue" SG_ 2463978603 SSA_HFT_FH_ansteuern 125;
BA_ "GenSigSwitchedByIgnition" SG_ 2463978603 SSA_HFT_FH_ansteuern 0;
BA_ "GenSigSendType" SG_ 2463978603 SSA_LRA_ansteuern 4;
BA_ "GenSigSwitchedByIgnition" SG_ 2463978603 SSA_LRA_ansteuern 0;
BA_ "GenSigSendType" SG_ 2463978603 SSA_SAD_Deckel1_ansteuern 4;
BA_ "GenSigStartValue" SG_ 2463978603 SSA_SAD_Deckel1_ansteuern 125;
BA_ "GenSigSwitchedByIgnition" SG_ 2463978603 SSA_SAD_Deckel1_ansteuern 0;
BA_ "GenSigSendType" SG_ 2463978603 SSA_SAD_Rollo1_ansteuern 4;
BA_ "GenSigStartValue" SG_ 2463978603 SSA_SAD_Rollo1_ansteuern 125;
BA_ "GenSigSwitchedByIgnition" SG_ 2463978603 SSA_SAD_Rollo1_ansteuern 0;
BA_ "GenSigSendType" SG_ 2463978603 SSA_SD_Versorgung_ansteuern 4;
BA_ "GenSigSwitchedByIgnition" SG_ 2463978603 SSA_SD_Versorgung_ansteuern 0;
BA_ "GenSigSendType" SG_ 2463978603 SSAM_01_BZ 0;
BA_ "GenSigFuncType" SG_ 2463978603 SSAM_01_BZ 1;
BA_ "GenSigSwitchedByIgnition" SG_ 2463978603 SSAM_01_BZ 0;
BA_ "GenSigSendType" SG_ 2463978603 SSAM_01_CRC 0;
BA_ "GenSigFuncType" SG_ 2463978603 SSAM_01_CRC 2;
BA_ "GenSigSwitchedByIgnition" SG_ 2463978603 SSAM_01_CRC 0;
BA_ "GenSigSendType" SG_ 1313 STH_EKP_Anst 0;
BA_ "GenSigSwitchedByIgnition" SG_ 1313 STH_EKP_Anst 0;
BA_ "GenSigSendType" SG_ 1313 STH_Fehler_ElWaPu 0;
BA_ "GenSigSwitchedByIgnition" SG_ 1313 STH_Fehler_ElWaPu 0;
BA_ "Fehlerwert" SG_ 1313 STH_Fehler_ElWaPu 1;
BA_ "GenSigSendType" SG_ 1313 STH_Fehlerstatus 0;
BA_ "GenSigSwitchedByIgnition" SG_ 1313 STH_Fehlerstatus 0;
BA_ "GenSigSendType" SG_ 1313 STH_Funk_aus 0;
BA_ "GenSigSwitchedByIgnition" SG_ 1313 STH_Funk_aus 0;
BA_ "GenSigSendType" SG_ 1313 STH_Funk_ein 0;
BA_ "GenSigSwitchedByIgnition" SG_ 1313 STH_Funk_ein 0;
BA_ "GenSigSendType" SG_ 1313 STH_Geblaese 0;
BA_ "GenSigSwitchedByIgnition" SG_ 1313 STH_Geblaese 0;
BA_ "GenSigSendType" SG_ 1313 STH_Heizleistung 0;
BA_ "GenSigSwitchedByIgnition" SG_ 1313 STH_Heizleistung 0;
BA_ "GenSigSendType" SG_ 1313 STH_KL_HUP 0;
BA_ "GenSigSwitchedByIgnition" SG_ 1313 STH_KL_HUP 0;
BA_ "GenSigSendType" SG_ 1313 STH_KVS 0;
BA_ "GenSigSwitchedByIgnition" SG_ 1313 STH_KVS 0;
BA_ "GenSigSendType" SG_ 1313 STH_KVS_Ueberlauf 0;
BA_ "GenSigSwitchedByIgnition" SG_ 1313 STH_KVS_Ueberlauf 0;
BA_ "GenSigSendType" SG_ 1313 STH_LED 0;
BA_ "GenSigSwitchedByIgnition" SG_ 1313 STH_LED 0;
BA_ "GenSigSendType" SG_ 1313 STH_Motorvorwaermung 0;
BA_ "GenSigSwitchedByIgnition" SG_ 1313 STH_Motorvorwaermung 0;
BA_ "GenSigSendType" SG_ 1313 STH_Pumpe_ein 0;
BA_ "GenSigSwitchedByIgnition" SG_ 1313 STH_Pumpe_ein 0;
BA_ "GenSigSendType" SG_ 1313 STH_Pumpen_Anf_extern 0;
BA_ "GenSigSwitchedByIgnition" SG_ 1313 STH_Pumpen_Anf_extern 0;
BA_ "GenSigSendType" SG_ 1313 STH_Servicemode 0;
BA_ "GenSigSwitchedByIgnition" SG_ 1313 STH_Servicemode 0;
BA_ "GenSigSendType" SG_ 1313 STH_SH_ZH 0;
BA_ "GenSigSwitchedByIgnition" SG_ 1313 STH_SH_ZH 0;
BA_ "GenSigSendType" SG_ 1313 STH_Start_folgt 0;
BA_ "GenSigSwitchedByIgnition" SG_ 1313 STH_Start_folgt 0;
BA_ "GenSigSendType" SG_ 1313 STH_Texte 0;
BA_ "GenSigSwitchedByIgnition" SG_ 1313 STH_Texte 0;
BA_ "GenSigSendType" SG_ 1313 STH_Ventil_Status 0;
BA_ "GenSigSwitchedByIgnition" SG_ 1313 STH_Ventil_Status 0;
BA_ "GenSigSendType" SG_ 1313 STH_Ventiloeffnungszeit 0;
BA_ "GenSigSwitchedByIgnition" SG_ 1313 STH_Ventiloeffnungszeit 0;
BA_ "GenSigSendType" SG_ 1313 STH_Waermeeintrag 0;
BA_ "GenSigSwitchedByIgnition" SG_ 1313 STH_Waermeeintrag 0;
BA_ "GenSigSendType" SG_ 1313 STH_war_aktiv 0;
BA_ "GenSigSwitchedByIgnition" SG_ 1313 STH_war_aktiv 0;
BA_ "GenSigSendType" SG_ 1313 STH_Wassertemp 0;
BA_ "GenSigStartValue" SG_ 1313 STH_Wassertemp 254;
BA_ "GenSigSwitchedByIgnition" SG_ 1313 STH_Wassertemp 0;
BA_ "Fehlerwert" SG_ 1313 STH_Wassertemp 255;
BA_ "GenSigSendType" SG_ 1313 STH_Zusatzheizung 0;
BA_ "GenSigSwitchedByIgnition" SG_ 1313 STH_Zusatzheizung 0;
BA_ "GenSigSendType" SG_ 832 STSG_HBFS_Bew_auf 3;
BA_ "GenSigSwitchedByIgnition" SG_ 832 STSG_HBFS_Bew_auf 0;
BA_ "GenSigSendType" SG_ 832 STSG_HBFS_Bew_zu 3;
BA_ "GenSigSwitchedByIgnition" SG_ 832 STSG_HBFS_Bew_zu 0;
BA_ "GenSigSendType" SG_ 832 STSG_HBFS_BTF 3;
BA_ "GenSigSwitchedByIgnition" SG_ 832 STSG_HBFS_BTF 0;
BA_ "GenSigSendType" SG_ 832 STSG_HBFS_Einklemm_aktiv 3;
BA_ "GenSigSwitchedByIgnition" SG_ 832 STSG_HBFS_Einklemm_aktiv 0;
BA_ "GenSigSendType" SG_ 832 STSG_HBFS_Einklemm_defekt 3;
BA_ "GenSigSwitchedByIgnition" SG_ 832 STSG_HBFS_Einklemm_defekt 0;
BA_ "GenSigSendType" SG_ 832 STSG_HBFS_entriegeln_anfordern 3;
BA_ "GenSigSwitchedByIgnition" SG_ 832 STSG_HBFS_entriegeln_anfordern 0;
BA_ "GenSigSendType" SG_ 832 STSG_HBFS_EOE_aktiv 3;
BA_ "GenSigSwitchedByIgnition" SG_ 832 STSG_HBFS_EOE_aktiv 0;
BA_ "GenSigSendType" SG_ 832 STSG_HBFS_FFB_Taste_Schiebtuer 3;
BA_ "GenSigSwitchedByIgnition" SG_ 832 STSG_HBFS_FFB_Taste_Schiebtuer 0;
BA_ "GenSigSendType" SG_ 832 STSG_HBFS_Historie_Reject_adr 0;
BA_ "GenSigSwitchedByIgnition" SG_ 832 STSG_HBFS_Historie_Reject_adr 0;
BA_ "GenSigSendType" SG_ 832 STSG_HBFS_Historie_Reject_data 0;
BA_ "GenSigSwitchedByIgnition" SG_ 832 STSG_HBFS_Historie_Reject_data 0;
BA_ "GenSigSendType" SG_ 832 STSG_HBFS_I_Motor 0;
BA_ "GenSigSwitchedByIgnition" SG_ 832 STSG_HBFS_I_Motor 0;
BA_ "GenSigSendType" SG_ 832 STSG_HBFS_ST_deaktivieren 3;
BA_ "GenSigSwitchedByIgnition" SG_ 832 STSG_HBFS_ST_deaktivieren 0;
BA_ "GenSigSendType" SG_ 832 STSG_HBFS_Status_Feststeller 3;
BA_ "GenSigSendType" SG_ 832 STSG_HBFS_TAG_betaetigt 3;
BA_ "GenSigSwitchedByIgnition" SG_ 832 STSG_HBFS_TAG_betaetigt 0;
BA_ "GenSigSendType" SG_ 832 STSG_HBFS_TAT 3;
BA_ "GenSigSwitchedByIgnition" SG_ 832 STSG_HBFS_TAT 0;
BA_ "GenSigSendType" SG_ 832 STSG_HBFS_Thermo_aktiv 3;
BA_ "GenSigSwitchedByIgnition" SG_ 832 STSG_HBFS_Thermo_aktiv 0;
BA_ "GenSigSendType" SG_ 832 STSG_HBFS_TIG_bet_oeffnen 3;
BA_ "GenSigSwitchedByIgnition" SG_ 832 STSG_HBFS_TIG_bet_oeffnen 0;
BA_ "GenSigSendType" SG_ 832 STSG_HBFS_TIG_bet_schliessen 3;
BA_ "GenSigSwitchedByIgnition" SG_ 832 STSG_HBFS_TIG_bet_schliessen 0;
BA_ "GenSigSendType" SG_ 832 STSG_HBFS_Tuer_Position 0;
BA_ "GenSigSwitchedByIgnition" SG_ 832 STSG_HBFS_Tuer_Position 0;
BA_ "GenSigSendType" SG_ 832 STSG_HBFS_Tuer_Sperrklinke 3;
BA_ "GenSigSwitchedByIgnition" SG_ 832 STSG_HBFS_Tuer_Sperrklinke 0;
BA_ "GenSigSendType" SG_ 832 STSG_HBFS_Tuer_Vorraste 3;
BA_ "GenSigSwitchedByIgnition" SG_ 832 STSG_HBFS_Tuer_Vorraste 0;
BA_ "GenSigSendType" SG_ 832 STSG_HBFS_UB 0;
BA_ "GenSigSwitchedByIgnition" SG_ 832 STSG_HBFS_UB 0;
BA_ "GenSigSendType" SG_ 832 STSG_HBFS_UEKB_aktiv 3;
BA_ "GenSigSwitchedByIgnition" SG_ 832 STSG_HBFS_UEKB_aktiv 0;
BA_ "GenSigSendType" SG_ 832 STSG_HBFS_ZZH_Freigabe 3;
BA_ "GenSigSwitchedByIgnition" SG_ 832 STSG_HBFS_ZZH_Freigabe 0;
BA_ "GenSigSendType" SG_ 832 STSG_HBFS_ZZH_Initialisierung 3;
BA_ "GenSigSwitchedByIgnition" SG_ 832 STSG_HBFS_ZZH_Initialisierung 0;
BA_ "GenSigSendType" SG_ 832 STSG_HBFS_ZZH_Status_auf 3;
BA_ "GenSigSwitchedByIgnition" SG_ 832 STSG_HBFS_ZZH_Status_auf 0;
BA_ "GenSigSendType" SG_ 832 STSG_HBFS_ZZH_Status_zu 3;
BA_ "GenSigSwitchedByIgnition" SG_ 832 STSG_HBFS_ZZH_Status_zu 0;
BA_REL_ "GenSigTimeoutTime" BU_SG_REL_ BCM SG_ 1031 PLA_04_CRC 1000;
BA_REL_ "GenSigTimeoutTime" BU_SG_REL_ BCM SG_ 1031 PLA_04_BZ 1000;
BA_REL_ "GenSigTimeoutTime" BU_SG_REL_ BCM SG_ 1031 RPA_Anf_Sonder_Funktion_Status 1000;
BA_REL_ "GenSigTimeoutTime" BU_SG_REL_ BCM SG_ 1031 RPA_Anf_Sonder_Klemme_15 1000;
BA_REL_ "GenSigTimeoutTime" BU_SG_REL_ BCM SG_ 1031 RPA_Anf_WFS_Freigabe 1000;
BA_REL_ "GenSigTimeoutTime" BU_SG_REL_ BCM SG_ 319 PreCrash_Blinken 2000;
BA_REL_ "GenSigTimeoutTime" BU_SG_REL_ BCM SG_ 319 PreCrash_Tueren_Verriegeln 2000;
BA_REL_ "GenSigTimeoutTime" BU_SG_REL_ BCM SG_ 319 PreCrash_FS_Pneumatik_ansteuern 2000;
BA_REL_ "GenSigTimeoutTime" BU_SG_REL_ BCM SG_ 319 PreCrash_BFS_Pneumatik_ansteuern 2000;
BA_REL_ "GenSigTimeoutTime" BU_SG_REL_ BCM SG_ 695 RCTA_Kritikalitaetslevel_rechts 500;
BA_REL_ "GenSigTimeoutTime" BU_SG_REL_ BCM SG_ 695 RCTA_Kritikalitaetslevel_links 500;
BA_REL_ "GenSigTimeoutTime" BU_SG_REL_ BCM SG_ 1711 RV_Reinigung_Anf 5000;
BA_REL_ "GenSigTimeoutTime" BU_SG_REL_ BCM SG_ 2264486920 RHP_01_CRC 2000;
BA_REL_ "GenSigTimeoutTime" BU_SG_REL_ BCM SG_ 2264486920 RHP_01_BZ 2000;
BA_REL_ "GenSigTimeoutTime" BU_SG_REL_ BCM SG_ 2264486920 RHP_Fahrzeughupe_Anf 2000;
BA_REL_ "GenSigTimeoutTime" BU_SG_REL_ BCM SG_ 2264486920 RHP_Warnblinken 2000;
BA_REL_ "GenSigTimeoutTime" BU_SG_REL_ BCM SG_ 2264486920 RHP_Innenraumlicht_Anf 2000;
BA_REL_ "GenSigTimeoutTime" BU_SG_REL_ BCM SG_ 2264486920 RHP_Spurwechsel_Ready 2000;
BA_REL_ "GenSigTimeoutTime" BU_SG_REL_ BCM SG_ 1504 MD1_Position 5000;
BA_REL_ "GenSigTimeoutTime" BU_SG_REL_ BCM SG_ 1504 MD1_Lage 5000;
BA_REL_ "GenSigTimeoutTime" BU_SG_REL_ BCM SG_ 1504 MD3_Position 5000;
BA_REL_ "GenSigTimeoutTime" BU_SG_REL_ BCM SG_ 1504 MD3_Lage 5000;
BA_REL_ "GenSigTimeoutTime" BU_SG_REL_ BCM SG_ 1504 MRollo_Position 5000;
BA_REL_ "GenSigTimeoutTime" BU_SG_REL_ BCM SG_ 1504 MRollo_Lage 5000;
BA_REL_ "GenSigTimeoutTime" BU_SG_REL_ BCM SG_ 1504 SAD_normiert 5000;
BA_REL_ "GenSigTimeoutTime" BU_SG_REL_ BCM SG_ 1504 SAD_Thermoschutz 5000;
BA_REL_ "GenSigTimeoutTime" BU_SG_REL_ BCM SG_ 1504 SAD_UEKB_aktiv 5000;
BA_REL_ "GenSigTimeoutTime" BU_SG_REL_ BCM SG_ 1504 Rollo_normiert 5000;
BA_REL_ "GenSigTimeoutTime" BU_SG_REL_ BCM SG_ 1504 Rollo_Thermoschutz 5000;
BA_REL_ "GenSigTimeoutTime" BU_SG_REL_ BCM SG_ 1504 Rollo_UEKB_aktiv 5000;
BA_REL_ "GenSigTimeoutTime" BU_SG_REL_ BCM SG_ 2463978815 SBM_01_CRC 1000;
BA_REL_ "GenSigTimeoutTime" BU_SG_REL_ BCM SG_ 2463978815 SBM_01_BZ 1000;
BA_REL_ "GenSigTimeoutTime" BU_SG_REL_ BCM SG_ 2463978815 SBM_FahrerAkt_Schaltbetaetigung 1000;
BA_REL_ "GenSigTimeoutTime" BU_SG_REL_ BCM SG_ 2463978815 SBM_FahrerAkt_P_Taste 1000;
BA_REL_ "GenSigTimeoutTime" BU_SG_REL_ BCM SG_ 1522 KBI_Phototransistor 2000;
BA_REL_ "GenSigTimeoutTime" BU_SG_REL_ BCM SG_ 1167 SK1_MUX 1000;
BA_REL_ "GenSigTimeoutTime" BU_SG_REL_ BCM SG_ 1167 SK1_Key_Data_1 1000;
BA_REL_ "GenSigTimeoutTime" BU_SG_REL_ BCM SG_ 1167 SK1_Key_Data_2 1000;
BA_REL_ "GenSigTimeoutTime" BU_SG_REL_ BCM SG_ 1167 SK1_Key_Data_3 1000;
BA_REL_ "GenSigTimeoutTime" BU_SG_REL_ BCM SG_ 1167 SK1_Key_Data_4 1000;
BA_REL_ "GenSigTimeoutTime" BU_SG_REL_ BCM SG_ 1167 SK1_Key_Data_5 1000;
BA_REL_ "GenSigTimeoutTime" BU_SG_REL_ BCM SG_ 1167 SK1_Key_Data_6 1000;
BA_REL_ "GenSigTimeoutTime" BU_SG_REL_ BCM SG_ 1167 SK1_Key_Data_7 1000;
BA_REL_ "GenSigTimeoutTime" BU_SG_REL_ BCM SG_ 1167 SK1_Key_Data_8 1000;
BA_REL_ "GenSigTimeoutTime" BU_SG_REL_ BCM SG_ 1167 SK1_Key_Data_9 1000;
BA_REL_ "GenSigTimeoutTime" BU_SG_REL_ BCM SG_ 980 SMLS_01_CRC 5000;
BA_REL_ "GenSigTimeoutTime" BU_SG_REL_ BCM SG_ 980 SMLS_01_BZ 5000;
BA_REL_ "GenSigTimeoutTime" BU_SG_REL_ BCM SG_ 980 BH_Blinker_li 5000;
BA_REL_ "GenSigTimeoutTime" BU_SG_REL_ BCM SG_ 980 BH_Blinker_re 5000;
BA_REL_ "GenSigTimeoutTime" BU_SG_REL_ BCM SG_ 980 BH_Lichthupe 5000;
BA_REL_ "GenSigTimeoutTime" BU_SG_REL_ BCM SG_ 980 BH_Fernlicht 5000;
BA_REL_ "GenSigTimeoutTime" BU_SG_REL_ BCM SG_ 980 WH_Tipwischen 5000;
BA_REL_ "GenSigTimeoutTime" BU_SG_REL_ BCM SG_ 980 WH_Intervall 5000;
BA_REL_ "GenSigTimeoutTime" BU_SG_REL_ BCM SG_ 980 WH_WischerStufe1 5000;
BA_REL_ "GenSigTimeoutTime" BU_SG_REL_ BCM SG_ 980 WH_WischerStufe2 5000;
BA_REL_ "GenSigTimeoutTime" BU_SG_REL_ BCM SG_ 980 WH_Frontwaschen 5000;
BA_REL_ "GenSigTimeoutTime" BU_SG_REL_ BCM SG_ 980 WH_Heckintervall 5000;
BA_REL_ "GenSigTimeoutTime" BU_SG_REL_ BCM SG_ 980 WH_Heckwaschen 5000;
BA_REL_ "GenSigTimeoutTime" BU_SG_REL_ BCM SG_ 980 WH_Intervallstufen 5000;
BA_REL_ "GenSigTimeoutTime" BU_SG_REL_ BCM SG_ 980 FAS_Taster 5000;
BA_REL_ "GenSigTimeoutTime" BU_SG_REL_ BCM SG_ 980 FAS_Taster_Fehler 5000;
BA_REL_ "GenSigTimeoutTime" BU_SG_REL_ BCM SG_ 980 SMLS_Hupe 5000;
BA_REL_ "GenSigTimeoutTime" BU_SG_REL_ BCM SG_ 980 LRH_On_Off 5000;
BA_REL_ "GenSigTimeoutTime" BU_SG_REL_ BCM SG_ 980 LSS_Tastencode 5000;
BA_REL_ "GenSigTimeoutTime" BU_SG_REL_ BCM SG_ 980 LRH_aktiv 5000;
BA_REL_ "GenSigTimeoutTime" BU_SG_REL_ BCM SG_ 980 WH_Wischer_Fehler 5000;
BA_REL_ "GenSigTimeoutTime" BU_SG_REL_ BCM SG_ 980 BH_Blinker_Fehler 5000;
BA_REL_ "GenSigTimeoutTime" BU_SG_REL_ BCM SG_ 1313 STH_LED 2000;
BA_REL_ "GenSigTimeoutTime" BU_SG_REL_ BCM SG_ 832 STSG_HBFS_Tuer_Position 1000;
BA_REL_ "GenSigTimeoutTime" BU_SG_REL_ BCM SG_ 832 STSG_HBFS_TIG_bet_schliessen 1000;
BA_REL_ "GenSigTimeoutTime" BU_SG_REL_ BCM SG_ 832 STSG_HBFS_TIG_bet_oeffnen 1000;
BA_REL_ "GenSigTimeoutTime" BU_SG_REL_ BCM SG_ 832 STSG_HBFS_FFB_Taste_Schiebtuer 1000;
BA_REL_ "GenSigTimeoutTime" BU_SG_REL_ BCM SG_ 832 STSG_HBFS_TAG_betaetigt 1000;
BA_REL_ "GenSigTimeoutTime" BU_SG_REL_ BCM SG_ 832 STSG_HBFS_entriegeln_anfordern 1000;
BA_REL_ "GenSigTimeoutTime" BU_SG_REL_ BCM SG_ 832 STSG_HBFS_Tuer_Vorraste 1000;
BA_REL_ "GenSigTimeoutTime" BU_SG_REL_ BCM SG_ 832 STSG_HBFS_Bew_zu 1000;
BA_REL_ "GenSigTimeoutTime" BU_SG_REL_ BCM SG_ 832 STSG_HBFS_Bew_auf 1000;
BA_REL_ "GenSigTimeoutTime" BU_SG_REL_ BCM SG_ 832 STSG_HBFS_EOE_aktiv 1000;
BA_REL_ "GenSigTimeoutTime" BU_SG_REL_ BCM SG_ 832 STSG_HBFS_ZZH_Status_zu 1000;
BA_REL_ "GenSigTimeoutTime" BU_SG_REL_ BCM SG_ 832 STSG_HBFS_ZZH_Status_auf 1000;
BA_REL_ "GenSigTimeoutTime" BU_SG_REL_ BCM SG_ 832 STSG_HBFS_TAT 1000;
BA_REL_ "GenSigTimeoutTime" BU_SG_REL_ BCM SG_ 832 STSG_HBFS_ST_deaktivieren 1000;
BA_REL_ "GenSigTimeoutTime" BU_SG_REL_ BCM SG_ 832 STSG_HBFS_BTF 1000;
BA_REL_ "GenSigTimeoutTime" BU_SG_REL_ Gateway_Max SG_ 1440 LS_Helligkeit_IR 2000;
BA_REL_ "GenSigTimeoutTime" BU_SG_REL_ Gateway_Max SG_ 1440 RS_Regenmenge 2000;
BA_REL_ "GenSigTimeoutTime" BU_SG_REL_ Gateway_Max SG_ 980 BH_Blinker_li 5000;
BA_REL_ "GenSigTimeoutTime" BU_SG_REL_ Gateway_Max SG_ 980 BH_Blinker_re 5000;
BA_REL_ "GenSigTimeoutTime" BU_SG_REL_ Gateway_Max SG_ 980 BH_Lichthupe 5000;
BA_REL_ "GenSigTimeoutTime" BU_SG_REL_ Gateway_Max SG_ 980 BH_Fernlicht 5000;
BA_REL_ "GenSigTimeoutTime" BU_SG_REL_ Gateway_Max SG_ 980 WH_Tipwischen 5000;
BA_REL_ "GenSigTimeoutTime" BU_SG_REL_ Gateway_Max SG_ 980 WH_Intervall 5000;
BA_REL_ "GenSigTimeoutTime" BU_SG_REL_ Gateway_Max SG_ 980 WH_WischerStufe1 5000;
BA_REL_ "GenSigTimeoutTime" BU_SG_REL_ Gateway_Max SG_ 980 WH_WischerStufe2 5000;
BA_REL_ "GenSigTimeoutTime" BU_SG_REL_ Gateway_Max SG_ 980 WH_Intervallstufen 5000;
BA_REL_ "GenSigTimeoutTime" BU_SG_REL_ Gateway_Max SG_ 980 LRH_On_Off 5000;
BA_REL_ "GenSigTimeoutTime" BU_SG_REL_ Gateway_Max SG_ 1710 SP_FT_oben 5000;
BA_REL_ "GenSigTimeoutTime" BU_SG_REL_ Gateway_Max SG_ 1710 SP_FT_unten 5000;
BA_REL_ "GenSigTimeoutTime" BU_SG_REL_ Gateway_Max SG_ 1710 SP_FT_links 5000;
BA_REL_ "GenSigTimeoutTime" BU_SG_REL_ Gateway_Max SG_ 1710 SP_FT_rechts 5000;
BA_REL_ "GenSigTimeoutTime" BU_SG_REL_ Gateway_Max SG_ 1710 SP_BT_oben 5000;
BA_REL_ "GenSigTimeoutTime" BU_SG_REL_ Gateway_Max SG_ 1710 SP_BT_unten 5000;
BA_REL_ "GenSigTimeoutTime" BU_SG_REL_ Gateway_Max SG_ 1710 SP_BT_links 5000;
BA_REL_ "GenSigTimeoutTime" BU_SG_REL_ Gateway_Max SG_ 1710 SP_BT_rechts 5000;
BA_REL_ "GenSigTimeoutTime" BU_SG_REL_ Gateway_Max SG_ 1710 SP_Hzg_Taster 5000;
BA_REL_ "GenSigTimeoutTime" BU_SG_REL_ TSGGen3_BFS SG_ 319 PreCrash_Fenster_schliessen 2000;
BA_REL_ "GenSigTimeoutTime" BU_SG_REL_ TSGGen3_BFS SG_ 319 PreCrash_Tueren_Verriegeln 2000;
BA_REL_ "GenSigTimeoutTime" BU_SG_REL_ TSGGen3_BFS SG_ 1616 RA_Frequency 5000;
BA_REL_ "GenSigTimeoutTime" BU_SG_REL_ TSGGen3_BFS SG_ 1616 RA_Frequency_unit 5000;
BA_REL_ "GenSigTimeoutTime" BU_SG_REL_ TSGGen3_BFS SG_ 1616 RA_AM_Tuning 5000;
BA_REL_ "GenSigTimeoutTime" BU_SG_REL_ TSGGen3_BFS SG_ 1440 RS_Verglasung_schliessen 2000;
BA_REL_ "GenSigTimeoutTime" BU_SG_REL_ TSGGen3_BFS SG_ 1440 RS_defekt 2000;
BA_REL_ "GenSigTimeoutTime" BU_SG_REL_ TSGGen3_BFS SG_ 2463978603 KFT_FH_BT_hoch 1000;
BA_REL_ "GenSigTimeoutTime" BU_SG_REL_ TSGGen3_BFS SG_ 2463978603 KFT_FH_BT_tief 1000;
BA_REL_ "GenSigTimeoutTime" BU_SG_REL_ TSGGen3_BFS SG_ 2463978603 KFT_FH_Freigabe 1000;
BA_REL_ "GenSigTimeoutTime" BU_SG_REL_ TSGGen3_BFS SG_ 2463978603 KFT_Komfortfkt_Freigabe 1000;
BA_REL_ "GenSigTimeoutTime" BU_SG_REL_ TSGGen3_BFS SG_ 2463978603 SSA_BFT_FH_ansteuern 1000;
BA_REL_ "GenSigTimeoutTime" BU_SG_REL_ TSGGen3_FS SG_ 319 PreCrash_Fenster_schliessen 2000;
BA_REL_ "GenSigTimeoutTime" BU_SG_REL_ TSGGen3_FS SG_ 319 PreCrash_Tueren_Verriegeln 2000;
BA_REL_ "GenSigTimeoutTime" BU_SG_REL_ TSGGen3_FS SG_ 1616 RA_Frequency 5000;
BA_REL_ "GenSigTimeoutTime" BU_SG_REL_ TSGGen3_FS SG_ 1616 RA_Frequency_unit 5000;
BA_REL_ "GenSigTimeoutTime" BU_SG_REL_ TSGGen3_FS SG_ 1616 RA_AM_Tuning 5000;
BA_REL_ "GenSigTimeoutTime" BU_SG_REL_ TSGGen3_FS SG_ 1440 RS_Verglasung_schliessen 2000;
BA_REL_ "GenSigTimeoutTime" BU_SG_REL_ TSGGen3_FS SG_ 1440 RS_defekt 2000;
BA_REL_ "GenSigTimeoutTime" BU_SG_REL_ TSGGen3_FS SG_ 2463978603 KFT_FH_FT_hoch 1000;
BA_REL_ "GenSigTimeoutTime" BU_SG_REL_ TSGGen3_FS SG_ 2463978603 KFT_FH_FT_tief 1000;
BA_REL_ "GenSigTimeoutTime" BU_SG_REL_ TSGGen3_FS SG_ 2463978603 KFT_FH_Freigabe 1000;
BA_REL_ "GenSigTimeoutTime" BU_SG_REL_ TSGGen3_FS SG_ 2463978603 KFT_Komfortfkt_Freigabe 1000;
BA_REL_ "GenSigTimeoutTime" BU_SG_REL_ TSGGen3_FS SG_ 2463978603 SSA_FT_FH_ansteuern 1000;
BA_REL_ "GenSigTimeoutTime" BU_SG_REL_ TSGGen3_HBFS SG_ 319 PreCrash_Fenster_schliessen 2000;
BA_REL_ "GenSigTimeoutTime" BU_SG_REL_ TSGGen3_HBFS SG_ 319 PreCrash_Tueren_Verriegeln 2000;
BA_REL_ "GenSigTimeoutTime" BU_SG_REL_ TSGGen3_HBFS SG_ 1616 RA_Frequency 5000;
BA_REL_ "GenSigTimeoutTime" BU_SG_REL_ TSGGen3_HBFS SG_ 1616 RA_Frequency_unit 5000;
BA_REL_ "GenSigTimeoutTime" BU_SG_REL_ TSGGen3_HBFS SG_ 1616 RA_AM_Tuning 5000;
BA_REL_ "GenSigTimeoutTime" BU_SG_REL_ TSGGen3_HBFS SG_ 1440 RS_Verglasung_schliessen 2000;
BA_REL_ "GenSigTimeoutTime" BU_SG_REL_ TSGGen3_HBFS SG_ 1440 RS_defekt 2000;
BA_REL_ "GenSigTimeoutTime" BU_SG_REL_ TSGGen3_HBFS SG_ 2463978603 KFT_FH_HBFS_hoch 1000;
BA_REL_ "GenSigTimeoutTime" BU_SG_REL_ TSGGen3_HBFS SG_ 2463978603 KFT_FH_HBFS_tief 1000;
BA_REL_ "GenSigTimeoutTime" BU_SG_REL_ TSGGen3_HBFS SG_ 2463978603 KFT_FH_Freigabe 1000;
BA_REL_ "GenSigTimeoutTime" BU_SG_REL_ TSGGen3_HBFS SG_ 2463978603 KFT_Komfortfkt_Freigabe 1000;
BA_REL_ "GenSigTimeoutTime" BU_SG_REL_ TSGGen3_HBFS SG_ 2463978603 SSA_HBFT_FH_ansteuern 1000;
BA_REL_ "GenSigTimeoutTime" BU_SG_REL_ TSGGen3_HBFS SG_ 832 STSG_HBFS_Tuer_Vorraste 1000;
BA_REL_ "GenSigTimeoutTime" BU_SG_REL_ TSGGen3_HBFS SG_ 832 STSG_HBFS_Thermo_aktiv 1000;
BA_REL_ "GenSigTimeoutTime" BU_SG_REL_ TSGGen3_HBFS SG_ 832 STSG_HBFS_Bew_zu 1000;
BA_REL_ "GenSigTimeoutTime" BU_SG_REL_ TSGGen3_HBFS SG_ 832 STSG_HBFS_Bew_auf 1000;
BA_REL_ "GenSigTimeoutTime" BU_SG_REL_ TSGGen3_HBFS SG_ 832 STSG_HBFS_EOE_aktiv 1000;
BA_REL_ "GenSigTimeoutTime" BU_SG_REL_ TSGGen3_HBFS SG_ 832 STSG_HBFS_ZZH_Status_zu 1000;
BA_REL_ "GenSigTimeoutTime" BU_SG_REL_ TSGGen3_HBFS SG_ 832 STSG_HBFS_ZZH_Status_auf 1000;
BA_REL_ "GenSigTimeoutTime" BU_SG_REL_ TSGGen3_HBFS SG_ 832 STSG_HBFS_ZZH_Initialisierung 1000;
BA_REL_ "GenSigTimeoutTime" BU_SG_REL_ TSGGen3_HBFS SG_ 832 STSG_HBFS_ZZH_Freigabe 1000;
BA_REL_ "GenSigTimeoutTime" BU_SG_REL_ TSGGen3_HBFS SG_ 832 STSG_HBFS_UEKB_aktiv 1000;
BA_REL_ "GenSigTimeoutTime" BU_SG_REL_ TSGGen3_HBFS SG_ 832 STSG_HBFS_Einklemm_defekt 1000;
BA_REL_ "GenSigTimeoutTime" BU_SG_REL_ TSGGen3_HBFS SG_ 832 STSG_HBFS_Einklemm_aktiv 1000;
BA_REL_ "GenSigTimeoutTime" BU_SG_REL_ TSGGen3_HFS SG_ 319 PreCrash_Fenster_schliessen 2000;
BA_REL_ "GenSigTimeoutTime" BU_SG_REL_ TSGGen3_HFS SG_ 319 PreCrash_Tueren_Verriegeln 2000;
BA_REL_ "GenSigTimeoutTime" BU_SG_REL_ TSGGen3_HFS SG_ 1616 RA_Frequency 5000;
BA_REL_ "GenSigTimeoutTime" BU_SG_REL_ TSGGen3_HFS SG_ 1616 RA_Frequency_unit 5000;
BA_REL_ "GenSigTimeoutTime" BU_SG_REL_ TSGGen3_HFS SG_ 1616 RA_AM_Tuning 5000;
BA_REL_ "GenSigTimeoutTime" BU_SG_REL_ TSGGen3_HFS SG_ 1440 RS_Verglasung_schliessen 2000;
BA_REL_ "GenSigTimeoutTime" BU_SG_REL_ TSGGen3_HFS SG_ 1440 RS_defekt 2000;
BA_REL_ "GenSigTimeoutTime" BU_SG_REL_ TSGGen3_HFS SG_ 2463978603 KFT_FH_HFS_hoch 1000;
BA_REL_ "GenSigTimeoutTime" BU_SG_REL_ TSGGen3_HFS SG_ 2463978603 KFT_FH_HFS_tief 1000;
BA_REL_ "GenSigTimeoutTime" BU_SG_REL_ TSGGen3_HFS SG_ 2463978603 KFT_FH_Freigabe 1000;
BA_REL_ "GenSigTimeoutTime" BU_SG_REL_ TSGGen3_HFS SG_ 2463978603 KFT_Komfortfkt_Freigabe 1000;
BA_REL_ "GenSigTimeoutTime" BU_SG_REL_ TSGGen3_HFS SG_ 2463978603 SSA_HFT_FH_ansteuern 1000;
BA_REL_ "GenSigTimeoutTime" BU_SG_REL_ WLC_01_CFD SG_ 1616 RA_Frequency 5000;
BA_REL_ "GenSigTimeoutTime" BU_SG_REL_ WLC_01_CFD SG_ 1616 RA_Frequency_unit 5000;
BA_REL_ "GenSigTimeoutTime" BU_SG_REL_ WLC_01_CFD SG_ 1616 RA_AM_Tuning 5000;
VAL_ 1031 PLAIPA_PaCo_ParkingSlots_02 0 "Nothing" 1 "One_ParkingSlot" 2 "Two_ParkingSlots" 3 "Three_ParkingSlots" 4 "Four_ParkingSlots" 5 "Five_ParkingSlots" 6 "Six_ParkingSlots" 7 "Seven_ParkingSlots" 8 "Eight_ParkingSlots" ;
VAL_ 1031 RA_PaCo_MainState 0 "Init" 1 "InOperation_NoError" 2 "Fehler" ;
VAL_ 1031 RA_PaCo_FunctionState 0 "Available" 1 "Trajectory_Recording" 2 "Activating" 3 "Reversing_In_Intervention" 4 "Completed" 5 "Cancelled" 6 "Driver_TakingOver" 7 "Not_Available" ;
VAL_ 1031 RA_PaCo_InterventionPossible 0 "Not_Possible" 1 "Possible_Or_Active" ;
VAL_ 1031 RA_PaCo_UnavailableReason 0 "No_Reason" 1 "EmergencyAssist_active" 2 "Offroad_active" 3 "ASR_ESP_inactive" 4 "SystemFailure" 5 "FunctionDefective" 6 "AnyDoorOpen" 7 "TrunkOpen" 8 "GeoFencingRA" 9 "SpeedOutOfRange" 10 "TrajectoryNotAvailable" 11 "TrailerHitched" ;
VAL_ 1031 PLAIPA_PaCo_RemoteActivatable 0 "NotActivatable" 1 "Activatable" 2 "NotActivatable_temp" 3 "NotActivatable_geoFencing" 4 "NotActivatable_defect" ;
VAL_ 1031 PLAIPA_PaCo_GarageActivatable 0 "NotActivatable" 1 "Activatable" ;
VAL_ 1031 RPA_Anf_Sonder_Funktion_Status 0 "Init" 1 "Anforderung" 2 "Aktiv" 3 "Beendet" 4 "Abbruch_Klemmenabschaltung" ;
VAL_ 1031 RPA_Anf_Sonder_Klemme_15 0 "Init" 1 "KL_15_HW" 3 "KL_15_HW_UND_CAN" ;
VAL_ 1031 RPA_Anf_WFS_Freigabe 0 "Keine" 1 "Uneingeschraenkt" 2 "Eingeschraenkt" ;
VAL_ 1031 PLAIPA_PaCo_SwitchPossible 0 "Not_Possible" 1 "Possible" ;
VAL_ 1031 PLAIPA_PaCo_ParkingSlots 0 "Nothing" 1 "One_ParkingSlot" 2 "Two_ParkingSlots" 3 "Three_ParkingSlots" 4 "Four_ParkingSlots" ;
VAL_ 1031 PLAIPA_PaCo_UnavailableReason 0 "No_Reason" 1 "EmergencyAssist_active" 2 "Offroad_active" 3 "TooSmall_ParkOutSlot" 4 "ASR_ESP_inactive" 5 "SlidingDoor_open" 6 "LeafDoor_open" 7 "SystemFailure" 8 "FunctionDefective" 9 "AnyDoorOpen" 10 "TrunkOpen" 11 "GeoFencingIPA" ;
VAL_ 1031 PLAIPA_PaCo_InterventionPossible 0 "Not_Possible" 1 "Possible_Or_Active" ;
VAL_ 1031 PLAIPA_PaCo_MainState 0 "Init" 1 "InOperation_NoError" 7 "Fehler" ;
VAL_ 1031 PLAIPA_PaCo_FunctionState 0 "Resume_Possible" 1 "Park_In_SearchMode" 2 "Park_In_SlotFound" 3 "Park_Out_SlotFound" 4 "Park_In_Intervention" 5 "Park_Out_Intervention" 6 "Standby" 7 "Completed" 8 "Cancelled" 9 "ParkIn_NoPass_FrontLeft" 10 "ParkIn_NoPass_FrontRight" 11 "ParkIn_NoPass_BackLeft" 12 "ParkIn_NoPass_BackRight" 13 "Not_Activatable" 14 "Remote_Activation" 15 "Remote_HandingOver" 16 "Remote_In_Intervention" 17 "Remote_Out_Intervention" ;
VAL_ 1031 PLAIPA_PaCo_PLEPossible 0 "Not_Possible" 1 "Possible" ;
VAL_ 1031 PLAIPA_PaCo_Button 0 "Init_or_not_equipped" 1 "Button_not_pressed" 2 "Button_pressed_debounced" 3 "Error" ;
VAL_ 319 PreCrash_Charisma_FahrPr 0 "keine_Funktion" 1 "Programm_1" 2 "Programm_2" 3 "Programm_3" 4 "Programm_4" 5 "Programm_5" 6 "Programm_6" 7 "Programm_7" 8 "Programm_8" 9 "Programm_9" 10 "Programm_10" 11 "Programm_11" 12 "Programm_12" 13 "Programm_13" 14 "Programm_14" 15 "Programm_15" ;
VAL_ 319 PreCrash_Charisma_Status 0 "Init" 1 "verfuegbar" 2 "nicht_verfuegbar" 3 "asynchron_durch_Fahrerwunsch" ;
VAL_ 319 PreCrash_Schiebedach_schliessen 0 "keine_Schliessung" 1 "Schliessung_angefordert" ;
VAL_ 319 PreCrash_Fenster_schliessen 0 "keine_Schliessung" 1 "Schliessung_angefordert" ;
VAL_ 319 PreCrash_Blinken 0 "keine_Blinkanforderung" 1 "Warnblinken" 2 "RECAS_Blinken" 3 "Notbremsblinken" ;
VAL_ 319 SC_PreSense_FCWP 0 "Warnung_gilt_fuer_Objekte" 1 "Warnung_gitl_fuer_Fussgaenger" ;
VAL_ 319 PreCrash_Tueren_Verriegeln 0 "keine_Anforderung" 1 "Tueren_Verriegeln" ;
VAL_ 319 PreCrash_FS_Laengsverstellung 0 "nicht_angefordert" 1 "angefordert" ;
VAL_ 319 PreCrash_Anforderung_AFR 0 "keine_Anforderung" 1 "linke_Seite" 2 "rechte_Seite" 3 "Vorderachse" 4 "Hinterachse" 5 "Vorwarnung" 7 "Init" ;
VAL_ 319 SC_PreCrash_LED 0 "keine_Anzeige" 1 "Stufe_1_glimmen" 2 "Stufe_2_leuchten" 3 "Stufe_3_blinken" ;
VAL_ 319 PreCrash_FS_Pneumatik_ansteuern 0 "keine_Anforderung" 1 "Pneumatik_ansteuern" ;
VAL_ 319 PreCrash_BFS_Pneumatik_ansteuern 0 "keine_Anforderung" 1 "Pneumatik_ansteuern" ;
VAL_ 319 PreCrash_Fo_Pneumatik_ansteuern 0 "keine_Anforderung" 1 "Pneumatik_ansteuern" ;
VAL_ 319 PreCrash_FS_Sitzlehne_verfahren 0 "keine_Anforderung" 1 "reserviert" 2 "reserviert" 3 "Sitzlehnenkopf_in_pos_xRichtung_verfahrenvor" 4 "Sitzlehnenkopf_in_neg_xRichtung_verfahrenzurueck" 6 "reserviert" 7 "Lehnenkopfverstellung_ansteuern" ;
VAL_ 319 PreCrash_BFS_Sitzlehne_verfahren 0 "keine_Anforderung" 1 "reserviert" 2 "reserviert" 3 "Sitzlehnenkopf_in_pos_xRichtung_verfahrenvor" 4 "Sitzlehnenkopf_in_neg_xRichtung_verfahrenzurueck" 6 "reserviert" 7 "Lehnenkopfverstellung_ansteuern" ;
VAL_ 319 PreCrash_Fo_Sitzlehne_verfahren 0 "keine_Anforderung" 1 "reserviert" 2 "reserviert" 3 "Sitzlehnenkopf_in_pos_xRichtung_verfahrenvor" 4 "Sitzlehnenkopf_in_neg_xRichtung_verfahrenzurueck" ;
VAL_ 319 PreCrash_FS_KSV_verfahren 0 "keine_Anforderung" 1 "in_pos_xRichtung_verfahren" 2 "in_neg_xRichung_verfahren" 3 "in_pos_zRichtung_verfahren" 4 "in_neg_zRichtung_verfahren" 5 "in_pos_xRichtung_und_neg_zRichtung_verfahren" 6 "in_pos_x_Richtung_und_pos_zRichtung_verfahren" 7 "in_neg_xRichtung_und_neg_zRichtung_verfahren" 8 "in_neg_xRichtung_und_pos_zRichtung_verfahren" 9 "Kopfstuetze_ansteuern" ;
VAL_ 319 PreCrash_BFS_KSV_verfahren 0 "keine_Anforderung" 1 "in_pos_xRichtung_verfahren" 2 "in_neg_xRichung_verfahren" 3 "in_pos_zRichtung_verfahren" 4 "in_neg_zRichtung_verfahren" 5 "in_pos_xRichtung_und_neg_zRichtung_verfahren" 6 "in_pos_x_Richtung_und_pos_zRichtung_verfahren" 7 "in_neg_xRichtung_und_neg_zRichtung_verfahren" 8 "in_neg_xRichtung_und_pos_zRichtung_verfahren" 9 "Kopfstuetze_ansteuern" ;
VAL_ 319 PreCrash_Fo_KSV_verfahren 0 "keine_Anforderung" 1 "in_pos_xRichtung_verfahren" 2 "in_neg_xRichung_verfahren" 3 "in_pos_zRichtung_verfahren" 4 "in_neg_zRichtung_verfahren" 5 "in_pos_xRichtung_und_neg_zRichtung_verfahren" 6 "in_pos_x_Richtung_und_pos_zRichtung_verfahren" 7 "in_neg_xRichtung_und_neg_zRichtung_verfahren" 8 "in_neg_xRichtung_und_pos_zRichtung_verfahren" ;
VAL_ 319 PreCrash_BFS_Laengsverstellung 0 "nicht_angefordert" 1 "angefordert" ;
VAL_ 319 SC_PreCrash_Warnung 0 "keine_Anzeige" 1 "latente_Vorwarnung" 2 "Vorwarnung" 3 "Akutwarnung" 4 "Eingriff" 5 "Fahreruebernahmeaufforderung" 6 "Abbiegewarnung" 7 "Basiseingriff" 8 "Heckeingriff" ;
VAL_ 319 SC_PreCrash_Texte 0 "keine_Anzeige" 1 "Systemstoerung" 2 "keine_Sensorsicht" 3 "Demomodus" 4 "System_aus" 5 "Anhaengerbetrieb" 6 "ESC_aus" 7 "zurzeit_eingeschraenkt" 8 "zurzeit_eingeschraenkt_ESP_Aus" 9 "Initialisierung" ;
VAL_ 1616 RA_Radio_Error_Flag 0 "kein_KD_Fehler" 1 "KD_Fehler" ;
VAL_ 1616 RA_Frequency_unit 0 "1_kHz" 1 "100_kHz" ;
VAL_ 1616 RA_AM_Tuning 0 "frequency_locked" 1 "AM_tuning" ;
VAL_ 695 RCTA_PaCo_MainState 0 "Init" 1 "InOperation_NoError" 7 "Fehler" ;
VAL_ 695 RCTA_Status_FoD 0 "Init" 1 "keine_FoD_Freischaltung" 2 "FoD_Freischaltung" ;
VAL_ 695 RCTA_PaCo_BrakeIntervention 0 "Inactive" 1 "Active" ;
VAL_ 695 RCTA_PaCo_UnavailableReason 0 "No_Reason" 1 "Trailer_Hitched" ;
VAL_ 695 RCTA_Anf_Warnruck 0 "Init_kein_Warnruck" 1 "schwacher_Warnruck" 2 "mittlerer_Warnruck" 3 "starker_Warnruck" ;
VAL_ 695 RCTA_Modus 0 "kein_Fehler_verfuegbar" 1 "Eingriffsmute" 2 "eingeschraenkt_Verfuegbar_pata2_Warnruck_etc" 3 "Anhaengerbetrieb" 4 "Init_nicht_codiert" 5 "keine_Sensorsicht_Blindheit" 6 "zur_Zeit_nicht_verfuegbar_temp_Fehler" 7 "Systemstoerung_dauer_Fehler" ;
VAL_ 695 RCTA_Kritikalitaetslevel_rechts 0 "unkritisch" 1 "Kritikalitaetslevel_1" 2 "Kritikalitaetslevel_2" 3 "Kritikalitaetslevel_3" 4 "Kritikalitaetslevel_4" 5 "Kritikalitaetslevel_5" 6 "reserviert" 7 "nicht_bewertbar" ;
VAL_ 695 RCTA_Kritikalitaetslevel_links 0 "unkritisch" 1 "Kritikalitaetslevel_1" 2 "Kritikalitaetslevel_2" 3 "Kritikalitaetslevel_3" 4 "Kritikalitaetslevel_4" 5 "Kritikalitaetslevel_5" 6 "reserviert" 7 "nicht_bewertbar" ;
VAL_ 695 RCTA_Info_rechts 0 "RCTA_hat_rechts_nichts_erkannt" 1 "RCTA_hat_rechts_blind_erkannt" 2 "RCTA_hat_rechts_frei_erkannt" 3 "RCTA_hat_rechts_unkritisch_erkannt" 4 "RCTA_hat_rechts_relevant_aber_unkritisch_erkannt" 5 "RCTA_hat_rechts_kritisch_erkannt" 6 "RCTA_hat_rechts_sehr_kritisch_erkannt" 7 "RCTA_meldet_rechts_Kollision_steht_bevor" ;
VAL_ 695 RCTA_Anforderung_HMS 0 "keine Anforderung" 1 "halten" 2 "parken" 3 "Halten Standby" 4 "anfahren" 5 "loesen_ueber_Rampe" ;
VAL_ 695 RCTA_Bremsruck_Anforderung 0 "nicht_angefordert" 1 "angefordert" ;
VAL_ 695 RCTA_Bremsruck_Freigabe 0 "keine_Freigabe" 1 "Freigabe" ;
VAL_ 695 RCTA_Info_links 0 "RCTA_hat_links_nichts_erkannt" 1 "RCTA_hat_links_blind_erkannt" 2 "RCTA_hat_links_frei_erkannt" 3 "RCTA_hat_links_unkritisch_erkannt" 4 "RCTA_hat_links_relevant_aber_unkritisch_erkannt" 5 "RCTA_hat_links_kritisch_erkannt" 6 "RCTA_hat_links_sehr_kritisch_erkannt" 7 "RCTA_meldet_links_Kollision_steht_bevor" ;
VAL_ 695 RCTA_PaCo_BrakingPossible 0 "Not_Possible" 1 "Possible" ;
VAL_ 695 RCTA_Status 0 "Aus" 1 "Passiv" 2 "Aktiv" 3 "Fehler" ;
VAL_ 695 RCTA_Warnton 0 "Aus" 1 "Ein" ;
VAL_ 695 RCTA_Notbremsung_Freigabe 0 "keine_Freigabe" 1 "Freigabe" ;
VAL_ 695 RCTA_Notbremsung_Anforderung 0 "Init" 255 "Fehler" ;
VAL_ 1711 RV_Video_on 0 "Kamerabild wird nicht angezeigt" 1 "Kamerabild wird angezeigt" ;
VAL_ 1711 RV_Dark_Screen 0 "Kamerabild nicht verdunkeln" 1 "Kamerabild verdunkeln" ;
VAL_ 1711 RV_HMI_Mode 0 "Parkluecke  (Modus 1)" 1 "Parallel zur Straße (Modus 2)" 2 "reserviert" 3 "Kalibrierung (nur Diagnose)" ;
VAL_ 1711 RV_GL_side 0 "Guidelines_abgeschaltet" 1 "Guidelines_Anzeige_rechte_Seite" 2 "Guiedelines_Anzeige_linke_Seite" 3 "Guiedelines_Anzeige_beide_Seiten" ;
VAL_ 1711 RV_System_aktiv 0 "System nicht betriebsbereit" 1 "System betriebsbereit" ;
VAL_ 1711 RV_Reinigung_Anf 0 "nicht_reinigen" 1 "reinigen" ;
VAL_ 1711 RV_Settings_enabled 0 "Menu 'Einstellungen' nicht aktiviert" 1 "Menu 'Einstellungen' aktiviert" ;
VAL_ 1711 RV_Menu_Item 0 "HMI Mode als ausgewaehlt markiert" 1 "Helligkeit als ausgewaehlt markiert" 2 "Kontrast als ausgewaehlt markiert" 3 "Farbsaettigung als ausgewaehlt markiert" ;
VAL_ 1711 SV_Video_on 0 "SideView_aus_/_nicht_verbaut" 1 "SideView_an" ;
VAL_ 1711 RV_Calib_Fehler 0 "Kalibrierung_i.O." 1 "RearView_nicht_kalibriert" ;
VAL_ 1711 RV_GL_Trailer_connect 0 "Guidelines_werden_angezeigt" 1 "Guidelines_wegen_angekoppeltem_Anhänger_deaktiviert" ;
VAL_ 1711 RV_GL_Trunk_open 0 "Guidelines_werden_angezeigt" 1 "Guidelines_wegen_geöffneter_Heckklappe_deaktiviert" ;
VAL_ 1711 RV_GL_LWS_Fehler 0 "Guidelines_werden_angezeigt" 1 "Guidelines_wegen_nicht_kalibriertem_Lenkwinkelsensor_deaktiviert" ;
VAL_ 1711 ZFAS_Umfeldbeleuchtung_Anf 0 "nicht_angefordert" 1 "angefordert" ;
VAL_ 2264486920 RHP_QFK_AnfStat 1 "Init" 2 "Bereit" 4 "Eingriff" 13 "Eingriff_HandsOff" ;
VAL_ 2264486920 RHP_TV_Trigger 0 "No_Request" 1 "Request" ;
VAL_ 2264486920 RHP_QFK_KruemmSoll_VZ 0 "positiv" 1 "negativ" ;
VAL_ 2264486920 RHP_Status_Long 0 "off" 1 "standby" 2 "active" 3 "reserve" 4 "driver_override" 5 "reserve" 6 "reserve" 7 "failure" ;
VAL_ 2264486920 RHP_Ruckfreigabe 0 "keine_Freigabe" 1 "Freigabe" ;
VAL_ 2264486920 RHP_Warnruckeln_Anf 0 "keine_Anforderung" 1 "schwaches_Warnruckeln" 2 "mittleres_Warnruckeln" 3 "starkes_Warnruckeln" ;
VAL_ 2264486920 RHP_Anf_ASIL 0 "QM" 1 "A" 2 "B" 3 "C" ;
VAL_ 2264486920 RHP_Anforderung_HMS 0 "keine_Anforderung" 1 "halten" 2 "parken" 3 "halten_Standby" 4 "anfahren" 5 "loesen_ueber_Rampe" 7 "HMS_uebernehmen" ;
VAL_ 2264486920 RHP_Sollbeschleunigung 2046 "Neutralwert" 2047 "Fehler" ;
VAL_ 2264486920 RHP_TSK_Status 0 "off" 1 "init" 2 "standby" 3 "active" 4 "driver_override" 5 "shutdown" 6 "reversible_failure" 7 "irreversible_failure" ;
VAL_ 2264486920 RHP_Minimale_Bremsung 0 "Anf_Min_Bremsung_nicht_aktiv" 1 "Anf_Min_Bremsung_aktiv" ;
VAL_ 2264486920 RHP_Uss_Anforderung 0 "UltraschallsensorenAus" 1 "UltraschallsensorenAn" ;
VAL_ 2264486920 RHP_Verz_Anf 1023 "keine_Anforderung" ;
VAL_ 2264486920 RHP_Verz_Freigabe 0 "Verzoegerung_nicht_freigeben" 1 "Verzoegerung_freigeben" ;
VAL_ 2264486920 RHP_Status_Lat 0 "off" 1 "standby" 2 "active" 3 "reserve" 4 "driver_oversteer" 5 "reserve" 6 "reserve" 7 "failure" ;
VAL_ 2264486920 RHP_StartStopp_Info 0 "Motorlauf_langfristig_nicht_notwendig_Stoppfreigabe" 1 "Motoranlauf_nicht_zwingend_notwendig_Stoppverbot_keine_Startanforderung" 2 "Motoranlauf_zwingend_notwendig_Startanforderung" 3 "Systemfehler" ;
VAL_ 2264486920 RHP_nachtr_Stopp_Anf 0 "nicht_angefordert" 1 "angefordert" ;
VAL_ 2264486920 RHP_Freilaufstrategie_TSK 0 "Freilaufstr_nicht_angefordert" 1 "Freilaufstr_angefordert" ;
VAL_ 2264486920 RHP_SCAM_HeatingRequest 0 "init" 1 "not_ready" 2 "no_heating_request" 3 "heating_request" ;
VAL_ 2264486920 RHP_Fahrzeughupe_Anf 0 "Keine_Anforderung" 1 "Anforderung_Fahrzeughupe" ;
VAL_ 2264486920 RHP_HOS 0 "not_active" 1 "hands_on" 2 "hands_off" 3 "hands_on_request" ;
VAL_ 2264486920 RHP_Status_Function 0 "off" 1 "standby" 2 "ready" 3 "active" 4 "reserve" 5 "reserve" 6 "reserve" 7 "failure" ;
VAL_ 2264486920 RHP_EA_AnfStat 0 "init" 1 "ready" 2 "interference_PHASE3" ;
VAL_ 2264486920 RHP_QFK_KrSoll_VZ 0 "positiv" 1 "negativ" ;
VAL_ 2264486920 RHP_Warnblinken 0 "kein_Blinken" 1 "Warnblinken_Taster" ;
VAL_ 2264486920 RHP_Innenraumlicht_Anf 0 "Innenraumbeleuchtung_ausschalten" 1 "Innenraumbeleuchtung_einschalten" ;
VAL_ 2264486920 RHP_Spurwechsel_Ready 0 "nicht_moeglich" 1 "links_moeglich" 2 "rechts_moeglich" 3 "links_rechts_moeglich" 4 "links_blinken" 5 "rechts_blinken" ;
VAL_ 2264486920 RHP_RBF_Available 0 "Init" 1 "Available" 2 "NotAvailable" 3 "Reserved" ;
VAL_ 2264486920 RHP_PreCrash_Anf 0 "keine_Anforderung" 1 "Aktionsgenerierte_Warnung_1" 2 "Aktionsgenerierte_Warnung_2" 3 "Aktionsgenerierte_Warnung_3" 4 "Aktionsgenerierte_Warnung_4" 5 "Aktionsgenerierte_Warnung_5" 6 "Aktionsgenerierte_Warnung_6" 7 "Aktionsgenerierte_Warnung_7" ;
VAL_ 2264486920 RHP_EA_PreCrash 0 "Keine_Anforderung" 1 "Aktionsgenerierte_Warnung_1" 2 "Aktionsgenerierte_Warnung_2" 3 "Aktionsgenerierte_Warnung_3" 4 "Aktionsgenerierte_Warnung_4" 5 "Aktionsgenerierte_Warnung_5" 6 "Aktionsgenerierte_Warnung_6" 7 "Aktionsgenerierte_Warnung_7" ;
VAL_ 2264486920 RHP_Parking_St 0 "None" 1 "Slot_detect" 2 "Guidance" 3 "Abort" ;
VAL_ 2264486920 RHP_EA_Innenraumlicht 0 "Innenraumbeleuchtun_ausschalten" 1 "Innenraumbeleuchtung_einschalten" ;
VAL_ 2264486920 RHP_EA_eCall 0 "Keine_Anforderung" 1 "Ausloesen_eCall" ;
VAL_ 2264486920 RHP_OPSEnable 0 "Initial" 1 "Not_enable" 2 "Enable" ;
VAL_ 2264486920 RHP_eCall_Anf 0 "Keine_Anforderung" 1 "Ausloesen_eCall" ;
VAL_ 2264486920 RHP_EA_Tueren 0 "Keine_Anforderung" 1 "Tueren_entriegeln" ;
VAL_ 1440 LS_Helligkeit_IR 254 "Init" 255 "Fehler" ;
VAL_ 1440 LS_Helligkeit_FW 1022 "Init" 1023 "Fehler" ;
VAL_ 1440 LS_defekt 0 "OK" 1 "defekt" ;
VAL_ 1440 LS_Verbau 0 "Init" 1 "Lichtsensor_verbaut" ;
VAL_ 1440 RS_Regenmenge 0 "0" 1 "0,0_bis_0,3" 2 "0,31_bis_1,4" 3 "1,41_bis_2,0" 4 "2,01_bis_2,8" 5 "2,81_bis_3,3" 6 "3,31_bis_4,0" 7 "4,01_bis_5,0" 8 "5,01_bis_7,0" 9 "7,01_bis_9,0" 10 "9,01_bis_11,0" 11 "11,01_bis_15,0" 12 "15,01_bis_22,0" 13 ">22,01" 14 "Init" 15 "Fehler" ;
VAL_ 1440 RS_Schwall 0 "Aus" 1 "Ein" ;
VAL_ 1440 RS_Verbau 0 "Init" 1 "Regensensor verbaut" ;
VAL_ 1440 RS_Verglasung_schliessen 0 "Verglasung nicht schliessen" 1 "Verglasung schliessen" ;
VAL_ 1440 RS_defekt 0 "OK" 1 "defekt" ;
VAL_ 1440 RS_Wischergeschwindigkeit 0 "kein Wischen" 1 "42 Huebe/min" 2 "45 Huebe/min" 3 "48 Huebe/min" 4 "51 Huebe/min" 5 "54 Huebe/min" 6 "57 Huebe/min" 7 "60 Huebe/min" ;
VAL_ 1440 RLS_Vorfeldhelligkeit_Boost 0 "groesser_24413_Lux" 1 "bis_24413_Lux" 2 "bis_22193_Lux" 3 "bis_20176_Lux" 4 "bis_18342_Lux" 5 "bis_16647_Lux" 6 "bis_15158_Lux" 7 "bis_13780_Lux" 8 "bis_12527_Lux" 9 "bis_11388_Lux" 10 "bis_10353_Lux" 11 "bis_9412_Lux" 12 "bis_8556_Lux" 13 "bis_7778_Lux" 14 "bis_7071_Lux" 15 "bis_6428_Lux" ;
VAL_ 1440 SLS_Helligkeit_IR 254 "Init" 255 "Fehler" ;
VAL_ 1504 MD1_Position 126 "Init" 127 "nicht_normiert" ;
VAL_ 1504 MD1_Lage 0 "Ausstelllage" 1 "Schiebelage" ;
VAL_ 1504 MD3_Lage 0 "Ausstelllage" 1 "Schiebelage" ;
VAL_ 1504 MRollo_Position 126 "Init" 127 "nicht_normiert" ;
VAL_ 1504 MRollo_Lage 0 "Ausstelllage" 1 "Schiebelage" ;
VAL_ 1504 SAD_normiert 0 "inaktiv" 1 "aktiv" ;
VAL_ 1504 SAD_Thermoschutz 0 "inaktiv" 1 "aktiv" ;
VAL_ 1504 SAD_UEKB_aktiv 0 "inaktiv" 1 "aktiv" ;
VAL_ 1504 Rollo_normiert 0 "inaktiv" 1 "aktiv" ;
VAL_ 1504 Rollo_Thermoschutz 0 "inaktiv" 1 "aktiv" ;
VAL_ 1504 Rollo_UEKB_aktiv 0 "inaktiv" 1 "aktiv" ;
VAL_ 1504 SAD_Taster_Deckel_hi 0 "nicht_betaetigt" 1 "man_sl_zu" 2 "auto_sl_zu" 3 "man_sl_auf" 4 "auto_sl_auf" 5 "man_al_auf" 6 "auto_al_auf" 7 "man_al_zu" 8 "auto_al_zu" 14 "fehler_schalter_haengt" 15 "fehler_schalter_unplausibel" ;
VAL_ 1504 SAD_Taster_Deckel_vo 0 "nicht_betaetigt" 1 "man_sl_zu" 2 "auto_sl_zu" 3 "man_sl_auf" 4 "auto_sl_auf" 5 "man_al_auf" 6 "auto_al_auf" 7 "man_al_zu" 8 "auto_al_zu" 14 "fehler_schalter_haengt" 15 "fehler_schalter_unplausibel" ;
VAL_ 1504 SAD_Taster_Rollo_hi 0 "nicht_betaetigt" 1 "man_zu" 2 "auto_zu" 3 "man_auf" 4 "auto_auf" 6 "fehler_schalter_haengt" 7 "fehler_schalter_unplausibel" ;
VAL_ 1504 SAD_Taster_Rollo_vo 0 "nicht_betaetigt" 1 "man_zu" 2 "auto_zu" 3 "man_auf" 4 "auto_auf" 6 "fehler_schalter_haengt" 7 "fehler_schalter_unplausibel" ;
VAL_ 1504 SAD_Anf_ESC_Zuschaltung 0 "inaktiv" 1 "aktiv" ;
VAL_ 2463978698 SAL_Ambex_CH_state 0 "ComingHomeOFF" 1 "ComingHomeSTATIC" 3 "ComingHomeAMBIANCE" ;
VAL_ 2463978698 SAL_Ambex_LH_state 0 "LeavingHomeOFF" 1 "LeavingHomeSTATIC" 3 "LeavingHomeAMBIANCE" ;
VAL_ 2463978698 SAL_EA_Blinken_Status 0 "init" 1 "nicht_bereit" 2 "bereit" 3 "aktiv_links" 4 "aktiv_rechts" ;
VAL_ 2463978698 SAL_EA_Warnblinken 0 "inaktiv" 1 "aktiv" ;
VAL_ 2463978698 SAL_Ambex_Lichtsensor_ch_lh_ein 0 "Tag_erkannt" 1 "Nacht_erkannt" ;
VAL_ 2463978698 SAL_Strg_Beleuchtung_WBT 254 "Init" 255 "Fehler" ;
VAL_ 2463978815 SBM_Veto_Fahrstufe_extern 0 "kein_Veto" 1 "Randbedingungen_nicht_erfuellt" 2 "reserviert" 3 "Fehler" ;
VAL_ 2463978815 SBM_FahrerAkt_Schaltbetaetigung 0 "nicht_betaetigt" 1 "Schaltbetaetigung_betaetigt" ;
VAL_ 2463978815 SBM_FahrerAkt_P_Taste 0 "nicht_betaetigt" 1 "P_Taste_betaetigt" ;
VAL_ 2463978815 SBM_FahrerAkt_Lenkradpaddle 0 "nicht_betaetigt" 1 "Lenkradpaddle_betaetigt" ;
VAL_ 1522 KBI_Phototransistor 254 "Init" 255 "Fehler" ;
VAL_ 1522 KBI_Dimmpoti 126 "Nicht verfügbar" 127 "Fehler" ;
VAL_ 1167 SK1_Key_Data_10 0 "Init" ;
VAL_ 201 SM_Parken_Touch_PosX 0 "X_Pos_0" 1 "X_Pos_1" 2 "X_Pos_2" 3 "X_Pos_3" 4 "X_Pos_4" 5 "X_Pos_5" 6 "X_Pos_6" 7 "X_Pos_7" ;
VAL_ 201 SM_Parken_Touch_PosY 0 "Y_Pos_0" 1 "Y_Pos_1" 2 "Y_Pos_2" 3 "Y_Pos_3" 4 "Y_Pos_4" 5 "Y_Pos_5" 6 "Y_Pos_6" 7 "Y_Pos_7" 8 "Y_Pos_8" 9 "Y_Pos_9" 10 "Y_Pos_10" 11 "Y_Pos_11" 12 "Y_Pos_12" 13 "Y_Pos_13" 14 "Y_Pos_14" 15 "Y_Pos_15" 16 "Y_Pos_16" 17 "Y_Pos_17" 18 "Y_Pos_18" 19 "Y_Pos_19" 20 "Y_Pos_20" 21 "Y_Pos_21" 22 "Y_Pos_22" 23 "Y_Pos_23" 24 "Y_Pos_24" 25 "Y_Pos_25" 26 "Y_Pos_26" 27 "Y_Pos_27" 28 "Y_Pos_28" 29 "Y_Pos_29" 30 "Y_Pos_30" 31 "Keine_Eingabe_oder_Init" ;
VAL_ 201 SM_ARA_Gangwahl 0 "keine_Anforderung" 1 "P" 2 "R" 3 "N" 4 "D" ;
VAL_ 201 SM_Fehlerstatus 0 "Kein_Fehler_erkannt_oder_Init" 1 "Fehler_erkannt" ;
VAL_ 201 SM_ARA_Start 0 "No_Request" 1 "Request" ;
VAL_ 201 SM_ARA_Trajektorienmodus 0 "Trajektorienmodus_inaktiv" 1 "Trajektorienmodus_aktiv" ;
VAL_ 201 SM_AFR_Verbindungsstatus 0 "Not_Connected" 1 "Connected" ;
VAL_ 201 SM_Anlernstatus 0 "Keine_Geraete_gespeichert" 1 "Geraete_gespeichert" ;
VAL_ 201 SM_Parken_01_Sendestatus 0 "langsamer_Zyklus" 1 "schneller_Zyklus" ;
VAL_ 201 SM_Parken_AngefordertesRemoteSys 0 "kein_System_aktiv" 1 "RPAe_aktiv" 2 "AAA_aktiv" 3 "TPA_aktiv" ;
VAL_ 201 SM_Parken_Motorstart_Anf 0 "No_Request" 1 "Request" ;
VAL_ 201 SM_AFR_Standfkt_Anf 0 "Keine_Anforderung" 1 "Bereitschaft_herstellen_bzw_beibehalten" 2 "Fahrzeug_anheben_ausfuehren" 3 "Fahrzeug_absenken_ausfuehren" 4 "Standfunktion_3_ausfuehren" 5 "Standfunktion_4_ausfuehren" 6 "Standfunktion_5_ausfuehren" 7 "Standfunktion_6_ausfuehren" ;
VAL_ 201 SM_ARA_Nothalt 0 "Kein_Nothalt_angefordert" 1 "Nothalt_angefordert" ;
VAL_ 201 SM_App_Sperrzustand 0 "Undefined" 1 "Button_not_pressed" 2 "Button_pressed" 3 "Car_Wakeup" ;
VAL_ 201 SM_Parken_Manoever 0 "Init" 1 "Einparken" 2 "Ausparken" ;
VAL_ 201 SM_Parken_Szenario 0 "Init" 1 "Parallel" 2 "Perpendicular" 3 "Garage" 4 "Basic" 5 "Custom_Drive" 6 "TPA" 7 "AAA" ;
VAL_ 201 SM_Parken_Seite 0 "Init" 1 "Left" 2 "Right" 3 "Straight" ;
VAL_ 201 SM_Parken_Richtung 0 "Init" 1 "Forward" 2 "Backward" ;
VAL_ 201 SM_ARA_Status_Steuersignal 0 "Not_Ready" 1 "Ready" ;
VAL_ 201 SM_ARA_Knickwinkel_Soll 254 "Init" 255 "Fehler" ;
VAL_ 201 SM_Parken_Verbindungsstatus 0 "Not_Connected" 1 "Connected_ID_1" 2 "Connected_ID_2" 3 "Connected_ID_3" 4 "Connected_ID_4" 5 "Connected_ID_5" 6 "Connected_ID_6" 7 "Connected_ID_7" 8 "Connected_ID_8" 9 "Connected_ID_9" 10 "Connected_ID_10" 11 "Connected_ID_11" 12 "Connected_ID_12" 13 "Connected_ID_13" 14 "Connected_ID_14" 15 "Connected_ID_15" ;
VAL_ 201 SM_Parken_Kommando 0 "Stop" 1 "Drive_1" 2 "Drive_2" 3 "Custom_Finish" ;
VAL_ 201 SM_Parken_Kommando_invers 0 "Custom_Finish" 1 "Drive_2" 2 "Drive_1" 3 "Stop" ;
VAL_ 2527679651 SM_Parken_blinken 0 "aus" 1 "links" 2 "rechts" 3 "warnblinken" ;
VAL_ 2527679651 SM_Parken_Hupe_Anf 0 "Keine_Anforderung" 1 "Hupen" ;
VAL_ 2527679651 SM_Parken_UGDO_Anf 0 "Keine_Anforderung" 1 "Garage_1" 2 "Garage_2" 3 "Garage_3" 4 "Garage_4" 5 "Garage_5" 6 "Garage_6" 7 "Garage_7" 8 "Garage_8" 9 "Garage_9" 10 "Garage_10" 11 "Garage_11" 12 "Garage_12" 13 "Garage_13" 14 "Garage_14" 15 "Garage_15" ;
VAL_ 2527679651 SM_Parken_UGDO_Aktion 0 "Keine_Anforderung" 1 "Garage_oeffnen_oder_toggeln" 2 "Garage_schliessen" 3 "Garage_stoppen" 4 "Status_Anfrage" ;
VAL_ 2527679651 SM_Parken_Komfortschliessen_Anf 0 "Keine_Anforderung" 1 "Komfortschliessen" ;
VAL_ 980 BH_Blinker_li 0 "nicht_betaetigt" 1 "Blinkerhebel_Pos_li_betaetigt" ;
VAL_ 980 BH_Blinker_re 0 "nicht_betaetigt" 1 "Blinkerhebel_Pos_re_betaetigt" ;
VAL_ 980 BH_Lichthupe 0 "nicht_betaetigt" 1 "Blinkerhebel in Richtung Lichthupe betaetigt" ;
VAL_ 980 BH_Fernlicht 0 "nicht_betaetigt" 1 "Blinkerhebel_in_Richtung_Fernlicht_betaetigt" ;
VAL_ 980 WH_Tipwischen 0 "nicht_betaetigt" 1 "betaetigt" ;
VAL_ 980 WH_Intervall 0 "aus" 1 "Wischerhebel in Stellung Intervall" ;
VAL_ 980 WH_WischerStufe1 0 "aus" 1 "Wischerhebel in Stufe Wischen 1" ;
VAL_ 980 WH_WischerStufe2 0 "aus" 1 "Wischerhebel in Stufe Wischen 2" ;
VAL_ 980 WH_Frontwaschen 0 "aus" 1 "Wischerhebel in Stellung Wisch Wasch vorne" ;
VAL_ 980 WH_Heckintervall 0 "nicht_betaetigt" 1 "Wischerhebel in Stellung Heckintervall" ;
VAL_ 980 WH_Heckwaschen 0 "nicht_betaetigt" 1 "Wischerhebel in Stellung Wisch Wasch hinten" ;
VAL_ 980 WH_Intervallstufen 0 "Init / Default" 1 "Intervallstufe 1" 5 "Intervallstufe 2" 9 "Intervallstufe 3" 13 "Intervallstufe 4" 15 "Fehler" ;
VAL_ 980 FAS_Taster 0 "nicht_betaetigt" 1 "betaetigt" ;
VAL_ 980 FAS_Taster_Fehler 0 "kein_Fehler" 1 "Fehler" ;
VAL_ 980 SMLS_Hupe 0 "nicht_betaetigt" 1 "Hupe_gedrueckt" ;
VAL_ 980 LRH_On_Off 0 "LRH_aus__keine Anzeige" 1 "LRH_aus" 2 "LRH_ein" 3 "Fehler" ;
VAL_ 980 LSS_Tastencode 0 "Key_Released__No_Key" 4 "Up" 5 "Down" 7 "OK__ThumbWheel_Button" ;
VAL_ 980 LRH_aktiv 0 "inaktiv" 1 "aktiv" ;
VAL_ 980 SMLS_P_verriegelt 0 "Init" 1 "nicht_verriegelt" 2 "verriegelt" 3 "Fehler" ;
VAL_ 980 SMLS_P_verriegelt_plausibel 0 "unplausibel" 1 "plausibel" ;
VAL_ 980 WH_SRA 0 "SRA_Aus" 1 "SRA_Ein" ;
VAL_ 980 WH_Wischer_Fehler 0 "kein_Fehler" 1 "Fehler" ;
VAL_ 980 BH_Blinker_Fehler 0 "kein_Fehler" 1 "Fehler" ;
VAL_ 980 SMLS_PTT 0 "nicht_betaetigt" 1 "PTT_gedrueckt" ;
VAL_ 980 WH_Tipwischen_lang 0 "nicht_betaetigt" 1 "betaetigt" ;
VAL_ 2589283756 SOK_ungeschuetzte_Zeit 0 "Init" ;
VAL_ 1467 SoSe_SunInt_2D_Li 254 "Init" 255 "Fehler" ;
VAL_ 1467 SoSe_SunInt_2D_Re 254 "Init" 255 "Fehler" ;
VAL_ 1710 SP_FT_oben 0 "nicht_betaetigt" 1 "betaetigt" ;
VAL_ 1710 SP_FT_unten 0 "nicht_betaetigt" 1 "betaetigt" ;
VAL_ 1710 SP_FT_links 0 "nicht_betaetigt" 1 "betaetigt" ;
VAL_ 1710 SP_FT_rechts 0 "nicht_betaetigt" 1 "betaetigt" ;
VAL_ 1710 SP_BT_oben 0 "nicht_betaetigt" 1 "betaetigt" ;
VAL_ 1710 SP_BT_unten 0 "nicht_betaetigt" 1 "betaetigt" ;
VAL_ 1710 SP_BT_links 0 "nicht_betaetigt" 1 "betaetigt" ;
VAL_ 1710 SP_BT_rechts 0 "nicht_betaetigt" 1 "betaetigt" ;
VAL_ 1710 SP_abklappen 0 "Spiegel_abklappen_nicht_aktiv" 1 "Spiegel_abklappen_aktiv" ;
VAL_ 1710 SP_anklappen 0 "Spiegle_anklappen_nicht_aktiv" 1 "Spiegel_anklappen_aktiv" ;
VAL_ 1710 SP_normieren 0 "Spiegel_nicht_normiert" 1 "Spiegel_normiert" ;
VAL_ 1710 SP_Spg_Verstellschalter_Fehler 0 "kein_Fehler" 1 "Fehler" ;
VAL_ 1710 SP_Hzg_Taster 0 "nicht_betaetigt" 1 "betaetigt" ;
VAL_ 1710 SP_S_oben 1 "Spiegelschalter in Stellung oben" ;
VAL_ 1710 SP_S_unten 1 "Spiegelschalter in Stellung unten" ;
VAL_ 1710 SP_S_links 1 "Spiegelschalter in Stellung links" ;
VAL_ 1710 SP_S_rechts 1 "Spiegelschalter in Stellung rechts" ;
VAL_ 1710 SP_Auswahl_li 1 "Spiegelschalter in Stellung Auswahl links" ;
VAL_ 1710 SP_Auswahl_re 1 "Spiegelschalter in Stellung Auswahl rechts" ;
VAL_ 1710 SP_ARA_Status 0 "TSG nicht im ARA-Modus" 1 "TSG im ARA-Modus" ;
VAL_ 1710 SP_S_Klappen 1 "Spiegelschalter in Stellung Klappen" ;
VAL_ 1710 SP_Verstellschalter_Fehler 0 "kein_Fehler" 1 "Fehler" ;
VAL_ 2463978603 SSA_HD_Beeper_ansteuern 0 "nicht_angefordert" 1 "Sound_1_anfordern" 2 "Sound_2_anfordern" 3 "Sound_3_anfordern" 4 "Sound_4_anfordern" 5 "Sound_5_anfordern" 6 "Sound_6_anfordern" ;
VAL_ 2463978603 SSA_HD_ansteuern 0 "nicht_angefordert" 1 "oeffnen" 2 "schliessen" 3 "stop" ;
VAL_ 2463978603 SSA_Heckrollo_ansteuern 0 "nicht_angefordert" 1 "ausfahren" 2 "einfahren" ;
VAL_ 2463978603 SSA_LRA_ansteuern 0 "nicht_angefordert" 1 "oeffnen" 2 "schliessen" ;
VAL_ 2463978603 SSA_SD_Versorgung_ansteuern 0 "nicht_angefordert" 1 "einschalten" 2 "ausschalten" ;
VAL_ 2463978603 SSA_BFT_ASW_ansteuern 0 "nicht ansteuern" 1 "InfoStufe" 2 "Warnstufe" ;
VAL_ 2463978603 SSA_HBFT_SSR_ansteuern 0 "nicht_angefordert" 1 "oeffnen" 2 "schliessen" ;
VAL_ 2463978603 SSA_FT_ZZH_ansteuern 0 "nicht_angefordert" 1 "Zuziehen" 2 "AbbruchRuecklauf" ;
VAL_ 2463978603 KFT_FH_BT_hoch 0 "keine_Anforderung" 1 "BT_hoch" ;
VAL_ 2463978603 KFT_FH_BT_tief 0 "keine_Anforderung" 1 "BT_tief" ;
VAL_ 2463978603 KFT_FH_FT_hoch 0 "keine_Anforderung" 1 "FT_hoch" ;
VAL_ 2463978603 KFT_FH_FT_tief 0 "keine_Anforderung" 1 "FT_tief" ;
VAL_ 2463978603 KFT_FH_HBFS_hoch 0 "inaktiv" 1 "aktiv" ;
VAL_ 2463978603 KFT_FH_HBFS_tief 0 "inaktiv" 1 "aktiv" ;
VAL_ 2463978603 KFT_FH_HFS_hoch 0 "inaktiv" 1 "aktiv" ;
VAL_ 2463978603 KFT_FH_HFS_tief 0 "inaktiv" 1 "aktiv" ;
VAL_ 2463978603 KFT_Rollo_zu 0 "inaktiv" 1 "aktiv" ;
VAL_ 2463978603 KFT_Rollo_auf 0 "inaktiv" 1 "aktiv" ;
VAL_ 2463978603 KFT_SAD_zu 0 "inaktiv" 1 "aktiv" ;
VAL_ 2463978603 KFT_SAD_auf 0 "inaktiv" 1 "aktiv" ;
VAL_ 2463978603 KFT_FH_Freigabe 1 "Funktionsfreigabe Fensterheber" ;
VAL_ 2463978603 KFT_Komfortfkt_Freigabe 0 "Komfortfunktion gesperrt" 1 "globale Freigabe der Komfortfunktion erteilt" ;
VAL_ 2463978603 KFT_Verdeck_auf 0 "inaktiv" 1 "aktiv" ;
VAL_ 2463978603 KFT_Verdeck_zu 0 "inaktiv" 1 "aktiv" ;
VAL_ 2463978603 KFT_Verdeck_Freigabe 0 "Verdeckbetrieb nicht erlaubt" 1 "Verdeckbetrieb erlaubt" ;
VAL_ 2463978603 SSA_BFT_ASP_Klappung_ansteuern 0 "nicht angefordert" 1 "anklappen (Garagenstellung)" 2 "abklappen (Fahrtstellung)" ;
VAL_ 2463978603 SSA_FT_ASW_ansteuern 0 "nicht ansteuern" 1 "InfoStufe" 2 "Warnstufe" ;
VAL_ 2463978603 SSA_FT_FH_ansteuern 125 "nicht_angefordert" ;
VAL_ 2463978603 SSA_BFT_FH_ansteuern 125 "nicht_angefordert" ;
VAL_ 2463978603 SSA_BFT_FH_Pos_anfahren 255 "Fehler" ;
VAL_ 2463978603 SSA_SAD_Deckel1_ansteuern 125 "keine_Ansteuerung_Init" ;
VAL_ 2463978603 SSA_SAD_Rollo1_ansteuern 125 "Keine_Ansteuerung" ;
VAL_ 2463978603 SSA_Heckrollo_PrivacySAD_Rollo1 125 "Keine_Ansteuerung" ;
VAL_ 2463978603 SSA_Heckrollo_PrivacySAD_Rollo2 125 "Keine_Ansteuerung" ;
VAL_ 2463978603 Privacy_SAD_Rollo1_ansteuern 125 "Keine_Ansteuerung" ;
VAL_ 2463978603 Privacy_SAD_Rollo2_ansteuern 125 "Keine_Ansteuerung" ;
VAL_ 2463978603 SSA_BFT_ASP_SpglGlas_ansteuern 0 "nicht_angefordert" 1 "Verstellung_Links_X" 2 "Verstellung_Rechts_X" 3 "Verstellung_Tief_Y" 4 "Verstellung_Hoch_Y" 5 "Bordsteinautom_deaktiviert" 6 "Bordsteinautom_aktiviert" ;
VAL_ 2463978603 SSA_FT_ASP_SpglGlas_ansteuern 0 "nicht_angefordert" 1 "Verstellung_Links_X" 2 "Verstellung_Rechts_X" 3 "Verstellung_Tief_Y" 4 "Verstellung_Hoch_Y" 5 "Bordsteinautom_deaktiviert" 6 "Bordsteinautom_aktiviert" ;
VAL_ 2463978603 SSA_FT_ZV_Ansteuern 0 "Init" 1 "entriegelnentsafen" 2 "verriegelnentsafen" 3 "verriegelnsafen" 255 "Fehler" ;
VAL_ 2463978603 SSA_HBFT_FH_ansteuern 125 "nicht_angefordert" ;
VAL_ 2463978603 SSA_HFT_FH_ansteuern 125 "nicht_angefordert" ;
VAL_ 2463978603 SSA_FT_el_Tuerantrieb_ansteuern 0 "nicht_ansteuern" 1 "auffahren" 2 "zufahren" 3 "stoppen" 4 "Notstopp" 5 "Signal_5" 6 "Signal_6" 7 "Signal_7" 8 "Signal_8" 9 "Signal_9" 10 "Signal_10" 11 "Signal_11" 12 "Signal_12" 13 "Signal_13" 14 "Signal_14" 15 "Signal_15" ;
VAL_ 1313 STH_Funk_ein 0 "kein Funkbefehl zum Einschalten" 1 "Funkbefehl zum Einschalten erhalten" ;
VAL_ 1313 STH_Funk_aus 0 "kein Funkbefehl" 1 "Funkbefehl zum Ausschalten erhalten" ;
VAL_ 1313 STH_Zusatzheizung 0 "Zuheizer aus" 1 "Zuheizer ein" ;
VAL_ 1313 STH_LED 0 "keine Rückmeldung" 1 "Rueckmeldung Standheizung in Betrieb" ;
VAL_ 1313 STH_Geblaese 0 "kein Einschaltbefehl an die Klimaanlage, Gebläse" 1 "Einschaltbefehl an die Klimaanlage, Gebläse" ;
VAL_ 1313 STH_EKP_Anst 0 "EKP nicht ansteuern" 1 "EKP ansteuern" ;
VAL_ 1313 STH_Start_folgt 0 "kein_Start_folgt" 1 "Start_folgt" ;
VAL_ 1313 STH_Ventil_Status 0 "Ventil_offen__grosser_Kreislauf" 1 "Ventil_geschlossen__kleiner_Kreislauf" ;
VAL_ 1313 STH_Fehler_ElWaPu 0 "kein_Fehler" 1 "Fehler" ;
VAL_ 1313 STH_Pumpen_Anf_extern 0 "nicht_angefordert" 1 "angefordert" ;
VAL_ 1313 STH_KL_HUP 0 "Aus" 1 "Ein" ;
VAL_ 1313 STH_Fehlerstatus 0 "kein_Fehler" 1 "Unterspannung" 2 "Tankfuellstand_zu_gering" 3 "Fehler_Betrieb_verhindert" 4 "Heizgeraet_verriegelt" 5 "Fehler_Betrieb_nicht_verhindert" 6 "Emissionsüberschreitung" ;
VAL_ 1313 STH_Wassertemp 254 "Init" 255 "Fehler" ;
VAL_ 1313 STH_Texte 0 "keine_Anzeige" 1 "Batteriemanagementeinschraenkung" 2 "Kraftstoffmangel" 3 "interner_Systemfehler" 4 "Heizzeitueberschreitung" ;
VAL_ 1313 STH_Motorvorwaermung 0 "keine Motorvorwärmung erfolgt" 1 "Aufheizung mit Motorvorwärmung erfolgt" ;
VAL_ 1313 STH_Servicemode 0 "Servicemode nicht aktiv" 1 "Servicemode aktiv" ;
VAL_ 1313 STH_war_aktiv 0 "war inaktiv" 1 "Standheizung war letzte halbe Stunde aktiv" ;
VAL_ 1313 STH_KVS_Ueberlauf 0 "kein Überlauf" 1 "Kraftstoffverbrauchssignal, mindestens ein Überlauf hat stattgefunden" ;
VAL_ 1313 STH_SH_ZH 0 "Heizgeraet_WZH" 1 "Heizgeraet_ZH" ;
VAL_ 832 STSG_HBFS_Status_Feststeller 0 "geloest" 1 "festgestellt" ;
VAL_ 832 STSG_HBFS_TIG_bet_schliessen 0 "nicht_betaetigt" 1 "betaetigt" ;
VAL_ 832 STSG_HBFS_TIG_bet_oeffnen 0 "nicht_betaetigt" 1 "betaetigt" ;
VAL_ 832 STSG_HBFS_FFB_Taste_Schiebtuer 0 "nicht_betaetigt" 1 "betaetigt" ;
VAL_ 832 STSG_HBFS_TAG_betaetigt 0 "nicht_betaetigt" 1 "betaetigt" ;
VAL_ 832 STSG_HBFS_Tuer_Sperrklinke 0 "nicht_in_Vorraste" 1 "in_Vorraste" ;
VAL_ 832 STSG_HBFS_entriegeln_anfordern 0 "nicht_anfordern" 1 "anfordern" ;
VAL_ 832 STSG_HBFS_Tuer_Vorraste 0 "nicht_in_Vorraste" 1 "in_Vorraste" ;
VAL_ 832 STSG_HBFS_Thermo_aktiv 0 "inaktiv" 1 "aktiv" ;
VAL_ 832 STSG_HBFS_Bew_zu 0 "schliesst_nicht_und_steht" 1 "schliesst" ;
VAL_ 832 STSG_HBFS_Bew_auf 0 "oeffnet_nicht_und_steht" 1 "oeffnet" ;
VAL_ 832 STSG_HBFS_EOE_aktiv 0 "nicht_angesteuert" 1 "angesteuert" ;
VAL_ 832 STSG_HBFS_ZZH_Status_zu 0 "ZZH_steht" 1 "ZZH_zieht_zu" ;
VAL_ 832 STSG_HBFS_ZZH_Status_auf 0 "ZZH_steht" 1 "ZZH_faehrt_aus" ;
VAL_ 832 STSG_HBFS_ZZH_Initialisierung 0 "Zuziehen_beendet" 1 "STSG_will_zuziehen" ;
VAL_ 832 STSG_HBFS_ZZH_Freigabe 0 "keine_Freigabe" 1 "Freigabe" ;
VAL_ 832 STSG_HBFS_UEKB_aktiv 0 "inaktiv" 1 "aktiv" ;
VAL_ 832 STSG_HBFS_Einklemm_defekt 0 "iO" 1 "defekt" ;
VAL_ 832 STSG_HBFS_Einklemm_aktiv 0 "inaktiv" 1 "aktiv" ;
VAL_ 832 STSG_HBFS_TAT 0 "nicht_betaetigt" 1 "betaetigt" ;
VAL_ 832 STSG_HBFS_ST_deaktivieren 0 "inaktiv" 1 "aktiv" ;
VAL_ 832 STSG_HBFS_BTF 0 "nicht_betaetigt" 1 "betaetigt" ;
